VERSION ""

NS_ :

BS_:

BU_: FLZCU_VCU_EP FLZCU_PDCS_EP FLZCU_EP VCU_EP FLZCU_SignalRoute_EP BMS CDU FMCU_ISG FMCU ISG RMCU RMCU_E0V EVCC PDCS_EP PDCS_EP_E0V CIC_EP RmcuCdu RmcuCdu_E0V FmcuVcu_EP FmcuVcu_EP_E0V

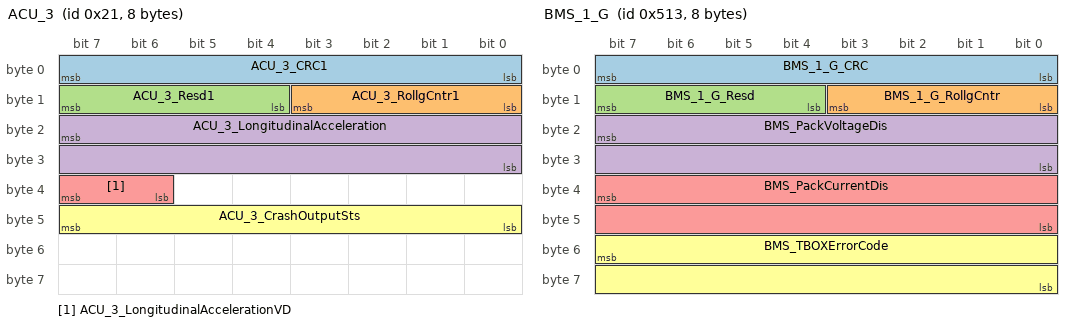
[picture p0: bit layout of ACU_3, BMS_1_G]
BO_ 33 ACU_3: 8 Vector__XXX
 SG_ ACU_3_CRC1 : 7|8@0+ (1,0) [0|255] ""  BMS,FMCU_ISG,FMCU,ISG,RMCU,RMCU_E0V,RmcuCdu,RmcuCdu_E0V,FmcuVcu_EP,FmcuVcu_EP_E0V
 SG_ ACU_3_RollgCntr1 : 11|4@0+ (1,0) [0|14] ""  BMS,FMCU_ISG,FMCU,ISG,RMCU,RMCU_E0V,RmcuCdu,RmcuCdu_E0V,FmcuVcu_EP,FmcuVcu_EP_E0V
 SG_ ACU_3_Resd1 : 15|4@0+ (1,0) [0|15] ""  BMS,FMCU_ISG,FMCU,ISG,RMCU,RMCU_E0V,RmcuCdu,RmcuCdu_E0V,FmcuVcu_EP,FmcuVcu_EP_E0V
 SG_ ACU_3_LongitudinalAcceleration : 23|16@0+ (0.001,-2) [-2|2] "g"  RMCU,RMCU_E0V,RmcuCdu,RmcuCdu_E0V
 SG_ ACU_3_LongitudinalAccelerationVD : 39|2@0+ (1,0) [0|3] ""  RMCU,RMCU_E0V,RmcuCdu,RmcuCdu_E0V
 SG_ ACU_3_CrashOutputSts : 47|8@0+ (1,0) [0|255] ""  BMS,FMCU_ISG,FMCU,ISG,RMCU,RMCU_E0V,RmcuCdu,RmcuCdu_E0V,FmcuVcu_EP,FmcuVcu_EP_E0V

BO_ 1299 BMS_1_G: 8 BMS
 SG_ BMS_1_G_CRC : 7|8@0+ (1,0) [0|255] ""  Vector__XXX
 SG_ BMS_1_G_RollgCntr : 11|4@0+ (1,0) [0|14] ""  Vector__XXX
 SG_ BMS_1_G_Resd : 15|4@0+ (1,0) [0|15] ""  Vector__XXX
 SG_ BMS_PackVoltageDis : 23|16@0+ (0.1,0.0) [0|1000] "volt (V)"  RMCU,RMCU_E0V,RmcuCdu,RmcuCdu_E0V
 SG_ BMS_PackCurrentDis : 39|16@0+ (0.1,-2047) [-2047|2047] "ampere (A)"  Vector__XXX
 SG_ BMS_TBOXErrorCode : 55|16@0+ (1,0) [0|65535] ""  Vector__XXX

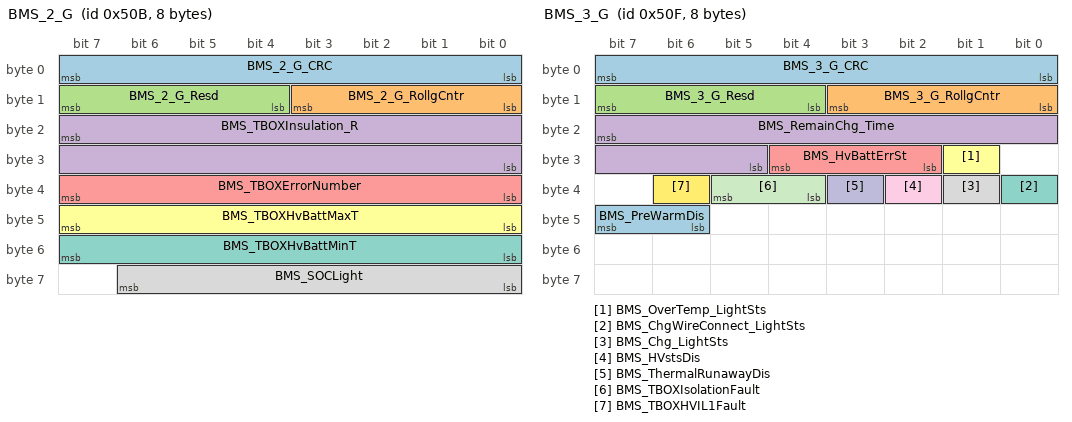
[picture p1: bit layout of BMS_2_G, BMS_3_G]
BO_ 1291 BMS_2_G: 8 BMS
 SG_ BMS_2_G_CRC : 7|8@0+ (1,0) [0|255] ""  Vector__XXX
 SG_ BMS_2_G_RollgCntr : 11|4@0+ (1,0) [0|14] ""  Vector__XXX
 SG_ BMS_2_G_Resd : 15|4@0+ (1,0) [0|15] ""  Vector__XXX
 SG_ BMS_TBOXInsulation_R : 23|16@0+ (1,0) [0|60000] "kiloohm (k��)"  Vector__XXX
 SG_ BMS_TBOXErrorNumber : 39|8@0+ (1,0) [0|255] ""  Vector__XXX
 SG_ BMS_TBOXHvBattMaxT : 47|8@0+ (1,-40) [-40|210] "grad celsius (��C)"  Vector__XXX
 SG_ BMS_TBOXHvBattMinT : 55|8@0+ (1,-40) [-40|210] "grad celsius (��C)"  Vector__XXX
 SG_ BMS_SOCLight : 62|7@0+ (1,0) [0|100] "%"  FLZCU_VCU_EP,FLZCU_PDCS_EP,FLZCU_EP

BO_ 1295 BMS_3_G: 8 BMS
 SG_ BMS_3_G_CRC : 7|8@0+ (1,0) [0|255] ""  CIC_EP
 SG_ BMS_3_G_RollgCntr : 11|4@0+ (1,0) [0|14] ""  CIC_EP
 SG_ BMS_3_G_Resd : 15|4@0+ (1,0) [0|15] ""  CIC_EP
 SG_ BMS_RemainChg_Time : 23|11@0+ (1,0) [0|2047] "min"  Vector__XXX
 SG_ BMS_HvBattErrSt : 28|3@0+ (1,0.0) [0|7] ""  Vector__XXX
 SG_ BMS_OverTemp_LightSts : 25|1@0+ (1,0) [0|1] ""  Vector__XXX
 SG_ BMS_ChgWireConnect_LightSts : 32|1@0+ (1,0) [0|1] ""  CIC_EP
 SG_ BMS_Chg_LightSts : 33|1@0+ (1,0) [0|1] ""  FLZCU_VCU_EP,FLZCU_PDCS_EP,FLZCU_EP
 SG_ BMS_HVstsDis : 34|1@0+ (1,0) [0|1] ""  Vector__XXX
 SG_ BMS_ThermalRunawayDis : 35|1@0+ (1,0) [0|1] ""  Vector__XXX
 SG_ BMS_TBOXIsolationFault : 37|2@0+ (1,0) [0|3] ""  Vector__XXX
 SG_ BMS_TBOXHVIL1Fault : 38|1@0+ (1,0) [0|1] ""  Vector__XXX
 SG_ BMS_PreWarmDis : 47|2@0+ (1,0) [0|2] ""  Vector__XXX

BO_ 258 BMS_1: 48 BMS
 SG_ BMS_1_CRC1 : 7|8@0+ (1,0) [0|255] ""  FLZCU_VCU_EP,FLZCU_PDCS_EP,VCU_EP,RMCU,RMCU_E0V,PDCS_EP,PDCS_EP_E0V,RmcuCdu,RmcuCdu_E0V,FmcuVcu_EP,FmcuVcu_EP_E0V
 SG_ BMS_1_RollgCntr1 : 11|4@0+ (1,0) [0|14] ""  FLZCU_VCU_EP,FLZCU_PDCS_EP,VCU_EP,RMCU,RMCU_E0V,PDCS_EP,PDCS_EP_E0V,RmcuCdu,RmcuCdu_E0V,FmcuVcu_EP,FmcuVcu_EP_E0V
 SG_ BMS_1_Resd1 : 15|4@0+ (1,0) [0|15] ""  FLZCU_VCU_EP,FLZCU_PDCS_EP,VCU_EP,RMCU,RMCU_E0V,PDCS_EP,PDCS_EP_E0V,RmcuCdu,RmcuCdu_E0V,FmcuVcu_EP,FmcuVcu_EP_E0V
 SG_ BMS_PackVoltage : 23|16@0+ (0.1,0) [0|1000] "volt (V)"  FLZCU_VCU_EP,FLZCU_PDCS_EP,VCU_EP,RMCU,RMCU_E0V,PDCS_EP,PDCS_EP_E0V,RmcuCdu,RmcuCdu_E0V,FmcuVcu_EP,FmcuVcu_EP_E0V
 SG_ BMS_PackCurrent : 39|16@0+ (0.1,-2047) [-2047|2047] "ampere (A)"  FLZCU_VCU_EP,FLZCU_PDCS_EP,VCU_EP,PDCS_EP,PDCS_EP_E0V,FmcuVcu_EP,FmcuVcu_EP_E0V
 SG_ BMS_HvBattSts : 51|4@0+ (1,0) [0|15] ""  FLZCU_VCU_EP,FLZCU_PDCS_EP,VCU_EP,FLZCU_SignalRoute_EP,EVCC,PDCS_EP,PDCS_EP_E0V,FmcuVcu_EP,FmcuVcu_EP_E0V
 SG_ BMS_SysSelfCheck : 53|2@0+ (1,0) [0|3] ""  FLZCU_VCU_EP,FLZCU_PDCS_EP,VCU_EP,PDCS_EP,PDCS_EP_E0V,FmcuVcu_EP,FmcuVcu_EP_E0V
 SG_ BMS_HVBattThermRunaway : 55|2@0+ (1,0) [0|3] ""  FLZCU_VCU_EP,FLZCU_PDCS_EP,FLZCU_EP,VCU_EP,FLZCU_SignalRoute_EP,PDCS_EP,PDCS_EP_E0V,FmcuVcu_EP,FmcuVcu_EP_E0V
 SG_ BMS_1_CRC2 : 71|8@0+ (1,0) [0|255] ""  FLZCU_VCU_EP,FLZCU_PDCS_EP
 SG_ BMS_1_RollgCntr2 : 75|4@0+ (1,0) [0|14] ""  FLZCU_VCU_EP,FLZCU_PDCS_EP
 SG_ BMS_1_Resd2 : 79|4@0+ (1,0) [0|15] ""  FLZCU_VCU_EP,FLZCU_PDCS_EP
 SG_ BMS_DcDisChgCurrReq : 87|12@0+ (0.1,0) [0|400] ""  FLZCU_VCU_EP,FLZCU_PDCS_EP
 SG_ BMS_C2Target_Buck_Voltage : 91|16@0+ (0.1,0) [0|1000] "V"  FLZCU_VCU_EP,FLZCU_PDCS_EP,RMCU,RMCU_E0V
 SG_ BMS_DisChrgDcCnctrDetd : 107|4@0+ (1,0) [0|15] ""  FLZCU_VCU_EP,FLZCU_PDCS_EP
 SG_ BMS_InfraDcUActDc : 119|14@0+ (0.1,0) [0|1024] "volt (V)"  FLZCU_VCU_EP,FLZCU_PDCS_EP,VCU_EP,FLZCU_SignalRoute_EP,RMCU,RMCU_E0V,PDCS_EP,PDCS_EP_E0V,RmcuCdu,RmcuCdu_E0V,FmcuVcu_EP,FmcuVcu_EP_E0V
 SG_ BMS_1_CRC3 : 135|8@0+ (1,0) [0|255] ""  FLZCU_VCU_EP,FLZCU_PDCS_EP,VCU_EP,RMCU,RMCU_E0V,PDCS_EP,PDCS_EP_E0V,RmcuCdu,RmcuCdu_E0V,FmcuVcu_EP,FmcuVcu_EP_E0V
 SG_ BMS_1_RollgCntr3 : 139|4@0+ (1,0) [0|14] ""  FLZCU_VCU_EP,FLZCU_PDCS_EP,VCU_EP,RMCU,RMCU_E0V,PDCS_EP,PDCS_EP_E0V,RmcuCdu,RmcuCdu_E0V,FmcuVcu_EP,FmcuVcu_EP_E0V
 SG_ BMS_1_Resd3 : 143|4@0+ (1,0) [0|15] ""  FLZCU_VCU_EP,FLZCU_PDCS_EP,VCU_EP,RMCU,RMCU_E0V,PDCS_EP,PDCS_EP_E0V,RmcuCdu,RmcuCdu_E0V,FmcuVcu_EP,FmcuVcu_EP_E0V
 SG_ BMS_InfraDcIActDc : 151|14@0+ (0.1,-1024) [-1024|0] "ampere (A)"  FLZCU_VCU_EP,FLZCU_PDCS_EP,VCU_EP,FLZCU_SignalRoute_EP,RMCU,RMCU_E0V,PDCS_EP,PDCS_EP_E0V,RmcuCdu,RmcuCdu_E0V,FmcuVcu_EP,FmcuVcu_EP_E0V
 SG_ BMS_HvBattDynChrgnILim : 167|14@0+ (0.1,-1024) [-1024|0] "ampere (A)"  FLZCU_VCU_EP,FLZCU_PDCS_EP,VCU_EP,FLZCU_SignalRoute_EP,PDCS_EP,PDCS_EP_E0V,FmcuVcu_EP,FmcuVcu_EP_E0V
 SG_ BMS_HvBattUChrgnLim : 183|14@0+ (0.1,0) [0|1024] "volt (V)"  FLZCU_VCU_EP,FLZCU_PDCS_EP,VCU_EP,FLZCU_SignalRoute_EP,RMCU,RMCU_E0V,PDCS_EP,PDCS_EP_E0V,RmcuCdu,RmcuCdu_E0V,FmcuVcu_EP,FmcuVcu_EP_E0V
 SG_ BMS_1_CRC4 : 199|8@0+ (1,0) [0|255] ""  FLZCU_VCU_EP,FLZCU_PDCS_EP,VCU_EP,PDCS_EP,PDCS_EP_E0V,FmcuVcu_EP,FmcuVcu_EP_E0V
 SG_ BMS_1_RollgCntr4 : 203|4@0+ (1,0) [0|14] ""  FLZCU_VCU_EP,FLZCU_PDCS_EP,VCU_EP,PDCS_EP,PDCS_EP_E0V,FmcuVcu_EP,FmcuVcu_EP_E0V
 SG_ BMS_1_Resd4 : 207|4@0+ (1,0) [0|15] ""  FLZCU_VCU_EP,FLZCU_PDCS_EP,VCU_EP,PDCS_EP,PDCS_EP_E0V,FmcuVcu_EP,FmcuVcu_EP_E0V
 SG_ BMS_ChrgDcIAvl : 215|14@0+ (0.1,-1024) [-1024|0] "ampere (A)"  FLZCU_VCU_EP,FLZCU_PDCS_EP,VCU_EP,PDCS_EP,PDCS_EP_E0V,FmcuVcu_EP,FmcuVcu_EP_E0V
 SG_ BMS_DChrgAPlusSt : 217|1@0+ (1,0) [0|1] ""  FLZCU_VCU_EP,FLZCU_PDCS_EP,VCU_EP,PDCS_EP,PDCS_EP_E0V,FmcuVcu_EP,FmcuVcu_EP_E0V
 SG_ BMS_Insulation_R : 231|16@0+ (1,0) [0|60000] "kiloohm (k��)"  FLZCU_VCU_EP,FLZCU_PDCS_EP,VCU_EP,PDCS_EP,PDCS_EP_E0V,FmcuVcu_EP,FmcuVcu_EP_E0V
 SG_ BMS_ChrgDcCnctrDetd : 241|2@0+ (1,0) [0|3] ""  FLZCU_VCU_EP,FLZCU_PDCS_EP,FLZCU_EP,VCU_EP,FLZCU_SignalRoute_EP,PDCS_EP,PDCS_EP_E0V,FmcuVcu_EP,FmcuVcu_EP_E0V
 SG_ BMS_DCChgMode : 244|3@0+ (1,0) [0|7] ""  FLZCU_VCU_EP,FLZCU_PDCS_EP,VCU_EP,FLZCU_SignalRoute_EP,PDCS_EP,PDCS_EP_E0V,FmcuVcu_EP,FmcuVcu_EP_E0V
 SG_ BMS_ChrgDcChrgnFltStopReas : 247|3@0+ (1.0,0) [0|7] ""  FLZCU_VCU_EP,FLZCU_PDCS_EP,VCU_EP,PDCS_EP,PDCS_EP_E0V,FmcuVcu_EP,FmcuVcu_EP_E0V
 SG_ BMS_1_CRC5 : 263|8@0+ (1,0) [0|255] ""  FLZCU_VCU_EP,FLZCU_PDCS_EP,VCU_EP,PDCS_EP,PDCS_EP_E0V,FmcuVcu_EP,FmcuVcu_EP_E0V
 SG_ BMS_1_RollgCntr5 : 267|4@0+ (1,0) [0|14] ""  FLZCU_VCU_EP,FLZCU_PDCS_EP,VCU_EP,PDCS_EP,PDCS_EP_E0V,FmcuVcu_EP,FmcuVcu_EP_E0V
 SG_ BMS_1_Resd5 : 271|4@0+ (1,0) [0|15] ""  FLZCU_VCU_EP,FLZCU_PDCS_EP,VCU_EP,PDCS_EP,PDCS_EP_E0V,FmcuVcu_EP,FmcuVcu_EP_E0V
 SG_ BMS_ChgRemTime : 279|11@0+ (1,0) [0|1440] "min"  FLZCU_VCU_EP,FLZCU_PDCS_EP,VCU_EP,FLZCU_SignalRoute_EP,PDCS_EP,PDCS_EP_E0V,FmcuVcu_EP,FmcuVcu_EP_E0V
 SG_ BMS_ChargeRequest_Mode : 284|4@0+ (1,0) [0|15] ""  FLZCU_VCU_EP,FLZCU_PDCS_EP,VCU_EP,FLZCU_SignalRoute_EP,PDCS_EP,PDCS_EP_E0V,FmcuVcu_EP,FmcuVcu_EP_E0V
 SG_ BMS_StateOfChargeDis : 295|8@0+ (1,0) [0|100] "%"  FLZCU_VCU_EP,FLZCU_PDCS_EP,FLZCU_EP,VCU_EP,FLZCU_SignalRoute_EP,EVCC,PDCS_EP,PDCS_EP_E0V,FmcuVcu_EP,FmcuVcu_EP_E0V
 SG_ BMS_StateOfEnergy : 311|16@0+ (0.1,0) [0|999.9] "kWh"  FLZCU_VCU_EP,FLZCU_PDCS_EP,VCU_EP,PDCS_EP,PDCS_EP_E0V,FmcuVcu_EP,FmcuVcu_EP_E0V
 SG_ BMS_1_CRC6 : 327|8@0+ (1,0) [0|255] ""  FLZCU_VCU_EP,FLZCU_PDCS_EP,VCU_EP,PDCS_EP,PDCS_EP_E0V,FmcuVcu_EP,FmcuVcu_EP_E0V
 SG_ BMS_1_RollgCntr6 : 331|4@0+ (1,0) [0|14] ""  FLZCU_VCU_EP,FLZCU_PDCS_EP,VCU_EP,PDCS_EP,PDCS_EP_E0V,FmcuVcu_EP,FmcuVcu_EP_E0V
 SG_ BMS_1_Resd6 : 335|4@0+ (1,0) [0|15] ""  FLZCU_VCU_EP,FLZCU_PDCS_EP,VCU_EP,PDCS_EP,PDCS_EP_E0V,FmcuVcu_EP,FmcuVcu_EP_E0V
 SG_ BMS_StateOfHealth : 342|7@0+ (1,0) [0|100] ""  FLZCU_VCU_EP,FLZCU_PDCS_EP,VCU_EP,FLZCU_SignalRoute_EP,PDCS_EP,PDCS_EP_E0V,FmcuVcu_EP,FmcuVcu_EP_E0V
 SG_ BMS_BlanceState : 343|1@0+ (1,0) [0|1] ""  FLZCU_VCU_EP,FLZCU_PDCS_EP,VCU_EP,FLZCU_SignalRoute_EP,PDCS_EP,PDCS_EP_E0V,FmcuVcu_EP,FmcuVcu_EP_E0V
 SG_ BMS_IsolationFault : 345|2@0+ (1,0) [0|3] ""  FLZCU_VCU_EP,FLZCU_PDCS_EP,VCU_EP,FLZCU_SignalRoute_EP,PDCS_EP,PDCS_EP_E0V,FmcuVcu_EP,FmcuVcu_EP_E0V
 SG_ BMS_HVILFault_DC : 346|1@0+ (1,0) [0|1] ""  FLZCU_VCU_EP,FLZCU_PDCS_EP,VCU_EP,PDCS_EP,PDCS_EP_E0V,FmcuVcu_EP,FmcuVcu_EP_E0V
 SG_ BMS_HVILFault_FMCU : 347|1@0+ (1,0) [0|1] ""  FLZCU_VCU_EP,FLZCU_PDCS_EP,VCU_EP,PDCS_EP,PDCS_EP_E0V,FmcuVcu_EP,FmcuVcu_EP_E0V
 SG_ BMS_HVILFault_RMCU : 348|1@0+ (1,0) [0|1] ""  FLZCU_VCU_EP,FLZCU_PDCS_EP,VCU_EP,PDCS_EP,PDCS_EP_E0V,FmcuVcu_EP,FmcuVcu_EP_E0V
 SG_ BMS_SOCDis : 359|14@0+ (0.01,0) [0|100] "%"  FLZCU_VCU_EP,FLZCU_PDCS_EP,VCU_EP,PDCS_EP,PDCS_EP_E0V,FmcuVcu_EP,FmcuVcu_EP_E0V
 SG_ BMS_InfraDcIActDcMin : 375|14@0+ (0.1,-1024) [-1024|0] "ampere (A)"  FLZCU_VCU_EP,FLZCU_PDCS_EP,VCU_EP,PDCS_EP,PDCS_EP_E0V,FmcuVcu_EP,FmcuVcu_EP_E0V

BO_ 520 BMS_2: 48 BMS
 SG_ BMS_2_CRC1 : 7|8@0+ (1,0) [0|255] ""  FLZCU_VCU_EP,FLZCU_PDCS_EP,RMCU,RMCU_E0V,RmcuCdu,RmcuCdu_E0V
 SG_ BMS_2_RollgCntr1 : 11|4@0+ (1,0) [0|14] ""  FLZCU_VCU_EP,FLZCU_PDCS_EP,RMCU,RMCU_E0V,RmcuCdu,RmcuCdu_E0V
 SG_ BMS_2_Resd1 : 15|4@0+ (1,0) [0|15] ""  FLZCU_VCU_EP,FLZCU_PDCS_EP,RMCU,RMCU_E0V,RmcuCdu,RmcuCdu_E0V
 SG_ BMS_C2Target_Chg_Voltage : 23|16@0+ (0.1,0) [0|1000] "V"  FLZCU_VCU_EP,FLZCU_PDCS_EP,VCU_EP,RMCU,RMCU_E0V,PDCS_EP,PDCS_EP_E0V,RmcuCdu,RmcuCdu_E0V,FmcuVcu_EP,FmcuVcu_EP_E0V
 SG_ BMS_CHGstation_MAXPwr : 39|8@0+ (2,0) [0|510] "KW"  FLZCU_VCU_EP,FLZCU_PDCS_EP,VCU_EP,PDCS_EP,PDCS_EP_E0V,FmcuVcu_EP,FmcuVcu_EP_E0V
 SG_ BMS_2_CRC2 : 71|8@0+ (1,0) [0|255] ""  FLZCU_VCU_EP,FLZCU_PDCS_EP,VCU_EP,CDU,PDCS_EP,PDCS_EP_E0V,RmcuCdu,RmcuCdu_E0V,FmcuVcu_EP,FmcuVcu_EP_E0V
 SG_ BMS_2_RollgCntr2 : 75|4@0+ (1,0) [0|14] ""  FLZCU_VCU_EP,FLZCU_PDCS_EP,VCU_EP,CDU,PDCS_EP,PDCS_EP_E0V,RmcuCdu,RmcuCdu_E0V,FmcuVcu_EP,FmcuVcu_EP_E0V
 SG_ BMS_2_Resd2 : 79|4@0+ (1,0) [0|15] ""  FLZCU_VCU_EP,FLZCU_PDCS_EP,VCU_EP,CDU,PDCS_EP,PDCS_EP_E0V,RmcuCdu,RmcuCdu_E0V,FmcuVcu_EP,FmcuVcu_EP_E0V
 SG_ BMS_NV_relay_Sts : 84|3@0+ (1,0) [0|6] ""  FLZCU_VCU_EP,FLZCU_PDCS_EP,VCU_EP,CDU,PDCS_EP,PDCS_EP_E0V,RmcuCdu,RmcuCdu_E0V,FmcuVcu_EP,FmcuVcu_EP_E0V
 SG_ BMS_PV_relay_Sts : 87|3@0+ (1,0) [0|6] ""  FLZCU_VCU_EP,FLZCU_PDCS_EP,VCU_EP,CDU,PDCS_EP,PDCS_EP_E0V,RmcuCdu,RmcuCdu_E0V,FmcuVcu_EP,FmcuVcu_EP_E0V
 SG_ BMS_QCP_relay_Sts : 90|3@0+ (1,0) [0|6] ""  FLZCU_VCU_EP,FLZCU_PDCS_EP,VCU_EP,CDU,PDCS_EP,PDCS_EP_E0V,RmcuCdu,RmcuCdu_E0V,FmcuVcu_EP,FmcuVcu_EP_E0V
 SG_ BMS_QCN_relay_Sts : 93|3@0+ (1,0) [0|6] ""  FLZCU_VCU_EP,FLZCU_PDCS_EP,VCU_EP,CDU,PDCS_EP,PDCS_EP_E0V,RmcuCdu,RmcuCdu_E0V,FmcuVcu_EP,FmcuVcu_EP_E0V
 SG_ BMS_HvBattThermReqLevel : 81|4@0+ (1,0) [0|15] ""  FLZCU_VCU_EP,FLZCU_PDCS_EP,VCU_EP,FLZCU_SignalRoute_EP,PDCS_EP,PDCS_EP_E0V,FmcuVcu_EP,FmcuVcu_EP_E0V
 SG_ BMS_Prechage_relay_Sts : 98|3@0+ (1,0) [0|6] ""  FLZCU_VCU_EP,FLZCU_PDCS_EP,VCU_EP,PDCS_EP,PDCS_EP_E0V,FmcuVcu_EP,FmcuVcu_EP_E0V
 SG_ BMS_HvBattThermReqMode : 103|4@0+ (1,0) [0|15] ""  FLZCU_VCU_EP,FLZCU_PDCS_EP,VCU_EP,FLZCU_SignalRoute_EP,PDCS_EP,PDCS_EP_E0V,FmcuVcu_EP,FmcuVcu_EP_E0V
 SG_ BMS_ClntTHvBattIn : 111|8@0+ (1,-40) [-40|120] "grad celsius (��C)"  FLZCU_VCU_EP,FLZCU_PDCS_EP,VCU_EP,FLZCU_SignalRoute_EP,PDCS_EP,PDCS_EP_E0V,FmcuVcu_EP,FmcuVcu_EP_E0V
 SG_ BMS_ClntTHvBattOut : 119|8@0+ (1,-40) [-40|120] "grad celsius (��C)"  FLZCU_VCU_EP,FLZCU_PDCS_EP,VCU_EP,FLZCU_SignalRoute_EP,PDCS_EP,PDCS_EP_E0V,FmcuVcu_EP,FmcuVcu_EP_E0V
 SG_ BMS_HvBattClntInTReq : 127|7@0+ (1,-40) [-40|53] "grad celsius (��C)"  FLZCU_VCU_EP,FLZCU_PDCS_EP,VCU_EP,FLZCU_SignalRoute_EP,PDCS_EP,PDCS_EP_E0V,FmcuVcu_EP,FmcuVcu_EP_E0V
 SG_ BMS_2_CRC3 : 135|8@0+ (1,0) [0|255] ""  FLZCU_VCU_EP,FLZCU_PDCS_EP,VCU_EP,PDCS_EP,PDCS_EP_E0V,FmcuVcu_EP,FmcuVcu_EP_E0V
 SG_ BMS_2_RollgCntr3 : 139|4@0+ (1,0) [0|14] ""  FLZCU_VCU_EP,FLZCU_PDCS_EP,VCU_EP,PDCS_EP,PDCS_EP_E0V,FmcuVcu_EP,FmcuVcu_EP_E0V
 SG_ BMS_2_Resd3 : 143|4@0+ (1,0) [0|15] ""  FLZCU_VCU_EP,FLZCU_PDCS_EP,VCU_EP,PDCS_EP,PDCS_EP_E0V,FmcuVcu_EP,FmcuVcu_EP_E0V
 SG_ BMS_HvBattClntFlowReq : 151|7@0+ (0.25,0) [0|31] "flow-rate (l/min)"  FLZCU_VCU_EP,FLZCU_PDCS_EP,VCU_EP,FLZCU_SignalRoute_EP,PDCS_EP,PDCS_EP_E0V,FmcuVcu_EP,FmcuVcu_EP_E0V
 SG_ BMS_HvBattAvgT : 159|8@0+ (1,-40) [-40|120] "grad celsius (��C)"  FLZCU_VCU_EP,FLZCU_PDCS_EP,VCU_EP,FLZCU_SignalRoute_EP,PDCS_EP,PDCS_EP_E0V,FmcuVcu_EP,FmcuVcu_EP_E0V
 SG_ BMS_HvBattMaxT : 167|8@0+ (1,-40) [-40|210] "grad celsius (��C)"  FLZCU_VCU_EP,FLZCU_PDCS_EP,VCU_EP,FLZCU_SignalRoute_EP,PDCS_EP,PDCS_EP_E0V,FmcuVcu_EP,FmcuVcu_EP_E0V
 SG_ BMS_HvBattMinT : 175|8@0+ (1,-40) [-40|210] "grad celsius (��C)"  FLZCU_VCU_EP,FLZCU_PDCS_EP,VCU_EP,FLZCU_SignalRoute_EP,PDCS_EP,PDCS_EP_E0V,FmcuVcu_EP,FmcuVcu_EP_E0V
 SG_ BMS_HvBattTdiff : 183|7@0+ (1,0) [0|127] "grad celsius (��C)"  FLZCU_VCU_EP,FLZCU_PDCS_EP,VCU_EP,PDCS_EP,PDCS_EP_E0V,FmcuVcu_EP,FmcuVcu_EP_E0V
 SG_ BMS_2_CRC4 : 199|8@0+ (1,0) [0|255] ""  FLZCU_VCU_EP,FLZCU_PDCS_EP,VCU_EP,PDCS_EP,PDCS_EP_E0V,FmcuVcu_EP,FmcuVcu_EP_E0V
 SG_ BMS_2_RollgCntr4 : 203|4@0+ (1,0) [0|14] ""  FLZCU_VCU_EP,FLZCU_PDCS_EP,VCU_EP,PDCS_EP,PDCS_EP_E0V,FmcuVcu_EP,FmcuVcu_EP_E0V
 SG_ BMS_2_Resd4 : 207|4@0+ (1,0) [0|15] ""  FLZCU_VCU_EP,FLZCU_PDCS_EP,VCU_EP,PDCS_EP,PDCS_EP_E0V,FmcuVcu_EP,FmcuVcu_EP_E0V
 SG_ BMS_OutPosU : 223|14@0+ (0.1,0) [0|1023.0] "volt (V)"  FLZCU_VCU_EP,FLZCU_PDCS_EP,VCU_EP,PDCS_EP,PDCS_EP_E0V,FmcuVcu_EP,FmcuVcu_EP_E0V
 SG_ BMS_OutNegU : 239|14@0+ (0.1,0) [0|1023.0] "volt (V)"  FLZCU_VCU_EP,FLZCU_PDCS_EP,VCU_EP,PDCS_EP,PDCS_EP_E0V,FmcuVcu_EP,FmcuVcu_EP_E0V
 SG_ BMS_ChrgTrgtSOC : 255|7@0+ (1,0) [0|100] "%"  FLZCU_VCU_EP,FLZCU_PDCS_EP,PDCS_EP,PDCS_EP_E0V,FmcuVcu_EP,FmcuVcu_EP_E0V
 SG_ BMS_2_CRC5 : 263|8@0+ (1,0) [0|255] ""  FLZCU_VCU_EP,FLZCU_PDCS_EP,VCU_EP,PDCS_EP,PDCS_EP_E0V,FmcuVcu_EP,FmcuVcu_EP_E0V
 SG_ BMS_2_RollgCntr5 : 267|4@0+ (1,0) [0|14] ""  FLZCU_VCU_EP,FLZCU_PDCS_EP,VCU_EP,PDCS_EP,PDCS_EP_E0V,FmcuVcu_EP,FmcuVcu_EP_E0V
 SG_ BMS_2_Resd5 : 271|4@0+ (1,0) [0|15] ""  FLZCU_VCU_EP,FLZCU_PDCS_EP,VCU_EP,PDCS_EP,PDCS_EP_E0V,FmcuVcu_EP,FmcuVcu_EP_E0V
 SG_ BMS_outQCPosU : 279|14@0+ (0.1,0) [0|1023.0] "volt (V)"  FLZCU_VCU_EP,FLZCU_PDCS_EP,VCU_EP,PDCS_EP,PDCS_EP_E0V,FmcuVcu_EP,FmcuVcu_EP_E0V
 SG_ BMS_outQCNegU : 295|14@0+ (0.1,0) [0|1023.0] "volt (V)"  FLZCU_VCU_EP,FLZCU_PDCS_EP,VCU_EP,PDCS_EP,PDCS_EP_E0V,FmcuVcu_EP,FmcuVcu_EP_E0V
 SG_ BMS_Middlesplit_relay_Sts : 311|3@0+ (1,0) [0|7] ""  FLZCU_VCU_EP,FLZCU_PDCS_EP,VCU_EP,PDCS_EP,PDCS_EP_E0V,FmcuVcu_EP,FmcuVcu_EP_E0V
 SG_ BMS_DCChrgSts : 308|5@0+ (1,0) [0|31] ""  FLZCU_VCU_EP,FLZCU_PDCS_EP,VCU_EP,PDCS_EP,PDCS_EP_E0V,FmcuVcu_EP,FmcuVcu_EP_E0V
 SG_ BMS_ACChrgSts : 319|5@0+ (1,0) [0|31] ""  FLZCU_VCU_EP,FLZCU_PDCS_EP,VCU_EP,PDCS_EP,PDCS_EP_E0V,FmcuVcu_EP,FmcuVcu_EP_E0V
 SG_ BMS_BattCurrtSnsr1 : 343|15@0+ (0.1,-1000) [-1000|2000] "A"  FLZCU_VCU_EP,FLZCU_PDCS_EP,VCU_EP,PDCS_EP,PDCS_EP_E0V,FmcuVcu_EP,FmcuVcu_EP_E0V
 SG_ BMS_BattCurrtSnsr2 : 359|15@0+ (0.1,-1000) [-1000|2000] "A"  FLZCU_VCU_EP,FLZCU_PDCS_EP,VCU_EP,PDCS_EP,PDCS_EP_E0V,FmcuVcu_EP,FmcuVcu_EP_E0V
 SG_ BMS_SOHCapFade : 375|8@0+ (0.5,0) [0|100] "%"  FLZCU_VCU_EP,FLZCU_PDCS_EP,VCU_EP,PDCS_EP,PDCS_EP_E0V,FmcuVcu_EP,FmcuVcu_EP_E0V
 SG_ BMS_SOHResInc : 383|8@0+ (0.5,0) [0|100] "%"  FLZCU_VCU_EP,FLZCU_PDCS_EP,VCU_EP,PDCS_EP,PDCS_EP_E0V,FmcuVcu_EP,FmcuVcu_EP_E0V

BO_ 523 BMS_3: 48 BMS
 SG_ BMS_3_CRC1 : 7|8@0+ (1,0) [0|255] ""  FLZCU_VCU_EP,FLZCU_PDCS_EP,VCU_EP,PDCS_EP,PDCS_EP_E0V,FmcuVcu_EP,FmcuVcu_EP_E0V
 SG_ BMS_3_RollgCntr1 : 11|4@0+ (1,0) [0|14] ""  FLZCU_VCU_EP,FLZCU_PDCS_EP,VCU_EP,PDCS_EP,PDCS_EP_E0V,FmcuVcu_EP,FmcuVcu_EP_E0V
 SG_ BMS_3_Resd1 : 15|4@0+ (1,0) [0|15] ""  FLZCU_VCU_EP,FLZCU_PDCS_EP,VCU_EP,PDCS_EP,PDCS_EP_E0V,FmcuVcu_EP,FmcuVcu_EP_E0V
 SG_ BMS_HvBattPMaxReChrgLim : 39|14@0+ (0.1,0) [0|1024] "kW"  FLZCU_VCU_EP,FLZCU_PDCS_EP,VCU_EP,FLZCU_SignalRoute_EP,PDCS_EP,PDCS_EP_E0V,FmcuVcu_EP,FmcuVcu_EP_E0V
 SG_ BMS_3_CRC2 : 71|8@0+ (1,0) [0|255] ""  FLZCU_VCU_EP,FLZCU_PDCS_EP,VCU_EP,PDCS_EP,PDCS_EP_E0V,FmcuVcu_EP,FmcuVcu_EP_E0V
 SG_ BMS_3_RollgCntr2 : 75|4@0+ (1,0) [0|14] ""  FLZCU_VCU_EP,FLZCU_PDCS_EP,VCU_EP,PDCS_EP,PDCS_EP_E0V,FmcuVcu_EP,FmcuVcu_EP_E0V
 SG_ BMS_3_Resd2 : 79|4@0+ (1,0) [0|15] ""  FLZCU_VCU_EP,FLZCU_PDCS_EP,VCU_EP,PDCS_EP,PDCS_EP_E0V,FmcuVcu_EP,FmcuVcu_EP_E0V
 SG_ BMS_HvBattIMaxReChrgLim : 87|11@0+ (1,-2047) [-2047|0] "ampere (A)"  FLZCU_VCU_EP,FLZCU_PDCS_EP,VCU_EP,FLZCU_SignalRoute_EP,PDCS_EP,PDCS_EP_E0V,FmcuVcu_EP,FmcuVcu_EP_E0V
 SG_ BMS_HvBattPMaxDchaLim : 119|14@0+ (0.1,0) [0|1024] "kW"  FLZCU_VCU_EP,FLZCU_PDCS_EP,VCU_EP,FLZCU_SignalRoute_EP,PDCS_EP,PDCS_EP_E0V,FmcuVcu_EP,FmcuVcu_EP_E0V
 SG_ BMS_3_CRC3 : 135|8@0+ (1,0) [0|255] ""  FLZCU_VCU_EP,FLZCU_PDCS_EP,VCU_EP,PDCS_EP,PDCS_EP_E0V,FmcuVcu_EP,FmcuVcu_EP_E0V
 SG_ BMS_3_RollgCntr3 : 139|4@0+ (1,0) [0|14] ""  FLZCU_VCU_EP,FLZCU_PDCS_EP,VCU_EP,PDCS_EP,PDCS_EP_E0V,FmcuVcu_EP,FmcuVcu_EP_E0V
 SG_ BMS_3_Resd3 : 143|4@0+ (1,0) [0|15] ""  FLZCU_VCU_EP,FLZCU_PDCS_EP,VCU_EP,PDCS_EP,PDCS_EP_E0V,FmcuVcu_EP,FmcuVcu_EP_E0V
 SG_ BMS_HvBattIMaxDchaLim : 167|11@0+ (1,0) [0|2047] "ampere (A)"  FLZCU_VCU_EP,FLZCU_PDCS_EP,VCU_EP,FLZCU_SignalRoute_EP,PDCS_EP,PDCS_EP_E0V,FmcuVcu_EP,FmcuVcu_EP_E0V
 SG_ BMS_3_CRC4 : 199|8@0+ (1,0) [0|255] ""  FLZCU_VCU_EP,FLZCU_PDCS_EP
 SG_ BMS_3_RollgCntr4 : 203|4@0+ (1,0) [0|14] ""  FLZCU_VCU_EP,FLZCU_PDCS_EP
 SG_ BMS_3_Resd4 : 207|4@0+ (1,0) [0|15] ""  FLZCU_VCU_EP,FLZCU_PDCS_EP
 SG_ BMS_3_CRC5 : 263|8@0+ (1,0) [0|255] ""  FLZCU_VCU_EP,FLZCU_PDCS_EP,VCU_EP,PDCS_EP,PDCS_EP_E0V,FmcuVcu_EP,FmcuVcu_EP_E0V
 SG_ BMS_3_RollgCntr5 : 267|4@0+ (1,0) [0|14] ""  FLZCU_VCU_EP,FLZCU_PDCS_EP,VCU_EP,PDCS_EP,PDCS_EP_E0V,FmcuVcu_EP,FmcuVcu_EP_E0V
 SG_ BMS_3_Resd5 : 271|4@0+ (1,0) [0|15] ""  FLZCU_VCU_EP,FLZCU_PDCS_EP,VCU_EP,PDCS_EP,PDCS_EP_E0V,FmcuVcu_EP,FmcuVcu_EP_E0V
 SG_ BMS_KL30Volt : 279|11@0+ (0.01,0) [0|20] "volt (V)"  FLZCU_VCU_EP,FLZCU_PDCS_EP,VCU_EP,PDCS_EP,PDCS_EP_E0V,FmcuVcu_EP,FmcuVcu_EP_E0V
 SG_ BMS_kL87Volt : 295|11@0+ (0.01,0) [0|20] "volt (V)"  FLZCU_VCU_EP,FLZCU_PDCS_EP,VCU_EP,PDCS_EP,PDCS_EP_E0V,FmcuVcu_EP,FmcuVcu_EP_E0V
 SG_ BMS_HvBattUDchaLim : 311|14@0+ (0.1,0) [0|1024] "volt (V)"  FLZCU_VCU_EP,FLZCU_PDCS_EP,VCU_EP,PDCS_EP,PDCS_EP_E0V,FmcuVcu_EP,FmcuVcu_EP_E0V
 SG_ BMS_3_CRC6 : 327|8@0+ (1,0) [0|255] ""  FLZCU_VCU_EP,FLZCU_PDCS_EP
 SG_ BMS_3_RollgCntr6 : 331|4@0+ (1,0) [0|14] ""  FLZCU_VCU_EP,FLZCU_PDCS_EP
 SG_ BMS_3_Resd6 : 335|4@0+ (1,0) [0|15] ""  FLZCU_VCU_EP,FLZCU_PDCS_EP
 SG_ BMSH_MaxChgPwrPeak : 343|12@0+ (0.1,0) [0|320] "KW"  FLZCU_VCU_EP,FLZCU_PDCS_EP,VCU_EP,PDCS_EP,PDCS_EP_E0V,FmcuVcu_EP,FmcuVcu_EP_E0V
 SG_ BMSH_MaxDchgPwrPeak : 347|12@0+ (0.1,0) [0|320] "KW"  FLZCU_VCU_EP,FLZCU_PDCS_EP,VCU_EP,PDCS_EP,PDCS_EP_E0V,FmcuVcu_EP,FmcuVcu_EP_E0V
 SG_ BMS_PackSOCAct : 367|10@0+ (0.1,0) [0|100] "%"  FLZCU_VCU_EP,FLZCU_PDCS_EP,VCU_EP,PDCS_EP,PDCS_EP_E0V,FmcuVcu_EP,FmcuVcu_EP_E0V
 SG_ BMS_PackSOCCalc : 373|10@0+ (0.1,0) [0|100] "%"  FLZCU_VCU_EP,FLZCU_PDCS_EP,VCU_EP,PDCS_EP,PDCS_EP_E0V,FmcuVcu_EP,FmcuVcu_EP_E0V

BO_ 1055 BMS_4: 16 BMS
 SG_ BMS_4_CRC1 : 7|8@0+ (1,0) [0|255] ""  FLZCU_VCU_EP,FLZCU_PDCS_EP
 SG_ BMS_4_RollgCntr1 : 11|4@0+ (1,0) [0|14] ""  FLZCU_VCU_EP,FLZCU_PDCS_EP
 SG_ BMS_4_Resd1 : 15|4@0+ (1,0) [0|15] ""  FLZCU_VCU_EP,FLZCU_PDCS_EP
 SG_ BMS_ErrorNumber : 47|8@0+ (1,0) [0|255] ""  FLZCU_VCU_EP,FLZCU_PDCS_EP,VCU_EP,PDCS_EP,PDCS_EP_E0V,FmcuVcu_EP,FmcuVcu_EP_E0V
 SG_ BMS_ErrorCode : 55|16@0+ (1,0) [0|65535] ""  FLZCU_VCU_EP,FLZCU_PDCS_EP,VCU_EP,PDCS_EP,PDCS_EP_E0V,FmcuVcu_EP,FmcuVcu_EP_E0V
 SG_ BMS_4_CRC2 : 71|8@0+ (1,0) [0|255] ""  FLZCU_VCU_EP,FLZCU_PDCS_EP,VCU_EP,PDCS_EP,PDCS_EP_E0V,FmcuVcu_EP,FmcuVcu_EP_E0V
 SG_ BMS_4_RollgCntr2 : 75|4@0+ (1,0) [0|14] ""  FLZCU_VCU_EP,FLZCU_PDCS_EP,VCU_EP,PDCS_EP,PDCS_EP_E0V,FmcuVcu_EP,FmcuVcu_EP_E0V
 SG_ BMS_4_Resd2 : 79|4@0+ (1,0) [0|15] ""  FLZCU_VCU_EP,FLZCU_PDCS_EP,VCU_EP,PDCS_EP,PDCS_EP_E0V,FmcuVcu_EP,FmcuVcu_EP_E0V
 SG_ BMSH_MILReq : 80|1@0+ (1,0) [0|1] ""  FLZCU_VCU_EP,FLZCU_PDCS_EP,VCU_EP,PDCS_EP,PDCS_EP_E0V,FmcuVcu_EP,FmcuVcu_EP_E0V
 SG_ BMS_ErrorLevel : 87|4@0+ (1,0) [0|9] ""  FLZCU_VCU_EP,FLZCU_PDCS_EP,VCU_EP,PDCS_EP,PDCS_EP_E0V,FmcuVcu_EP,FmcuVcu_EP_E0V
 SG_ BMS_HvBattUnderTemperature : 83|1@0+ (1,0) [0|1] ""  FLZCU_VCU_EP,FLZCU_PDCS_EP,VCU_EP,PDCS_EP,PDCS_EP_E0V,FmcuVcu_EP,FmcuVcu_EP_E0V
 SG_ BMS_ThermRunCode : 95|8@0+ (1,0) [0|255] ""  FLZCU_VCU_EP,FLZCU_PDCS_EP,VCU_EP,PDCS_EP,PDCS_EP_E0V,FmcuVcu_EP,FmcuVcu_EP_E0V
 SG_ BMS_DChrgEndCode : 103|8@0+ (1,0) [0|255] ""  FLZCU_VCU_EP,FLZCU_PDCS_EP,VCU_EP,PDCS_EP,PDCS_EP_E0V,FmcuVcu_EP,FmcuVcu_EP_E0V
 SG_ BMS_PwrDerateFlg : 111|2@0+ (1,0) [0|3] ""  FLZCU_VCU_EP,FLZCU_PDCS_EP,VCU_EP,PDCS_EP,PDCS_EP_E0V,FmcuVcu_EP,FmcuVcu_EP_E0V
 SG_ BMS_CHGstation_LowPWRFlg : 109|2@0+ (1,0) [0|3] ""  FLZCU_VCU_EP,FLZCU_PDCS_EP
 SG_ BMS_bHint4FullChrgFlg : 107|1@0+ (1,0) [0|1] ""  FLZCU_VCU_EP,FLZCU_PDCS_EP
 SG_ BMS_StateOfChargeDis : 119|8@0+ (1,0) [0|100] "%"  FLZCU_VCU_EP,FLZCU_PDCS_EP,VCU_EP
 SG_ BMS_FastChargingFlg : 127|2@0+ (1,0) [0|3] ""  FLZCU_VCU_EP,FLZCU_PDCS_EP,VCU_EP,PDCS_EP,PDCS_EP_E0V,FmcuVcu_EP,FmcuVcu_EP_E0V
 SG_ BMS_LowCellVltChrgFlg : 125|2@0+ (1,0) [0|3] ""  FLZCU_VCU_EP,FLZCU_PDCS_EP,VCU_EP,PDCS_EP,PDCS_EP_E0V,FmcuVcu_EP,FmcuVcu_EP_E0V
 SG_ BMS_EngineStartReq : 123|2@0+ (1,0) [0|3] ""  FLZCU_VCU_EP,FLZCU_PDCS_EP,VCU_EP,PDCS_EP,PDCS_EP_E0V,FmcuVcu_EP,FmcuVcu_EP_E0V

BO_ 1525 BMS_5: 8 BMS
 SG_ BMS_SoftWareVersion : 7|64@0+ (1,0) [0|18446744073709551615] ""  FLZCU_VCU_EP,FLZCU_PDCS_EP,VCU_EP,PDCS_EP,PDCS_EP_E0V,FmcuVcu_EP,FmcuVcu_EP_E0V

BO_ 811 BMS_6: 16 BMS
 SG_ BMS_6_CRC1 : 7|8@0+ (1,0) [0|255] ""  FLZCU_VCU_EP,FLZCU_PDCS_EP
 SG_ BMS_6_RollgCntr1 : 11|4@0+ (1,0) [0|14] ""  FLZCU_VCU_EP,FLZCU_PDCS_EP
 SG_ BMS_6_Resd1 : 15|4@0+ (1,0) [0|15] ""  FLZCU_VCU_EP,FLZCU_PDCS_EP
 SG_ BMS_HvBattCellVoltMax_Num : 23|8@0+ (1,0) [0|250.0] "bit"  FLZCU_VCU_EP,FLZCU_PDCS_EP
 SG_ BMS_HvBattCellVoltMax : 31|16@0+ (0.001,0) [0|15] "V"  FLZCU_VCU_EP,FLZCU_PDCS_EP
 SG_ BMS_HvBattCellVoltMin_Num : 47|8@0+ (1,0) [0|250.0] "bit"  FLZCU_VCU_EP,FLZCU_PDCS_EP
 SG_ BMS_HvBattCellVoltMin : 55|16@0+ (0.001,0) [0|15] "V"  FLZCU_VCU_EP,FLZCU_PDCS_EP
 SG_ BMS_6_CRC2 : 71|8@0+ (1,0) [0|255] ""  FLZCU_VCU_EP,FLZCU_PDCS_EP
 SG_ BMS_6_RollgCntr2 : 75|4@0+ (1,0) [0|14] ""  FLZCU_VCU_EP,FLZCU_PDCS_EP
 SG_ BMS_6_Resd2 : 79|4@0+ (1,0) [0|15] ""  FLZCU_VCU_EP,FLZCU_PDCS_EP
 SG_ BMS_Chg_Sts : 87|4@0+ (1,0) [0|15] ""  FLZCU_VCU_EP,FLZCU_PDCS_EP,FLZCU_EP
 SG_ BMS_PackSOCNotAvrlble : 83|10@0+ (0.1,0) [0|100] "%"  FLZCU_VCU_EP,FLZCU_PDCS_EP
 SG_ BMS_DchaPwrContnsMax : 89|14@0+ (0.1,0) [0|1000] "kW"  FLZCU_VCU_EP,FLZCU_PDCS_EP,VCU_EP,PDCS_EP,PDCS_EP_E0V,FmcuVcu_EP,FmcuVcu_EP_E0V
 SG_ BMS_ChrgPwrContnsMax : 107|14@0+ (0.1,-1000) [-1000|0] "kW"  FLZCU_VCU_EP,FLZCU_PDCS_EP,VCU_EP,PDCS_EP,PDCS_EP_E0V,FmcuVcu_EP,FmcuVcu_EP_E0V
 SG_ BMS_APlusWakeupSt : 125|2@0+ (1,0) [0|3] ""  FLZCU_VCU_EP,FLZCU_PDCS_EP
 SG_ BMS_KL15WakeupSt : 123|2@0+ (1,0) [0|3] ""  FLZCU_VCU_EP,FLZCU_PDCS_EP
 SG_ BMSH_CHGPrechargeRelaySts : 121|2@0+ (1,0) [0|3] ""  FLZCU_VCU_EP,FLZCU_PDCS_EP,CDU,RmcuCdu,RmcuCdu_E0V

BO_ 1290 BMS_8: 8 BMS
 SG_ BMS_8_CRC1 : 7|8@0+ (1,0) [0|255] ""  FLZCU_VCU_EP,FLZCU_PDCS_EP
 SG_ BMS_8_RollgCntr1 : 11|4@0+ (1,0) [0|14] ""  FLZCU_VCU_EP,FLZCU_PDCS_EP
 SG_ BMS_8_Resd1 : 15|4@0+ (1,0) [0|15] ""  FLZCU_VCU_EP,FLZCU_PDCS_EP
 SG_ BMS_HvBattCellOverU : 18|3@0+ (1,0) [0|4] ""  FLZCU_VCU_EP,FLZCU_PDCS_EP
 SG_ BMS_HvBattCellUnderU : 21|3@0+ (1,0) [0|4] ""  FLZCU_VCU_EP,FLZCU_PDCS_EP
 SG_ BMS_HvBattUnderU : 23|2@0+ (1,0) [0|2] ""  FLZCU_VCU_EP,FLZCU_PDCS_EP
 SG_ BMS_HvBattDischargeOverCurrent : 26|3@0+ (1,0) [0|4] ""  FLZCU_VCU_EP,FLZCU_PDCS_EP
 SG_ BMS_HvBattChargeOverCurrent : 29|3@0+ (1,0) [0|4] ""  FLZCU_VCU_EP,FLZCU_PDCS_EP
 SG_ BMS_HvBattOverU : 31|2@0+ (1,0) [0|2] ""  FLZCU_VCU_EP,FLZCU_PDCS_EP
 SG_ BMS_HvBattMismatching : 32|1@0+ (1,0) [0|1] ""  FLZCU_VCU_EP,FLZCU_PDCS_EP
 SG_ BMS_HvBattSocJump : 33|1@0+ (1,0) [0|1] ""  FLZCU_VCU_EP,FLZCU_PDCS_EP
 SG_ BMS_HvBattCellUUnif : 34|1@0+ (1,0) [0|1] ""  FLZCU_VCU_EP,FLZCU_PDCS_EP
 SG_ BMS_HvBattLowSoc : 35|1@0+ (1,0) [0|1] ""  FLZCU_VCU_EP,FLZCU_PDCS_EP
 SG_ BMS_HvBattOverSoc : 36|1@0+ (1,0) [0|1] ""  FLZCU_VCU_EP,FLZCU_PDCS_EP
 SG_ BMS_HvBattTempUniformity : 37|1@0+ (1,0) [0|1] ""  FLZCU_VCU_EP,FLZCU_PDCS_EP
 SG_ BMS_BattInterCANErr : 38|1@0+ (1,0) [0|1.0] ""  FLZCU_VCU_EP,FLZCU_PDCS_EP
 SG_ BMS_HvBattOverCharging : 39|1@0+ (1,0) [0|1.0] ""  FLZCU_VCU_EP,FLZCU_PDCS_EP
 SG_ BMS_HvBattOverTemperature : 47|3@0+ (1,0) [0|4] ""  FLZCU_VCU_EP,FLZCU_PDCS_EP
 SG_ BMS_PrimaryCurrtSnsrTemp : 55|8@0+ (1,-50) [-50|205] "��"  FLZCU_VCU_EP,FLZCU_PDCS_EP
 SG_ BMS_EquTempMax : 63|8@0+ (1,-40) [-40|125] "��"  FLZCU_VCU_EP,FLZCU_PDCS_EP

BO_ 1531 BMS_9: 32 BMS
 SG_ BMS_9_CRC1 : 7|8@0+ (1,0) [0|255] ""  FLZCU_VCU_EP,FLZCU_PDCS_EP
 SG_ BMS_9_RollgCntr1 : 11|4@0+ (1,0) [0|14] ""  FLZCU_VCU_EP,FLZCU_PDCS_EP
 SG_ BMS_9_Resd1 : 15|4@0+ (1,0) [0|15] ""  FLZCU_VCU_EP,FLZCU_PDCS_EP
 SG_ BMS_HvBattSoeActDisChaCyc : 23|16@0+ (0.1,0) [0|999.9] "kWh"  FLZCU_VCU_EP,FLZCU_PDCS_EP
 SG_ BMS_HvBattSoeActReChaCyc : 39|16@0+ (0.1,0) [0|999.9] "kWh"  FLZCU_VCU_EP,FLZCU_PDCS_EP
 SG_ BMS_HvBattRatedEnergy : 55|14@0+ (0.1,0) [0|999.9] "KW?h"  FLZCU_VCU_EP,FLZCU_PDCS_EP,VCU_EP
 SG_ BMS_HvBattRatedU : 71|14@0+ (0.1,0) [0|999.9] "V"  FLZCU_VCU_EP,FLZCU_PDCS_EP
 SG_ BMS_HvBattTypeCode : 87|8@0+ (1,0) [0|255] ""  FLZCU_VCU_EP,FLZCU_PDCS_EP
 SG_ BMS_HvBattManufcCode : 95|32@0+ (1,0) [0|4294967295] ""  FLZCU_VCU_EP,FLZCU_PDCS_EP
 SG_ BMS_HvBattTempSensorTotalNum : 127|16@0+ (1,0) [0|65534] ""  FLZCU_VCU_EP,FLZCU_PDCS_EP
 SG_ BMS_HvBattTempSensorTempMaxNum : 143|8@0+ (1,0) [1|250] ""  FLZCU_VCU_EP,FLZCU_PDCS_EP
 SG_ BMS_HvBattTempSensorTempMinNum : 151|8@0+ (1,0) [1|250] ""  FLZCU_VCU_EP,FLZCU_PDCS_EP
 SG_ BMS_HvBattTempMaxNum : 159|8@0+ (1,0) [1|250.0] ""  FLZCU_VCU_EP,FLZCU_PDCS_EP
 SG_ BMS_HvBattTempMinNum : 167|8@0+ (1,0) [1|250.0] ""  FLZCU_VCU_EP,FLZCU_PDCS_EP
 SG_ BMS_BattCellTotalNum : 175|16@0+ (1,0) [0.0|65531.0] ""  FLZCU_VCU_EP,FLZCU_PDCS_EP
 SG_ BMS_HvBattVoltMaxNum : 191|8@0+ (1,0) [1|250.0] ""  FLZCU_VCU_EP,FLZCU_PDCS_EP
 SG_ BMS_HvBattVoltMinNum : 199|8@0+ (1,0) [1|250.0] ""  FLZCU_VCU_EP,FLZCU_PDCS_EP
 SG_ BMS_ActualSOCMin : 207|12@0+ (0.025,0) [0|100] "%"  FLZCU_VCU_EP,FLZCU_PDCS_EP
 SG_ BMS_ActualSOCMax : 211|12@0+ (0.025,0) [0|100] "%"  FLZCU_VCU_EP,FLZCU_PDCS_EP

BO_ 1535 BMS_10: 64 BMS
 SG_ BMS_HvBattTempSensorTemp_1T : 7|8@0+ (1.0,-40) [-40|210.0] "��"  FLZCU_VCU_EP,FLZCU_PDCS_EP
 SG_ BMS_HvBattTempSensorTemp_2T : 15|8@0+ (1.0,-40) [-40|210.0] "��"  FLZCU_VCU_EP,FLZCU_PDCS_EP
 SG_ BMS_HvBattTempSensorTemp_3T : 23|8@0+ (1.0,-40) [-40|210.0] "��"  FLZCU_VCU_EP,FLZCU_PDCS_EP
 SG_ BMS_HvBattTempSensorTemp_4T : 31|8@0+ (1.0,-40) [-40|210.0] "��"  FLZCU_VCU_EP,FLZCU_PDCS_EP
 SG_ BMS_HvBattTempSensorTemp_5T : 39|8@0+ (1.0,-40) [-40|210.0] "��"  FLZCU_VCU_EP,FLZCU_PDCS_EP
 SG_ BMS_HvBattTempSensorTemp_6T : 47|8@0+ (1.0,-40) [-40|210.0] "��"  FLZCU_VCU_EP,FLZCU_PDCS_EP
 SG_ BMS_HvBattTempSensorTemp_7T : 55|8@0+ (1.0,-40) [-40|210.0] "��"  FLZCU_VCU_EP,FLZCU_PDCS_EP
 SG_ BMS_HvBattTempSensorTemp_8T : 63|8@0+ (1.0,-40) [-40|210.0] "��"  FLZCU_VCU_EP,FLZCU_PDCS_EP
 SG_ BMS_HvBattTempSensorTemp_9T : 71|8@0+ (1.0,-40) [-40|210.0] "��"  FLZCU_VCU_EP,FLZCU_PDCS_EP
 SG_ BMS_HvBattTempSensorTemp_10T : 79|8@0+ (1.0,-40) [-40|210.0] "��"  FLZCU_VCU_EP,FLZCU_PDCS_EP
 SG_ BMS_HvBattTempSensorTemp_11T : 87|8@0+ (1.0,-40) [-40|210.0] "��"  FLZCU_VCU_EP,FLZCU_PDCS_EP
 SG_ BMS_HvBattTempSensorTemp_12T : 95|8@0+ (1.0,-40) [-40|210.0] "��"  FLZCU_VCU_EP,FLZCU_PDCS_EP
 SG_ BMS_HvBattTempSensorTemp_13T : 103|8@0+ (1.0,-40) [-40|210.0] "��"  FLZCU_VCU_EP,FLZCU_PDCS_EP
 SG_ BMS_HvBattTempSensorTemp_14T : 111|8@0+ (1.0,-40) [-40|210.0] "��"  FLZCU_VCU_EP,FLZCU_PDCS_EP
 SG_ BMS_HvBattTempSensorTemp_15T : 119|8@0+ (1.0,-40) [-40|210.0] "��"  FLZCU_VCU_EP,FLZCU_PDCS_EP
 SG_ BMS_HvBattTempSensorTemp_16T : 127|8@0+ (1.0,-40) [-40|210.0] "��"  FLZCU_VCU_EP,FLZCU_PDCS_EP
 SG_ BMS_HvBattTempSensorTemp_17T : 135|8@0+ (1.0,-40) [-40|210.0] "��"  FLZCU_VCU_EP,FLZCU_PDCS_EP
 SG_ BMS_HvBattTempSensorTemp_18T : 143|8@0+ (1.0,-40) [-40|210.0] "��"  FLZCU_VCU_EP,FLZCU_PDCS_EP
 SG_ BMS_HvBattTempSensorTemp_19T : 151|8@0+ (1.0,-40) [-40|210.0] "��"  FLZCU_VCU_EP,FLZCU_PDCS_EP
 SG_ BMS_HvBattTempSensorTemp_20T : 159|8@0+ (1.0,-40) [-40|210.0] "��"  FLZCU_VCU_EP,FLZCU_PDCS_EP
 SG_ BMS_HvBattTempSensorTemp_21T : 167|8@0+ (1.0,-40) [-40|210.0] "��"  FLZCU_VCU_EP,FLZCU_PDCS_EP
 SG_ BMS_HvBattTempSensorTemp_22T : 175|8@0+ (1.0,-40) [-40|210.0] "��"  FLZCU_VCU_EP,FLZCU_PDCS_EP
 SG_ BMS_HvBattTempSensorTemp_23T : 183|8@0+ (1.0,-40) [-40|210.0] "��"  FLZCU_VCU_EP,FLZCU_PDCS_EP
 SG_ BMS_HvBattTempSensorTemp_24T : 191|8@0+ (1.0,-40) [-40|210.0] "��"  FLZCU_VCU_EP,FLZCU_PDCS_EP
 SG_ BMS_HvBattTempSensorTemp_25T : 199|8@0+ (1.0,-40) [-40|210.0] "��"  FLZCU_VCU_EP,FLZCU_PDCS_EP
 SG_ BMS_HvBattTempSensorTemp_26T : 207|8@0+ (1.0,-40) [-40|210.0] "��"  FLZCU_VCU_EP,FLZCU_PDCS_EP
 SG_ BMS_HvBattTempSensorTemp_27T : 215|8@0+ (1.0,-40) [-40|210.0] "��"  FLZCU_VCU_EP,FLZCU_PDCS_EP
 SG_ BMS_HvBattTempSensorTemp_28T : 223|8@0+ (1.0,-40) [-40|210.0] "��"  FLZCU_VCU_EP,FLZCU_PDCS_EP
 SG_ BMS_HvBattTempSensorTemp_29T : 231|8@0+ (1.0,-40) [-40|210.0] "��"  FLZCU_VCU_EP,FLZCU_PDCS_EP
 SG_ BMS_HvBattTempSensorTemp_30T : 239|8@0+ (1.0,-40) [-40|210.0] "��"  FLZCU_VCU_EP,FLZCU_PDCS_EP
 SG_ BMS_HvBattTempSensorTemp_31T : 247|8@0+ (1.0,-40) [-40|210.0] "��"  FLZCU_VCU_EP,FLZCU_PDCS_EP
 SG_ BMS_HvBattTempSensorTemp_32T : 255|8@0+ (1.0,-40) [-40|210.0] "��"  FLZCU_VCU_EP,FLZCU_PDCS_EP
 SG_ BMS_HvBattTempSensorTemp_33T : 263|8@0+ (1.0,-40) [-40|210.0] "��"  FLZCU_VCU_EP,FLZCU_PDCS_EP
 SG_ BMS_HvBattTempSensorTemp_34T : 271|8@0+ (1.0,-40) [-40|210.0] "��"  FLZCU_VCU_EP,FLZCU_PDCS_EP
 SG_ BMS_HvBattTempSensorTemp_35T : 279|8@0+ (1.0,-40) [-40|210.0] "��"  FLZCU_VCU_EP,FLZCU_PDCS_EP
 SG_ BMS_HvBattTempSensorTemp_36T : 287|8@0+ (1.0,-40) [-40|210.0] "��"  FLZCU_VCU_EP,FLZCU_PDCS_EP
 SG_ BMS_HvBattTempSensorTemp_37T : 295|8@0+ (1.0,-40) [-40|210.0] "��"  FLZCU_VCU_EP,FLZCU_PDCS_EP
 SG_ BMS_HvBattTempSensorTemp_38T : 303|8@0+ (1.0,-40) [-40|210.0] "��"  FLZCU_VCU_EP,FLZCU_PDCS_EP
 SG_ BMS_HvBattTempSensorTemp_39T : 311|8@0+ (1.0,-40) [-40|210.0] "��"  FLZCU_VCU_EP,FLZCU_PDCS_EP
 SG_ BMS_HvBattTempSensorTemp_40T : 319|8@0+ (1.0,-40) [-40|210.0] "��"  FLZCU_VCU_EP,FLZCU_PDCS_EP
 SG_ BMS_HvBattTempSensorTemp_41T : 327|8@0+ (1.0,-40) [-40|210.0] "��"  FLZCU_VCU_EP,FLZCU_PDCS_EP
 SG_ BMS_HvBattTempSensorTemp_42T : 335|8@0+ (1.0,-40) [-40|210.0] "��"  FLZCU_VCU_EP,FLZCU_PDCS_EP
 SG_ BMS_HvBattTempSensorTemp_43T : 343|8@0+ (1.0,-40) [-40|210.0] "��"  FLZCU_VCU_EP,FLZCU_PDCS_EP
 SG_ BMS_HvBattTempSensorTemp_44T : 351|8@0+ (1.0,-40) [-40|210.0] "��"  FLZCU_VCU_EP,FLZCU_PDCS_EP
 SG_ BMS_HvBattTempSensorTemp_45T : 359|8@0+ (1.0,-40) [-40|210.0] "��"  FLZCU_VCU_EP,FLZCU_PDCS_EP
 SG_ BMS_HvBattTempSensorTemp_46T : 367|8@0+ (1.0,-40) [-40|210.0] "��"  FLZCU_VCU_EP,FLZCU_PDCS_EP
 SG_ BMS_HvBattTempSensorTemp_47T : 375|8@0+ (1.0,-40) [-40|210.0] "��"  FLZCU_VCU_EP,FLZCU_PDCS_EP
 SG_ BMS_HvBattTempSensorTemp_48T : 383|8@0+ (1.0,-40) [-40|210.0] "��"  FLZCU_VCU_EP,FLZCU_PDCS_EP
 SG_ BMS_BattTempSensorStartFrameNum : 391|8@0+ (1,0) [0|255.0] ""  FLZCU_VCU_EP,FLZCU_PDCS_EP
 SG_ BMS_HvBattTempSensorFrameTNum : 399|6@0+ (1,0) [0|61] ""  FLZCU_VCU_EP,FLZCU_PDCS_EP

BO_ 1340 BMS_11: 24 BMS
 SG_ BMS_HvBattSerialNum_PDU1 : 7|32@0+ (1,0) [0|4294967295] ""  FLZCU_VCU_EP,FLZCU_PDCS_EP
 SG_ BMS_HvBattSerialNum_PDU2 : 39|32@0+ (1,0) [0|4294967295] ""  FLZCU_VCU_EP,FLZCU_PDCS_EP
 SG_ BMS_HvBattSerialNum_PDU3 : 71|32@0+ (1,0) [0|4294967295] ""  FLZCU_VCU_EP,FLZCU_PDCS_EP
 SG_ BMS_HvBattSerialNum_PDU4 : 103|32@0+ (1,0) [0|4294967295] ""  FLZCU_VCU_EP,FLZCU_PDCS_EP
 SG_ BMS_HvBattSerialNum_PDU5 : 135|32@0+ (1,0) [0|4294967295] ""  FLZCU_VCU_EP,FLZCU_PDCS_EP
 SG_ BMS_HvBattSerialNum_PDU6 : 167|32@0+ (1,0) [0|4294967295] ""  FLZCU_VCU_EP,FLZCU_PDCS_EP

BO_ 1224 BMS_12: 16 BMS
 SG_ BMS_HvBattCellVoltMax_Num : 23|8@0+ (1,0) [0|250.0] "bit"  FLZCU_VCU_EP,FLZCU_PDCS_EP
 SG_ BMS_HvBattCellVoltMax : 31|16@0+ (0.001,0) [0|15] "V"  FLZCU_VCU_EP,FLZCU_PDCS_EP
 SG_ BMS_HvBattCellVoltMin_Num : 47|8@0+ (1,0) [0|250.0] "bit"  FLZCU_VCU_EP,FLZCU_PDCS_EP
 SG_ BMS_HvBattCellVoltMin : 55|16@0+ (0.001,0) [0|15] "V"  FLZCU_VCU_EP,FLZCU_PDCS_EP
 SG_ BMS_Chg_Sts : 87|4@0+ (1,0) [0|15] ""  FLZCU_VCU_EP,FLZCU_PDCS_EP

BO_ 1230 BMS_13: 64 BMS
 SG_ BMS_HvBattCellU_1V : 7|16@0+ (0.001,0) [0|60] "V"  Vector__XXX
 SG_ BMS_HvBattCellU_2V : 23|16@0+ (0.001,0) [0|60] "V"  Vector__XXX
 SG_ BMS_HvBattCellU_3V : 39|16@0+ (0.001,0) [0|60] "V"  Vector__XXX
 SG_ BMS_HvBattCellU_4V : 55|16@0+ (0.001,0) [0|60] "V"  Vector__XXX
 SG_ BMS_HvBattCellU_5V : 71|16@0+ (0.001,0) [0|60] "V"  Vector__XXX
 SG_ BMS_HvBattCellU_6V : 87|16@0+ (0.001,0) [0|60] "V"  Vector__XXX
 SG_ BMS_HvBattCellU_7V : 103|16@0+ (0.001,0) [0|60] "V"  Vector__XXX
 SG_ BMS_HvBattCellU_8V : 119|16@0+ (0.001,0) [0|60] "V"  Vector__XXX
 SG_ BMS_HvBattCellU_9V : 135|16@0+ (0.001,0) [0|60] "V"  Vector__XXX
 SG_ BMS_HvBattCellU_10V : 151|16@0+ (0.001,0) [0|60] "V"  Vector__XXX
 SG_ BMS_HvBattCellU_11V : 167|16@0+ (0.001,0) [0|60] "V"  Vector__XXX
 SG_ BMS_HvBattCellU_12V : 183|16@0+ (0.001,0) [0|60] "V"  Vector__XXX
 SG_ BMS_HvBattCellU_13V : 199|16@0+ (0.001,0) [0|60] "V"  Vector__XXX
 SG_ BMS_HvBattCellU_14V : 215|16@0+ (0.001,0) [0|60] "V"  Vector__XXX
 SG_ BMS_HvBattCellU_15V : 231|16@0+ (0.001,0) [0|60] "V"  Vector__XXX
 SG_ BMS_HvBattCellU_16V : 247|16@0+ (0.001,0) [0|60] "V"  Vector__XXX
 SG_ BMS_HvBattCellU_17V : 263|16@0+ (0.001,0) [0|60] "V"  Vector__XXX
 SG_ BMS_HvBattCellU_18V : 279|16@0+ (0.001,0) [0|60] "V"  Vector__XXX
 SG_ BMS_HvBattCellU_19V : 295|16@0+ (0.001,0) [0|60] "V"  Vector__XXX
 SG_ BMS_HvBattCellU_20V : 311|16@0+ (0.001,0) [0|60] "V"  Vector__XXX
 SG_ BMS_HvBattCellU_21V : 327|16@0+ (0.001,0) [0|60] "V"  Vector__XXX
 SG_ BMS_HvBattCellU_22V : 343|16@0+ (0.001,0) [0|60] "V"  Vector__XXX
 SG_ BMS_HvBattCellU_23V : 359|16@0+ (0.001,0) [0|60] "V"  Vector__XXX
 SG_ BMS_HvBattCellU_24V : 375|16@0+ (0.001,0) [0|60] "V"  Vector__XXX
 SG_ BMS_HvBattCellU_25V : 391|16@0+ (0.001,0) [0|60] "V"  Vector__XXX
 SG_ BMS_HvBattCellU_26V : 407|16@0+ (0.001,0) [0|60] "V"  Vector__XXX
 SG_ BMS_HvBattCellU_27V : 423|16@0+ (0.001,0) [0|60] "V"  Vector__XXX
 SG_ BMS_HvBattCellU_28V : 439|16@0+ (0.001,0) [0|60] "V"  Vector__XXX
 SG_ BMS_HvBattCellU_29V : 455|16@0+ (0.001,0) [0|60] "V"  Vector__XXX
 SG_ BMS_HvBattCellU_30V : 471|16@0+ (0.001,0) [0|60] "V"  Vector__XXX
 SG_ BMS_BattCellstartframeNum : 487|16@0+ (1,0) [1|65531] ""  Vector__XXX
 SG_ BMS_HvBattCellFrameTotalNum : 503|8@0+ (1,0) [1|200] ""  Vector__XXX

BO_ 1041 BMS_14: 64 BMS
 SG_ CRM_RecongnitionResult : 23|2@0+ (1,0) [0|3] ""  FLZCU_VCU_EP,FLZCU_PDCS_EP
 SG_ BMS_InsulationPos : 21|16@0+ (1,0) [0|60000] "k��"  FLZCU_VCU_EP,FLZCU_PDCS_EP
 SG_ BMS_IsoPosVolt : 33|10@0+ (1,0) [0|1000] "volt (V)"  FLZCU_VCU_EP,FLZCU_PDCS_EP
 SG_ BMS_IsoNegVolt : 55|10@0+ (1,0) [0|1000] "volt (V)"  FLZCU_VCU_EP,FLZCU_PDCS_EP
 SG_ BMS_IsoPosSwtSts : 61|2@0+ (1,0) [0|3] ""  FLZCU_VCU_EP,FLZCU_PDCS_EP
 SG_ BMS_IsoNegSwtSts : 59|2@0+ (1,0) [0|3] ""  FLZCU_VCU_EP,FLZCU_PDCS_EP
 SG_ BCL_ChareMode : 57|2@0+ (1,0) [0|3] ""  FLZCU_VCU_EP,FLZCU_PDCS_EP
 SG_ BMS_HVPwrDwnRsn : 86|3@0+ (1,0) [0|7] ""  FLZCU_VCU_EP,FLZCU_PDCS_EP
 SG_ BMS_InsulationProhibitRsn : 82|3@0+ (1,0) [0|7] ""  FLZCU_VCU_EP,FLZCU_PDCS_EP
 SG_ BMS_BPSWakeupSt : 95|2@0+ (1,0) [0|3] ""  FLZCU_VCU_EP,FLZCU_PDCS_EP
 SG_ BMS_AFEWakeupSt : 93|2@0+ (1,0) [0|3] ""  FLZCU_VCU_EP,FLZCU_PDCS_EP
 SG_ BMS_NMWakeupSt : 91|2@0+ (1,0) [0|3] ""  FLZCU_VCU_EP,FLZCU_PDCS_EP
 SG_ BMS_CC2WakeupSt : 89|2@0+ (1,0) [0|3] ""  FLZCU_VCU_EP,FLZCU_PDCS_EP
 SG_ CCS_ChargeAllowed : 103|2@0+ (1,0) [0|3] ""  FLZCU_VCU_EP,FLZCU_PDCS_EP
 SG_ BMS_ResetRsn : 101|6@0+ (1,0) [0|63] ""  FLZCU_VCU_EP,FLZCU_PDCS_EP
 SG_ BMS_HVPwrOnFailRsn : 109|6@0+ (1,0) [0|63] ""  FLZCU_VCU_EP,FLZCU_PDCS_EP
 SG_ BMS_AirPressure : 119|16@0+ (0.1,0) [0|6553.3] "kPa"  FLZCU_VCU_EP,FLZCU_PDCS_EP
 SG_ BMS_AirPressureRate : 151|8@0+ (0.1,0) [0|25.3] "kPa/s"  FLZCU_VCU_EP,FLZCU_PDCS_EP
 SG_ BMS_BattTempRate : 159|8@0+ (1,0) [0|253] "��/3S"  FLZCU_VCU_EP,FLZCU_PDCS_EP
 SG_ BMS_CellVoltSum : 165|14@0+ (0.1,0) [0|1000] ""  FLZCU_VCU_EP,FLZCU_PDCS_EP
 SG_ BMS_DchaCurrtShoTiMax : 181|14@0+ (0.1,0) [0|1000] "A"  FLZCU_VCU_EP,FLZCU_PDCS_EP
 SG_ BMS_ChrgCurrtShoTiMax : 213|14@0+ (0.1,-1000) [-1000|0] "A"  FLZCU_VCU_EP,FLZCU_PDCS_EP
 SG_ BMS_DchaPwrLongTiMax : 229|14@0+ (0.1,0) [0|1000] "kW"  FLZCU_VCU_EP,FLZCU_PDCS_EP
 SG_ BMS_ChrgPwrLongTiMax : 245|14@0+ (0.1,-1000) [-1000|0] "kW"  FLZCU_VCU_EP,FLZCU_PDCS_EP
 SG_ BMS_DchaCurrtLongTiMax : 277|14@0+ (0.1,0) [0|1000] "A"  FLZCU_VCU_EP,FLZCU_PDCS_EP
 SG_ BMS_ChrgCurrtLongTiMax : 293|14@0+ (0.1,-1000) [-1000|0] "A"  FLZCU_VCU_EP,FLZCU_PDCS_EP
 SG_ BMS_DchaCurrtContnsMax : 309|14@0+ (0.1,0) [0|1000] "A"  FLZCU_VCU_EP,FLZCU_PDCS_EP
 SG_ BMS_ChrgCurrtContnsMax : 343|14@0+ (0.1,-1000) [-1000|0] "A"  FLZCU_VCU_EP,FLZCU_PDCS_EP
 SG_ BRO_BMSChargeReady : 359|2@0+ (1,0) [0|3] ""  FLZCU_VCU_EP,FLZCU_PDCS_EP
 SG_ CRO_ChargeReady : 357|2@0+ (1,0) [0|3] ""  FLZCU_VCU_EP,FLZCU_PDCS_EP
 SG_ BMS_BattChrgNeeded : 355|2@0+ (1,0) [0|3] ""  FLZCU_VCU_EP,FLZCU_PDCS_EP
 SG_ BMS_DcDisChgStatus : 367|4@0+ (1,0) [0|15] ""  FLZCU_VCU_EP,FLZCU_PDCS_EP
 SG_ BMS_CC1_Resistance : 363|12@0+ (1,0) [0|4095] ""  FLZCU_VCU_EP,FLZCU_PDCS_EP
 SG_ BMS_CC2_Resistance : 383|12@0+ (1,0) [0|4095] ""  FLZCU_VCU_EP,FLZCU_PDCS_EP
 SG_ BMS_DC_DisChrgCurr : 387|12@0+ (0.1,0) [0|400] "ampere (A)"  FLZCU_VCU_EP,FLZCU_PDCS_EP
 SG_ BMS_DC_DisChrgPower : 407|12@0+ (0.1,0) [0|400] "kW"  FLZCU_VCU_EP,FLZCU_PDCS_EP
 SG_ BMS_DC_DisChrgEngy : 411|12@0+ (0.1,0) [0|200] "KW?h"  FLZCU_VCU_EP,FLZCU_PDCS_EP
 SG_ BMS_DC_DisChrgRemainTi : 434|11@0+ (1,0) [0|1440] "min"  FLZCU_VCU_EP,FLZCU_PDCS_EP
 SG_ BMS_DC_DisChrgVolt : 455|16@0+ (0.1,0) [0|1000] "volt (V)"  FLZCU_VCU_EP,FLZCU_PDCS_EP
 SG_ BMS_QCCDetdtVoltage : 471|16@0+ (0.1,0) [0|1000] "V"  FLZCU_VCU_EP,FLZCU_PDCS_EP,EVCC
 SG_ BMS_InsulationNeg : 487|16@0+ (1,0) [0|60000] "k��"  FLZCU_VCU_EP,FLZCU_PDCS_EP
 SG_ BMS_SOCE_EU : 502|7@0+ (1,0) [0|100] "%"  FLZCU_VCU_EP,FLZCU_PDCS_EP,VCU_EP,PDCS_EP,PDCS_EP_E0V,FmcuVcu_EP,FmcuVcu_EP_E0V

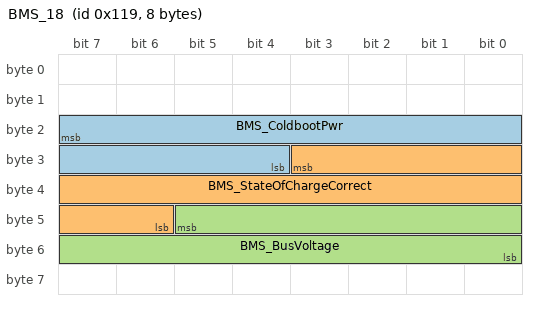
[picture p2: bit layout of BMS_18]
BO_ 281 BMS_18: 8 BMS
 SG_ BMS_ColdbootPwr : 23|12@0+ (0.1,0) [0|320] "KW"  PDCS_EP,PDCS_EP_E0V,FmcuVcu_EP,FmcuVcu_EP_E0V
 SG_ BMS_StateOfChargeCorrect : 27|14@0+ (0.01,0) [0|100] "%"  PDCS_EP,PDCS_EP_E0V,FmcuVcu_EP,FmcuVcu_EP_E0V
 SG_ BMS_BusVoltage : 45|14@0+ (0.1,0) [0|1000] "V"  Vector__XXX

BO_ 1275 BMS_19: 64 BMS
 SG_ BMSH_PowerChangeSign : 23|3@0+ (1,0) [0|7] ""  Vector__XXX
 SG_ BMSH_PackInstantOutPower : 19|12@0+ (0.1,0) [0|320] "KW"  PDCS_EP,PDCS_EP_E0V,FmcuVcu_EP,FmcuVcu_EP_E0V
 SG_ BMSH_PackInstantRecoveryPower : 39|12@0+ (0.1,0) [0|320] "KW"  PDCS_EP,PDCS_EP_E0V,FmcuVcu_EP,FmcuVcu_EP_E0V
 SG_ BMS_SOCCalAlarm : 43|2@0+ (1,0) [0|3] ""  Vector__XXX
 SG_ BMS_PosInsulationSt : 41|3@0+ (1,0) [0|7] ""  Vector__XXX
 SG_ BMS_NegInsulationSt : 54|3@0+ (1,0) [0|7] ""  Vector__XXX
 SG_ BMSH_NegInsulationResis : 87|16@0+ (1,0) [0|65533] "k��"  Vector__XXX
 SG_ BMSH_PosInsulationResis : 103|16@0+ (1,0) [0|65533] "k��"  Vector__XXX
 SG_ CML_OutputVoltageMax : 119|16@0+ (0.1,0) [0|6553.5] "V"  Vector__XXX
 SG_ CML_OutputVoltageMin : 151|16@0+ (0.1,0) [0|6553.5] "V"  Vector__XXX
 SG_ CML_OutputCurentMax : 167|16@0+ (0.1,-400) [-400|6153.5] "A"  Vector__XXX
 SG_ CML_OutputCurentMin : 183|16@0+ (0.1,-400) [-400|6153.5] "A"  Vector__XXX
 SG_ BCL_VoltageRequire : 215|16@0+ (0.1,0) [0|6553.5] "V"  Vector__XXX
 SG_ BCL_CurrentRequire : 231|16@0+ (0.1,-400) [-400|6153.5] "A"  Vector__XXX
 SG_ CCS_OutputVoltage : 247|16@0+ (0.1,0) [0|6553.5] "V"  FLZCU_VCU_EP,VCU_EP,PDCS_EP,PDCS_EP_E0V,FmcuVcu_EP,FmcuVcu_EP_E0V
 SG_ CCS_OutputCurent : 279|16@0+ (0.1,-400) [-400|6153.5] "A"  FLZCU_VCU_EP,VCU_EP,PDCS_EP,PDCS_EP_E0V,FmcuVcu_EP,FmcuVcu_EP_E0V

BO_ 1127 CDU_DCDC_1: 24 CDU
 SG_ CDU_1_CRC1 : 7|8@0+ (1,0) [0|255] ""  FLZCU_VCU_EP,FLZCU_PDCS_EP
 SG_ CDU_1_RollgCntr1 : 11|4@0+ (1,0) [0|14] ""  FLZCU_VCU_EP,FLZCU_PDCS_EP
 SG_ CDU_1_Resd1 : 15|4@0+ (1,0) [0|15] ""  FLZCU_VCU_EP,FLZCU_PDCS_EP
 SG_ DCDC_HvVolt : 23|16@0+ (0.1,0) [0|1000] "V"  FLZCU_VCU_EP,FLZCU_PDCS_EP,VCU_EP,PDCS_EP,PDCS_EP_E0V,FmcuVcu_EP,FmcuVcu_EP_E0V
 SG_ DCDC_HVCurr : 39|16@0+ (0.1,0) [0|1000] "A"  FLZCU_VCU_EP,FLZCU_PDCS_EP,VCU_EP,PDCS_EP,PDCS_EP_E0V,FmcuVcu_EP,FmcuVcu_EP_E0V
 SG_ DCDC_FaultCode : 55|8@0+ (1,0) [0|255] ""  FLZCU_VCU_EP,FLZCU_PDCS_EP
 SG_ CDU_1_CRC2 : 71|8@0+ (1,0) [0|255] ""  FLZCU_VCU_EP,FLZCU_PDCS_EP,VCU_EP,PDCS_EP,PDCS_EP_E0V,FmcuVcu_EP,FmcuVcu_EP_E0V
 SG_ CDU_1_RollgCntr2 : 75|4@0+ (1,0) [0|14] ""  FLZCU_VCU_EP,FLZCU_PDCS_EP,VCU_EP,PDCS_EP,PDCS_EP_E0V,FmcuVcu_EP,FmcuVcu_EP_E0V
 SG_ CDU_1_Resd2 : 79|4@0+ (1,0) [0|15] ""  FLZCU_VCU_EP,FLZCU_PDCS_EP,VCU_EP,PDCS_EP,PDCS_EP_E0V,FmcuVcu_EP,FmcuVcu_EP_E0V
 SG_ DCDC_LvSideCurr : 87|12@0+ (1,0) [0|510] "A"  FLZCU_VCU_EP,FLZCU_PDCS_EP,FLZCU_EP,VCU_EP,PDCS_EP,PDCS_EP_E0V,FmcuVcu_EP,FmcuVcu_EP_E0V
 SG_ DCDC_LvSideVolt : 103|11@0+ (0.1,0) [0|25.3] "V"  FLZCU_VCU_EP,FLZCU_PDCS_EP,FLZCU_EP,VCU_EP,PDCS_EP,PDCS_EP_E0V,FmcuVcu_EP,FmcuVcu_EP_E0V
 SG_ DCDC_FaultLevelSts : 107|3@0+ (1,0) [0|7] ""  FLZCU_VCU_EP,FLZCU_PDCS_EP,FLZCU_EP,VCU_EP,PDCS_EP,PDCS_EP_E0V,FmcuVcu_EP,FmcuVcu_EP_E0V
 SG_ DCDC_EnableSts : 104|1@0+ (1,0) [0|1] ""  FLZCU_VCU_EP,FLZCU_PDCS_EP,VCU_EP,PDCS_EP,PDCS_EP_E0V,FmcuVcu_EP,FmcuVcu_EP_E0V
 SG_ DCDC_OverTemp : 88|1@0+ (1,0) [0|1] ""  FLZCU_VCU_EP,FLZCU_PDCS_EP,VCU_EP,PDCS_EP,PDCS_EP_E0V,FmcuVcu_EP,FmcuVcu_EP_E0V
 SG_ DCDC_LvSideCurrMax : 119|12@0+ (1,0) [0|510] "A"  FLZCU_VCU_EP,FLZCU_PDCS_EP,VCU_EP,PDCS_EP,PDCS_EP_E0V,FmcuVcu_EP,FmcuVcu_EP_E0V

BO_ 1182 CDU_OBC_3: 48 CDU
 SG_ CDU_2_CRC1 : 7|8@0+ (1,0) [0|255] ""  FLZCU_VCU_EP,FLZCU_PDCS_EP
 SG_ CDU_2_RollgCntr1 : 11|4@0+ (1,0) [0|14] ""  FLZCU_VCU_EP,FLZCU_PDCS_EP
 SG_ CDU_2_Resd1 : 15|4@0+ (1,0) [0|15] ""  FLZCU_VCU_EP,FLZCU_PDCS_EP
 SG_ OBC_ChgCurr : 23|16@0+ (0.05,0) [0|400] "A"  FLZCU_VCU_EP,FLZCU_PDCS_EP,VCU_EP,BMS,PDCS_EP,PDCS_EP_E0V,FmcuVcu_EP,FmcuVcu_EP_E0V
 SG_ OBC_ChgVolt : 39|16@0+ (0.05,0) [0|1000] "V"  FLZCU_VCU_EP,FLZCU_PDCS_EP,VCU_EP,BMS,PDCS_EP,PDCS_EP_E0V,FmcuVcu_EP,FmcuVcu_EP_E0V
 SG_ OBC_MaxOutputPower : 55|8@0+ (0.1,0) [0|25.5] "kW"  FLZCU_VCU_EP,FLZCU_PDCS_EP,VCU_EP,BMS,PDCS_EP,PDCS_EP_E0V,FmcuVcu_EP,FmcuVcu_EP_E0V
 SG_ OBC_FaultCode : 63|8@0+ (1,0) [0|255] ""  FLZCU_VCU_EP,FLZCU_PDCS_EP,VCU_EP,PDCS_EP,PDCS_EP_E0V,FmcuVcu_EP,FmcuVcu_EP_E0V
 SG_ CDU_2_CRC2 : 71|8@0+ (1,0) [0|255] ""  FLZCU_VCU_EP,FLZCU_PDCS_EP
 SG_ CDU_2_RollgCntr2 : 75|4@0+ (1,0) [0|14] ""  FLZCU_VCU_EP,FLZCU_PDCS_EP
 SG_ CDU_2_Resd2 : 79|4@0+ (1,0) [0|15] ""  FLZCU_VCU_EP,FLZCU_PDCS_EP
 SG_ OBC_CP_DutyCycleValue : 87|8@0+ (1,0) [0|100] "%"  FLZCU_VCU_EP,FLZCU_PDCS_EP,BMS
 SG_ CDU_Coolanttemp : 95|8@0+ (1,-40) [-40|213] "oC"  FLZCU_VCU_EP,FLZCU_PDCS_EP,VCU_EP,BMS,PDCS_EP,PDCS_EP_E0V,FmcuVcu_EP,FmcuVcu_EP_E0V
 SG_ OBC_ChgInterfaceTemp : 103|8@0+ (1,-40) [-40|213] "oC"  FLZCU_VCU_EP,FLZCU_PDCS_EP,BMS
 SG_ OBC_MaxDisOutPower : 111|8@0+ (0.1,0) [0|25.5] "kW"  FLZCU_VCU_EP,FLZCU_PDCS_EP,VCU_EP,PDCS_EP,PDCS_EP_E0V,FmcuVcu_EP,FmcuVcu_EP_E0V
 SG_ OBC_CPMaxVolt : 119|8@0+ (0.1,0) [0|20] "V"  FLZCU_VCU_EP,FLZCU_PDCS_EP,VCU_EP,PDCS_EP,PDCS_EP_E0V,FmcuVcu_EP,FmcuVcu_EP_E0V
 SG_ CDU_2_CRC3 : 135|8@0+ (1,0) [0|255] ""  FLZCU_VCU_EP,FLZCU_PDCS_EP
 SG_ CDU_2_RollgCntr3 : 139|4@0+ (1,0) [0|14] ""  FLZCU_VCU_EP,FLZCU_PDCS_EP
 SG_ CDU_2_Resd3 : 143|4@0+ (1,0) [0|15] ""  FLZCU_VCU_EP,FLZCU_PDCS_EP
 SG_ OBC_ChrgrInputCurr1 : 151|10@0+ (0.1,0) [0|100] "A"  FLZCU_VCU_EP,FLZCU_PDCS_EP,VCU_EP,PDCS_EP,PDCS_EP_E0V,FmcuVcu_EP,FmcuVcu_EP_E0V
 SG_ OBC_ChrgrInputCurr2 : 157|10@0+ (0.1,0) [0|100] "A"  FLZCU_VCU_EP,FLZCU_PDCS_EP,VCU_EP,PDCS_EP,PDCS_EP_E0V,FmcuVcu_EP,FmcuVcu_EP_E0V

BO_TX_BU_ 1127 : CDU,RmcuCdu,RmcuCdu_E0V;

BO_TX_BU_ 1182 : CDU,RmcuCdu,RmcuCdu_E0V;

CM_ "Version:V1.0,Date:2023.09.01,Author:XianliZhang,Review:ZhonglinWang,Approval:JiancaiLi,Description:()first version;
Version:V1.1,Date:2023.09.08,Author:XianliZhang,Review:ZhonglinWang,Approval:JiancaiLi,Description:(FLZCU_15(0x42F))delete signal for FLZCU_IC:
FLZCU_PowerOFFWarning
FLZCU_KeyValidSts
FLZCU_KeylessWarning`
(FLZCU_TO_FRZCU(0x4C0))change Signal Name for FLZCU_GL:
FLZCU_RLChildLockSts to FLZCU_RL_ChildrenProtectSwitch
FLZCU_FogLightReq to FLZCU_RearFogLightReq;
 ";

CM_ BO_ 1230 "Multiplexed Signal";
CM_ SG_ 33 ACU_3_CRC1 "Profile1A:E2E CRC (SAE J1850 CRC-8) for 8 Bytes
DataID:0x0002";
CM_ SG_ 33 ACU_3_RollgCntr1 "Profile1A:E2E Rolling message counter(the maximum value of Alive counter is 14)";
CM_ SG_ 33 ACU_3_Resd1 "Profile1A:E2E Reserved";
CM_ SG_ 33 ACU_3_LongitudinalAcceleration "Longitudinal acceleration signal
Sensor accuracy��0.0027680342857143 g";
CM_ SG_ 33 ACU_3_LongitudinalAccelerationVD "If hasn��t been calibrated, after initialization, this signal ��s value is always10(invalid)";
CM_ SG_ 33 ACU_3_CrashOutputSts "Crash signal indicates the status according to bit:
If multiple directions collide at the same time, each collision flag bit representing each direction will be set to 1.For example, if left crash is superimposed with right crash, the output signal is 00001100
���źŷ���ECUֹͣ����Ϊֹ";
CM_ SG_ 1299 BMS_1_G_CRC "Profile1A:E2E CRC (SAE J1850 CRC-8) for 8 Bytes
DataID:No ASIL requirements.Not configure
CRC Reserved.";
CM_ SG_ 1299 BMS_1_G_RollgCntr "Profile1A:E2E Rolling message counter(the maximum value of Alive counter is 14)";
CM_ SG_ 1299 BMS_1_G_Resd "Profile1A:E2E Reserved";
CM_ SG_ 1299 BMS_PackVoltageDis "Battery Voltage";
CM_ SG_ 1299 BMS_PackCurrentDis "Baattery Current(direction:discharge+ charge -)";
CM_ SG_ 1299 BMS_TBOXErrorCode "BMS Error Code";
CM_ SG_ 1291 BMS_2_G_CRC "Profile1A:E2E CRC (SAE J1850 CRC-8) for 8 Bytes
DataID:0x0075";
CM_ SG_ 1291 BMS_2_G_RollgCntr "Profile1A:E2E Rolling message counter(the maximum value of Alive counter is 14)";
CM_ SG_ 1291 BMS_2_G_Resd "Profile1A:E2E Reserved";
CM_ SG_ 1291 BMS_TBOXInsulation_R "insulation resistance";
CM_ SG_ 1291 BMS_TBOXErrorNumber "BMS Error Numbers";
CM_ SG_ 1291 BMS_TBOXHvBattMaxT "battery max temperature";
CM_ SG_ 1291 BMS_TBOXHvBattMinT "battery min temperature";
CM_ SG_ 1291 BMS_SOCLight "BMS_SOCLight";
CM_ SG_ 1295 BMS_3_G_CRC "Profile1A:E2E CRC (SAE J1850 CRC-8) for 8 Bytes
DataID:0x0076";
CM_ SG_ 1295 BMS_3_G_RollgCntr "Profile1A:E2E Rolling message counter(the maximum value of Alive counter is 14)";
CM_ SG_ 1295 BMS_3_G_Resd "Profile1A:E2E Reserved";
CM_ SG_ 1295 BMS_RemainChg_Time "BMS_RemainChg_Time";
CM_ SG_ 1295 BMS_HvBattErrSt "BMS error state";
CM_ SG_ 1295 BMS_OverTemp_LightSts "BMS_OverTemp_LightSts";
CM_ SG_ 1295 BMS_ChgWireConnect_LightSts "BMS_ChgWireConnect_LightSts";
CM_ SG_ 1295 BMS_Chg_LightSts "BMS_Chg_LightSts";
CM_ SG_ 1295 BMS_HVstsDis "BMS power cut off indication";
CM_ SG_ 1295 BMS_ThermalRunawayDis "Thermal run-away";
CM_ SG_ 1295 BMS_TBOXIsolationFault "battery insulation fault state";
CM_ SG_ 1295 BMS_TBOXHVIL1Fault "high voltage inter lock 1 fault";
CM_ SG_ 1295 BMS_PreWarmDis "preheat and keepwarm indication";
CM_ SG_ 258 BMS_1_CRC1 "Profile1A:E2E CRC (SAE J1850 CRC-8) for 8 Bytes
DataID:0x0014";
CM_ SG_ 258 BMS_1_RollgCntr1 "Profile1A:E2E Rolling message counter(the maximum value of Alive counter is 14)";
CM_ SG_ 258 BMS_1_Resd1 "Profile1A:E2E Reserved";
CM_ SG_ 258 BMS_PackVoltage "Battery Voltage";
CM_ SG_ 258 BMS_PackCurrent "Baattery Current(direction:discharge+ charge -)";
CM_ SG_ 258 BMS_HvBattSts "Battery State";
CM_ SG_ 258 BMS_SysSelfCheck "BMS Slef Check State";
CM_ SG_ 258 BMS_HVBattThermRunaway "Thermal Run-away";
CM_ SG_ 258 BMS_1_CRC2 "Profile1A:E2E CRC (SAE J1850 CRC-8) for 8 Bytes
DataID:No ASIL requirements.Not configure
CRC Reserved.";
CM_ SG_ 258 BMS_1_RollgCntr2 "Profile1A:E2E Rolling message counter(the maximum value of Alive counter is 14)";
CM_ SG_ 258 BMS_1_Resd2 "Profile1A:E2E Reserved";
CM_ SG_ 258 BMS_DcDisChgCurrReq "ֱ���ŵ��������";
CM_ SG_ 258 BMS_C2Target_Buck_Voltage "����ѹĿ���ѹ";
CM_ SG_ 258 BMS_DisChrgDcCnctrDetd "ֱ����ŵ�ǹ����״̬";
CM_ SG_ 258 BMS_InfraDcUActDc "DC-charge station actual ouput voltage(only for BMS internal analysis)";
CM_ SG_ 258 BMS_1_CRC3 "Profile1A:E2E CRC (SAE J1850 CRC-8) for 8 Bytes
DataID:0x0015";
CM_ SG_ 258 BMS_1_RollgCntr3 "Profile1A:E2E Rolling message counter(the maximum value of Alive counter is 14)";
CM_ SG_ 258 BMS_1_Resd3 "Profile1A:E2E Reserved";
CM_ SG_ 258 BMS_InfraDcIActDc "DC-charge station actual ouput current(only for BMS internal analysis)";
CM_ SG_ 258 BMS_HvBattDynChrgnILim "battery chagre current limit";
CM_ SG_ 258 BMS_HvBattUChrgnLim "battery chagre voltage limit";
CM_ SG_ 258 BMS_1_CRC4 "Profile1A:E2E CRC (SAE J1850 CRC-8) for 8 Bytes
DataID:0x0016";
CM_ SG_ 258 BMS_1_RollgCntr4 "Profile1A:E2E Rolling message counter(the maximum value of Alive counter is 14)";
CM_ SG_ 258 BMS_1_Resd4 "Profile1A:E2E Reserved";
CM_ SG_ 258 BMS_ChrgDcIAvl "DC-charge station charging current limit";
CM_ SG_ 258 BMS_DChrgAPlusSt "DC A+ status";
CM_ SG_ 258 BMS_Insulation_R "insulation resistance";
CM_ SG_ 258 BMS_ChrgDcCnctrDetd "CC2 connect state";
CM_ SG_ 258 BMS_DCChgMode "DC charge mode";
CM_ SG_ 258 BMS_ChrgDcChrgnFltStopReas "Dc charge stop reason";
CM_ SG_ 258 BMS_1_CRC5 "Profile1A:E2E CRC (SAE J1850 CRC-8) for 8 Bytes
DataID:0x0017";
CM_ SG_ 258 BMS_1_RollgCntr5 "Profile1A:E2E Rolling message counter(the maximum value of Alive counter is 14)";
CM_ SG_ 258 BMS_1_Resd5 "Profile1A:E2E Reserved";
CM_ SG_ 258 BMS_ChgRemTime "remain charging time";
CM_ SG_ 258 BMS_ChargeRequest_Mode "charge request mode";
CM_ SG_ 258 BMS_StateOfChargeDis "battery indication SOC";
CM_ SG_ 258 BMS_StateOfEnergy "battery SOE";
CM_ SG_ 258 BMS_1_CRC6 "Profile1A:E2E CRC (SAE J1850 CRC-8) for 8 Bytes
DataID:0x0018";
CM_ SG_ 258 BMS_1_RollgCntr6 "Profile1A:E2E Rolling message counter(the maximum value of Alive counter is 14)";
CM_ SG_ 258 BMS_1_Resd6 "Profile1A:E2E Reserved";
CM_ SG_ 258 BMS_StateOfHealth "battery SOH";
CM_ SG_ 258 BMS_BlanceState "battery balance state";
CM_ SG_ 258 BMS_IsolationFault "battery insulation fault state";
CM_ SG_ 258 BMS_HVILFault_DC "DC internal HVIL fault";
CM_ SG_ 258 BMS_HVILFault_FMCU "FMCU internal HVIL fault";
CM_ SG_ 258 BMS_HVILFault_RMCU "RMCU internal HVIL fault";
CM_ SG_ 258 BMS_SOCDis "battery indication SOC";
CM_ SG_ 258 BMS_InfraDcIActDcMin "DC-charge station actual ouput current(only for BMS internal analysis)";
CM_ SG_ 520 BMS_2_CRC1 "Profile1A:E2E CRC (SAE J1850 CRC-8) for 8 Bytes
DataID:0x007E";
CM_ SG_ 520 BMS_2_RollgCntr1 "Profile1A:E2E Rolling message counter(the maximum value of Alive counter is 14)";
CM_ SG_ 520 BMS_2_Resd1 "Profile1A:E2E Reserved";
CM_ SG_ 520 BMS_C2Target_Chg_Voltage "BMS_C2Target_Chg_Voltage";
CM_ SG_ 520 BMS_CHGstation_MAXPwr "BMS_CHGstation_MAXPwr";
CM_ SG_ 520 BMS_2_CRC2 "Profile1A:E2E CRC (SAE J1850 CRC-8) for 8 Bytes
DataID:0x0019";
CM_ SG_ 520 BMS_2_RollgCntr2 "Profile1A:E2E Rolling message counter(the maximum value of Alive counter is 14)";
CM_ SG_ 520 BMS_2_Resd2 "Profile1A:E2E Reserved";
CM_ SG_ 520 BMS_NV_relay_Sts "Main NEG Rely State";
CM_ SG_ 520 BMS_PV_relay_Sts "Main POS Rely State";
CM_ SG_ 520 BMS_QCP_relay_Sts "DC-CHG POS Rely State";
CM_ SG_ 520 BMS_QCN_relay_Sts "DC-CHG NEG Rely State";
CM_ SG_ 520 BMS_Prechage_relay_Sts "Pre-Charge Rely State";
CM_ SG_ 520 BMS_HvBattThermReqMode "Battery Thermal Management Request";
CM_ SG_ 520 BMS_ClntTHvBattIn "battery inlet temperature";
CM_ SG_ 520 BMS_ClntTHvBattOut "battery oulet temperature";
CM_ SG_ 520 BMS_HvBattClntInTReq "battery inlet teperature request";
CM_ SG_ 520 BMS_2_CRC3 "Profile1A:E2E CRC (SAE J1850 CRC-8) for 8 Bytes
DataID:0x001A";
CM_ SG_ 520 BMS_2_RollgCntr3 "Profile1A:E2E Rolling message counter(the maximum value of Alive counter is 14)";
CM_ SG_ 520 BMS_2_Resd3 "Profile1A:E2E Reserved";
CM_ SG_ 520 BMS_HvBattClntFlowReq "water flow request";
CM_ SG_ 520 BMS_HvBattAvgT "battery average temperature";
CM_ SG_ 520 BMS_HvBattMaxT "battery max temperature";
CM_ SG_ 520 BMS_HvBattMinT "battery min temperature";
CM_ SG_ 520 BMS_HvBattTdiff "battery temperature differences";
CM_ SG_ 520 BMS_2_CRC4 "Profile1A:E2E CRC (SAE J1850 CRC-8) for 8 Bytes
DataID:0x001B";
CM_ SG_ 520 BMS_2_RollgCntr4 "Profile1A:E2E Rolling message counter(the maximum value of Alive counter is 14)";
CM_ SG_ 520 BMS_2_Resd4 "Profile1A:E2E Reserved";
CM_ SG_ 520 BMS_OutPosU "POS Mian-rely outside voltage";
CM_ SG_ 520 BMS_OutNegU "NEG Mian-rely outside voltage";
CM_ SG_ 520 BMS_ChrgTrgtSOC "����ֹSOC����";
CM_ SG_ 520 BMS_2_CRC5 "Profile1A:E2E CRC (SAE J1850 CRC-8) for 8 Bytes
DataID:0x001C";
CM_ SG_ 520 BMS_2_RollgCntr5 "Profile1A:E2E Rolling message counter(the maximum value of Alive counter is 14)";
CM_ SG_ 520 BMS_2_Resd5 "Profile1A:E2E Reserved";
CM_ SG_ 520 BMS_outQCPosU "POS DC rely outside voltage";
CM_ SG_ 520 BMS_outQCNegU "NEG DC rely outside voltage";
CM_ SG_ 520 BMS_Middlesplit_relay_Sts "Middlesplit Rely State";
CM_ SG_ 520 BMS_BattCurrtSnsr1 "Pack��һ������������ֵ";
CM_ SG_ 520 BMS_BattCurrtSnsr2 "Pack�ڶ�������������ֵ";
CM_ SG_ 523 BMS_3_CRC1 "Profile1A:E2E CRC (SAE J1850 CRC-8) for 8 Bytes
DataID:0x001D";
CM_ SG_ 523 BMS_3_RollgCntr1 "Profile1A:E2E Rolling message counter(the maximum value of Alive counter is 14)";
CM_ SG_ 523 BMS_3_Resd1 "Profile1A:E2E Reserved";
CM_ SG_ 523 BMS_HvBattPMaxReChrgLim "BMS max recharge power (10s)";
CM_ SG_ 523 BMS_3_CRC2 "Profile1A:E2E CRC (SAE J1850 CRC-8) for 8 Bytes
DataID:0x001E";
CM_ SG_ 523 BMS_3_RollgCntr2 "Profile1A:E2E Rolling message counter(the maximum value of Alive counter is 14)";
CM_ SG_ 523 BMS_3_Resd2 "Profile1A:E2E Reserved";
CM_ SG_ 523 BMS_HvBattIMaxReChrgLim "BMS max recharge current  (10s)";
CM_ SG_ 523 BMS_HvBattPMaxDchaLim "BMS max discharge power (10s)";
CM_ SG_ 523 BMS_3_CRC3 "Profile1A:E2E CRC (SAE J1850 CRC-8) for 8 Bytes
DataID:0x001F";
CM_ SG_ 523 BMS_3_RollgCntr3 "Profile1A:E2E Rolling message counter(the maximum value of Alive counter is 14)";
CM_ SG_ 523 BMS_3_Resd3 "Profile1A:E2E Reserved";
CM_ SG_ 523 BMS_HvBattIMaxDchaLim "BMS max discharge current (10s)";
CM_ SG_ 523 BMS_3_CRC4 "Profile1A:E2E CRC (SAE J1850 CRC-8) for 8 Bytes
DataID:No ASIL requirements.Not configure
CRC Reserved.";
CM_ SG_ 523 BMS_3_RollgCntr4 "Profile1A:E2E Rolling message counter(the maximum value of Alive counter is 14)";
CM_ SG_ 523 BMS_3_Resd4 "Profile1A:E2E Reserved";
CM_ SG_ 523 BMS_3_CRC5 "Profile1A:E2E CRC (SAE J1850 CRC-8) for 8 Bytes
DataID:0x0020";
CM_ SG_ 523 BMS_3_RollgCntr5 "Profile1A:E2E Rolling message counter(the maximum value of Alive counter is 14)";
CM_ SG_ 523 BMS_3_Resd5 "Profile1A:E2E Reserved";
CM_ SG_ 523 BMS_KL30Volt "12V voltage";
CM_ SG_ 523 BMS_kL87Volt "KL87 voltage";
CM_ SG_ 523 BMS_HvBattUDchaLim "lowest discharge voltage limitation";
CM_ SG_ 523 BMS_3_CRC6 "Profile1A:E2E CRC (SAE J1850 CRC-8) for 8 Bytes
DataID:No ASIL requirements.Not configure
CRC Reserved.";
CM_ SG_ 523 BMS_3_RollgCntr6 "Profile1A:E2E Rolling message counter(the maximum value of Alive counter is 14)";
CM_ SG_ 523 BMS_3_Resd6 "Profile1A:E2E Reserved";
CM_ SG_ 523 BMSH_MaxChgPwrPeak "Maximum Charge Power Peak";
CM_ SG_ 523 BMSH_MaxDchgPwrPeak "Maximum Discharge Power Peak";
CM_ SG_ 1055 BMS_4_CRC1 "Profile1A:E2E CRC (SAE J1850 CRC-8) for 8 Bytes
DataID:No ASIL requirements.Not configure
CRC Reserved.";
CM_ SG_ 1055 BMS_4_RollgCntr1 "Profile1A:E2E Rolling message counter(the maximum value of Alive counter is 14)";
CM_ SG_ 1055 BMS_4_Resd1 "Profile1A:E2E Reserved";
CM_ SG_ 1055 BMS_ErrorNumber "BMS Error Numbers";
CM_ SG_ 1055 BMS_ErrorCode "BMS Error Code";
CM_ SG_ 1055 BMS_4_CRC2 "Profile1A:E2E CRC (SAE J1850 CRC-8) for 8 Bytes
DataID:0x0021";
CM_ SG_ 1055 BMS_4_RollgCntr2 "Profile1A:E2E Rolling message counter(the maximum value of Alive counter is 14)";
CM_ SG_ 1055 BMS_4_Resd2 "Profile1A:E2E Reserved";
CM_ SG_ 1055 BMSH_MILReq "MIL request";
CM_ SG_ 1055 BMS_ErrorLevel "BMS Error Levels";
CM_ SG_ 1055 BMS_HvBattUnderTemperature "battery under temperature flag";
CM_ SG_ 1055 BMS_ThermRunCode "thermal runaway reason flag";
CM_ SG_ 1055 BMS_DChrgEndCode "DC charge end reason flag";
CM_ SG_ 1055 BMS_PwrDerateFlg "BMS���ʱջ������޹��ʱ�־λ";
CM_ SG_ 1055 BMS_CHGstation_LowPWRFlg "���׮���������ʹ���Ԥ��";
CM_ SG_ 1055 BMS_bHint4FullChrgFlg "���ź���������Ϊ��־λ��������ʾ�ͻ��������䣻
0���Ǳ�������ʾ�ͻ��������䣻
1���Ǳ���Ҫ��ʾ�ͻ��������䣻";
CM_ SG_ 1055 BMS_StateOfChargeDis "battery indication SOC";
CM_ SG_ 1055 BMS_FastChargingFlg "��䳬�����״̬";
CM_ SG_ 1055 BMS_LowCellVltChrgFlg "Cell Discharge too much, need charge battery";
CM_ SG_ 1055 BMS_EngineStartReq "���ڷ���VCU�ڵ����ʵSOC���";
CM_ SG_ 1525 BMS_SoftWareVersion "BMS software version";
CM_ SG_ 811 BMS_6_CRC1 "Profile1A:E2E CRC (SAE J1850 CRC-8) for 8 Bytes
DataID:0x0022";
CM_ SG_ 811 BMS_6_RollgCntr1 "Profile1A:E2E Rolling message counter(the maximum value of Alive counter is 14)";
CM_ SG_ 811 BMS_6_Resd1 "Profile1A:E2E Reserved";
CM_ SG_ 811 BMS_HvBattCellVoltMax_Num "highest voltage cell number";
CM_ SG_ 811 BMS_HvBattCellVoltMax "highest cell voltage";
CM_ SG_ 811 BMS_HvBattCellVoltMin_Num "lowest voltage cell number";
CM_ SG_ 811 BMS_HvBattCellVoltMin "lowest cell voltage";
CM_ SG_ 811 BMS_6_CRC2 "Profile1A:E2E CRC (SAE J1850 CRC-8) for 8 Bytes
DataID:No ASIL requirements.Not configure
CRC Reserved.";
CM_ SG_ 811 BMS_6_RollgCntr2 "Profile1A:E2E Rolling message counter(the maximum value of Alive counter is 14)";
CM_ SG_ 811 BMS_6_Resd2 "Profile1A:E2E Reserved";
CM_ SG_ 811 BMS_Chg_Sts "BMS_Chg_Sts";
CM_ SG_ 811 BMS_PackSOCNotAvrlble "������SOC";
CM_ SG_ 811 BMS_DchaPwrContnsMax "��س����ŵ繦��";
CM_ SG_ 811 BMS_ChrgPwrContnsMax "��س�����繦��";
CM_ SG_ 811 BMS_APlusWakeupSt "A+����Դ״̬";
CM_ SG_ 811 BMS_KL15WakeupSt "Ӳ�߻���Դ״̬";
CM_ SG_ 811 BMSH_CHGPrechargeRelaySts "charge precharge relay status";
CM_ SG_ 1290 BMS_8_CRC1 "Profile1A:E2E CRC (SAE J1850 CRC-8) for 8 Bytes
DataID:0x0023";
CM_ SG_ 1290 BMS_8_RollgCntr1 "Profile1A:E2E Rolling message counter(the maximum value of Alive counter is 14)";
CM_ SG_ 1290 BMS_8_Resd1 "Profile1A:E2E Reserved";
CM_ SG_ 1290 BMS_HvBattCellOverU "battey cell over voltage fault";
CM_ SG_ 1290 BMS_HvBattCellUnderU "battey cell under voltage fault";
CM_ SG_ 1290 BMS_HvBattUnderU "battey over voltage fault";
CM_ SG_ 1290 BMS_HvBattDischargeOverCurrent "dischagre over current";
CM_ SG_ 1290 BMS_HvBattChargeOverCurrent "chagre over current";
CM_ SG_ 1290 BMS_HvBattOverU "battey under voltage fault";
CM_ SG_ 1290 BMS_HvBattMismatching "battery system dis-match";
CM_ SG_ 1290 BMS_HvBattSocJump "battery SOC jump";
CM_ SG_ 1290 BMS_HvBattCellUUnif "battery cell voltage difference fault";
CM_ SG_ 1290 BMS_HvBattLowSoc "SOC too low";
CM_ SG_ 1290 BMS_HvBattOverSoc "SOC too high";
CM_ SG_ 1290 BMS_HvBattTempUniformity "battery temperature difference fault";
CM_ SG_ 1290 BMS_BattInterCANErr "BMS inter CAN fault";
CM_ SG_ 1290 BMS_HvBattOverCharging "battery over charge";
CM_ SG_ 1290 BMS_HvBattOverTemperature "battery over temperature";
CM_ SG_ 1290 BMS_PrimaryCurrtSnsrTemp "��һ�����������¶�ֵ";
CM_ SG_ 1290 BMS_EquTempMax "���������¶�";
CM_ SG_ 1531 BMS_9_CRC1 "Profile1A:E2E CRC (SAE J1850 CRC-8) for 8 Bytes
DataID:No ASIL requirements.Not configure
CRC Reserved.";
CM_ SG_ 1531 BMS_9_RollgCntr1 "Profile1A:E2E Rolling message counter(the maximum value of Alive counter is 14)";
CM_ SG_ 1531 BMS_9_Resd1 "Profile1A:E2E Reserved";
CM_ SG_ 1531 BMS_HvBattSoeActDisChaCyc "actual discahrge power acumulation in one driving cycle";
CM_ SG_ 1531 BMS_HvBattSoeActReChaCyc "actual recahrge power acumulation in one driving cycle";
CM_ SG_ 1531 BMS_HvBattRatedEnergy "battery  rated energy";
CM_ SG_ 1531 BMS_HvBattRatedU "battery  rated voltage";
CM_ SG_ 1531 BMS_HvBattTypeCode "battery type";
CM_ SG_ 1531 BMS_HvBattManufcCode "battery manufacture code";
CM_ SG_ 1531 BMS_HvBattTempSensorTotalNum "battery cell temperature sensor numbers";
CM_ SG_ 1531 BMS_HvBattTempSensorTempMaxNum "highest cell temperature sensor number";
CM_ SG_ 1531 BMS_HvBattTempSensorTempMinNum "lowest cell temperature sensor number";
CM_ SG_ 1531 BMS_HvBattTempMaxNum "highest temperature module number";
CM_ SG_ 1531 BMS_HvBattTempMinNum "lowest temperature module number";
CM_ SG_ 1531 BMS_BattCellTotalNum "battery cell numbers";
CM_ SG_ 1531 BMS_HvBattVoltMaxNum "highest cell voltage module number";
CM_ SG_ 1531 BMS_HvBattVoltMinNum "lowest cell voltage module number";
CM_ SG_ 1531 BMS_ActualSOCMin "��С��ʵSOC";
CM_ SG_ 1531 BMS_ActualSOCMax "�����ʵSOC";
CM_ SG_ 1535 BMS_HvBattTempSensorTemp_1T "cell temperature sensor 1T��cyclic��";
CM_ SG_ 1535 BMS_HvBattTempSensorTemp_2T "cell temperature sensor 2T��cyclic��";
CM_ SG_ 1535 BMS_HvBattTempSensorTemp_3T "cell temperature sensor 3T��cyclic��";
CM_ SG_ 1535 BMS_HvBattTempSensorTemp_4T "cell temperature sensor 4T��cyclic��";
CM_ SG_ 1535 BMS_HvBattTempSensorTemp_5T "cell temperature sensor 5T��cyclic��";
CM_ SG_ 1535 BMS_HvBattTempSensorTemp_6T "cell temperature sensor 6T��cyclic��";
CM_ SG_ 1535 BMS_HvBattTempSensorTemp_7T "cell temperature sensor 7T��cyclic��";
CM_ SG_ 1535 BMS_HvBattTempSensorTemp_8T "cell temperature sensor 8T��cyclic��";
CM_ SG_ 1535 BMS_HvBattTempSensorTemp_9T "cell temperature sensor 9T��cyclic��";
CM_ SG_ 1535 BMS_HvBattTempSensorTemp_10T "cell temperature sensor 10T��cyclic��";
CM_ SG_ 1535 BMS_HvBattTempSensorTemp_11T "cell temperature sensor 11T��cyclic��";
CM_ SG_ 1535 BMS_HvBattTempSensorTemp_12T "cell temperature sensor 12T��cyclic��";
CM_ SG_ 1535 BMS_HvBattTempSensorTemp_13T "cell temperature sensor 13T��cyclic��";
CM_ SG_ 1535 BMS_HvBattTempSensorTemp_14T "cell temperature sensor 14T��cyclic��";
CM_ SG_ 1535 BMS_HvBattTempSensorTemp_15T "cell temperature sensor 15T��cyclic��";
CM_ SG_ 1535 BMS_HvBattTempSensorTemp_16T "cell temperature sensor 16T��cyclic��";
CM_ SG_ 1535 BMS_HvBattTempSensorTemp_17T "cell temperature sensor 17T��cyclic��";
CM_ SG_ 1535 BMS_HvBattTempSensorTemp_18T "cell temperature sensor 18T��cyclic��";
CM_ SG_ 1535 BMS_HvBattTempSensorTemp_19T "cell temperature sensor 19T��cyclic��";
CM_ SG_ 1535 BMS_HvBattTempSensorTemp_20T "cell temperature sensor 20T��cyclic��";
CM_ SG_ 1535 BMS_HvBattTempSensorTemp_21T "cell temperature sensor 21T��cyclic��";
CM_ SG_ 1535 BMS_HvBattTempSensorTemp_22T "cell temperature sensor 22T��cyclic��";
CM_ SG_ 1535 BMS_HvBattTempSensorTemp_23T "cell temperature sensor 23T��cyclic��";
CM_ SG_ 1535 BMS_HvBattTempSensorTemp_24T "cell temperature sensor 24T��cyclic��";
CM_ SG_ 1535 BMS_HvBattTempSensorTemp_25T "cell temperature sensor 25T��cyclic��";
CM_ SG_ 1535 BMS_HvBattTempSensorTemp_26T "cell temperature sensor 26T��cyclic��";
CM_ SG_ 1535 BMS_HvBattTempSensorTemp_27T "cell temperature sensor 27T��cyclic��";
CM_ SG_ 1535 BMS_HvBattTempSensorTemp_28T "cell temperature sensor 28T��cyclic��";
CM_ SG_ 1535 BMS_HvBattTempSensorTemp_29T "cell temperature sensor 29T��cyclic��";
CM_ SG_ 1535 BMS_HvBattTempSensorTemp_30T "cell temperature sensor 30T��cyclic��";
CM_ SG_ 1535 BMS_HvBattTempSensorTemp_31T "cell temperature sensor 31T��cyclic��";
CM_ SG_ 1535 BMS_HvBattTempSensorTemp_32T "cell temperature sensor 32T��cyclic��";
CM_ SG_ 1535 BMS_HvBattTempSensorTemp_33T "cell temperature sensor 33T��cyclic��";
CM_ SG_ 1535 BMS_HvBattTempSensorTemp_34T "cell temperature sensor 34T��cyclic��";
CM_ SG_ 1535 BMS_HvBattTempSensorTemp_35T "cell temperature sensor 35T��cyclic��";
CM_ SG_ 1535 BMS_HvBattTempSensorTemp_36T "cell temperature sensor 36T��cyclic��";
CM_ SG_ 1535 BMS_HvBattTempSensorTemp_37T "cell temperature sensor 37T��cyclic��";
CM_ SG_ 1535 BMS_HvBattTempSensorTemp_38T "cell temperature sensor 38T��cyclic��";
CM_ SG_ 1535 BMS_HvBattTempSensorTemp_39T "cell temperature sensor 39T��cyclic��";
CM_ SG_ 1535 BMS_HvBattTempSensorTemp_40T "cell temperature sensor 40T��cyclic��";
CM_ SG_ 1535 BMS_HvBattTempSensorTemp_41T "cell temperature sensor 41T��cyclic��";
CM_ SG_ 1535 BMS_HvBattTempSensorTemp_42T "cell temperature sensor 42T��cyclic��";
CM_ SG_ 1535 BMS_HvBattTempSensorTemp_43T "cell temperature sensor 43T��cyclic��";
CM_ SG_ 1535 BMS_HvBattTempSensorTemp_44T "cell temperature sensor 44T��cyclic��";
CM_ SG_ 1535 BMS_HvBattTempSensorTemp_45T "cell temperature sensor 45T��cyclic��";
CM_ SG_ 1535 BMS_HvBattTempSensorTemp_46T "cell temperature sensor 46T��cyclic��";
CM_ SG_ 1535 BMS_HvBattTempSensorTemp_47T "cell temperature sensor 47T��cyclic��";
CM_ SG_ 1535 BMS_HvBattTempSensorTemp_48T "cell temperature sensor 48T��cyclic��";
CM_ SG_ 1535 BMS_BattTempSensorStartFrameNum "cell temperature sensor start number of this frame";
CM_ SG_ 1535 BMS_HvBattTempSensorFrameTNum "cell temperature sensor total numbers of this frame";
CM_ SG_ 1340 BMS_HvBattSerialNum_PDU1 "battery serial number��cycle��Battery 24 GB code��";
CM_ SG_ 1340 BMS_HvBattSerialNum_PDU2 "battery serial number��cycle��Battery 24 GB code��";
CM_ SG_ 1340 BMS_HvBattSerialNum_PDU3 "battery serial number��cycle��Battery 24 GB code��";
CM_ SG_ 1340 BMS_HvBattSerialNum_PDU4 "battery serial number��cycle��Battery 24 GB code��";
CM_ SG_ 1340 BMS_HvBattSerialNum_PDU5 "battery serial number��cycle��Battery 24 GB code��";
CM_ SG_ 1340 BMS_HvBattSerialNum_PDU6 "battery serial number��cycle��Battery 24 GB code��";
CM_ SG_ 1224 BMS_HvBattCellVoltMax_Num "highest voltage cell number";
CM_ SG_ 1224 BMS_HvBattCellVoltMax "highest cell voltage";
CM_ SG_ 1224 BMS_HvBattCellVoltMin_Num "lowest voltage cell number";
CM_ SG_ 1224 BMS_HvBattCellVoltMin "lowest cell voltage";
CM_ SG_ 1224 BMS_Chg_Sts "BMS_Chg_Sts";
CM_ SG_ 1230 BMS_HvBattCellU_1V "cell voltage 1V��cyclic��";
CM_ SG_ 1230 BMS_HvBattCellU_2V "cell voltage 2V��cyclic��";
CM_ SG_ 1230 BMS_HvBattCellU_3V "cell voltage 3V��cyclic��";
CM_ SG_ 1230 BMS_HvBattCellU_4V "cell voltage 4V��cyclic��";
CM_ SG_ 1230 BMS_HvBattCellU_5V "cell voltage 5V��cyclic��";
CM_ SG_ 1230 BMS_HvBattCellU_6V "cell voltage 6V��cyclic��";
CM_ SG_ 1230 BMS_HvBattCellU_7V "cell voltage 7V��cyclic��";
CM_ SG_ 1230 BMS_HvBattCellU_8V "cell voltage 8V��cyclic��";
CM_ SG_ 1230 BMS_HvBattCellU_9V "cell voltage 9V��cyclic��";
CM_ SG_ 1230 BMS_HvBattCellU_10V "cell voltage 10V��cyclic��";
CM_ SG_ 1230 BMS_HvBattCellU_11V "cell voltage 11V��cyclic��";
CM_ SG_ 1230 BMS_HvBattCellU_12V "cell voltage 12V��cyclic��";
CM_ SG_ 1230 BMS_HvBattCellU_13V "cell voltage 13V��cyclic��";
CM_ SG_ 1230 BMS_HvBattCellU_14V "cell voltage 14V��cyclic��";
CM_ SG_ 1230 BMS_HvBattCellU_15V "cell voltage 15V��cyclic��";
CM_ SG_ 1230 BMS_HvBattCellU_16V "cell voltage 16V��cyclic��";
CM_ SG_ 1230 BMS_HvBattCellU_17V "cell voltage 17V��cyclic��";
CM_ SG_ 1230 BMS_HvBattCellU_18V "cell voltage 18V��cyclic��";
CM_ SG_ 1230 BMS_HvBattCellU_19V "cell voltage 19V��cyclic��";
CM_ SG_ 1230 BMS_HvBattCellU_20V "cell voltage 20V��cyclic��";
CM_ SG_ 1230 BMS_HvBattCellU_21V "cell voltage 21V��cyclic��";
CM_ SG_ 1230 BMS_HvBattCellU_22V "cell voltage 22V��cyclic��";
CM_ SG_ 1230 BMS_HvBattCellU_23V "cell voltage 23V��cyclic��";
CM_ SG_ 1230 BMS_HvBattCellU_24V "cell voltage 24V��cyclic��";
CM_ SG_ 1230 BMS_HvBattCellU_25V "cell voltage 25V��cyclic��";
CM_ SG_ 1230 BMS_HvBattCellU_26V "cell voltage 26V��cyclic��";
CM_ SG_ 1230 BMS_HvBattCellU_27V "cell voltage 27V��cyclic��";
CM_ SG_ 1230 BMS_HvBattCellU_28V "cell voltage 28V��cyclic��";
CM_ SG_ 1230 BMS_HvBattCellU_29V "cell voltage 29V��cyclic��";
CM_ SG_ 1230 BMS_HvBattCellU_30V "cell voltage 30V��cyclic��";
CM_ SG_ 1230 BMS_BattCellstartframeNum "cell start number of this frame";
CM_ SG_ 1230 BMS_HvBattCellFrameTotalNum "cell total numbers of this frame";
CM_ SG_ 1041 BMS_InsulationPos "��Ե���ɼ�������Ե���裨���귨��Rp";
CM_ SG_ 1041 BMS_IsoPosVolt "��Ե���������ѹ����������ֵ��";
CM_ SG_ 1041 BMS_IsoNegVolt "��Ե��⸺����ѹ����������ֵ��";
CM_ SG_ 1041 BMS_IsoPosSwtSts "��Ե�����������״̬";
CM_ SG_ 1041 BMS_IsoNegSwtSts "��Ե��⸺������״̬";
CM_ SG_ 1041 BCL_ChareMode "���ģʽ";
CM_ SG_ 1041 BMS_HVPwrDwnRsn "BMS�¸�ѹԭ��";
CM_ SG_ 1041 BMS_InsulationProhibitRsn "BMS��ֹ��Եԭ��";
CM_ SG_ 1041 BMS_BPSWakeupSt "BPS����Դ״̬";
CM_ SG_ 1041 BMS_AFEWakeupSt "AFE����Դ״̬";
CM_ SG_ 1041 BMS_NMWakeupSt "NM����Դ״̬";
CM_ SG_ 1041 BMS_CC2WakeupSt "CC2����Դ״̬";
CM_ SG_ 1041 CCS_ChargeAllowed "�������";
CM_ SG_ 1041 BMS_ResetRsn "BMS��λԭ��
0x0:Normal
0x3F:Invalid";
CM_ SG_ 1041 BMS_HVPwrOnFailRsn "BMS�ϸ�ѹʧ��ԭ��
0x0:Normal
0x3F:Invalid";
CM_ SG_ 1041 BMS_AirPressure "��ѹ";
CM_ SG_ 1041 BMS_AirPressureRate "��ѹ�仯��";
CM_ SG_ 1041 BMS_BattTempRate "�¶ȱ仯��";
CM_ SG_ 1041 BMS_CellVoltSum "��о��ѹ�ۼӺ�";
CM_ SG_ 1041 BMS_DchaCurrtShoTiMax "��ض�ʱ�ŵ����";
CM_ SG_ 1041 BMS_ChrgCurrtShoTiMax "��ض�ʱ������";
CM_ SG_ 1041 BMS_DchaPwrLongTiMax "��س�ʱ�ŵ繦��";
CM_ SG_ 1041 BMS_ChrgPwrLongTiMax "��س�ʱ��繦��";
CM_ SG_ 1041 BMS_DchaCurrtLongTiMax "��س�ʱ�ŵ����";
CM_ SG_ 1041 BMS_ChrgCurrtLongTiMax "��س�ʱ������";
CM_ SG_ 1041 BMS_DchaCurrtContnsMax "��س����ŵ����";
CM_ SG_ 1041 BMS_ChrgCurrtContnsMax "��س���������";
CM_ SG_ 1041 BRO_BMSChargeReady "BMS�Ƿ�׼����";
CM_ SG_ 1041 CRO_ChargeReady "�����Ƿ�׼����";
CM_ SG_ 1041 BMS_BattChrgNeeded "�����Ҫ����־λ";
CM_ SG_ 1041 BMS_DcDisChgStatus "ֱ������ŵ�״̬";
CM_ SG_ 1041 BMS_CC1_Resistance "CC1����";
CM_ SG_ 1041 BMS_CC2_Resistance "CC2����";
CM_ SG_ 1041 BMS_DC_DisChrgCurr "ֱ���ŵ����";
CM_ SG_ 1041 BMS_DC_DisChrgPower "ֱ���ŵ繦��";
CM_ SG_ 1041 BMS_DC_DisChrgEngy "ֱ���ŵ�����";
CM_ SG_ 1041 BMS_DC_DisChrgRemainTi "ֱ������ŵ�ʣ��ʱ��";
CM_ SG_ 1041 BMS_DC_DisChrgVolt "ֱ���ŵ��ѹ";
CM_ SG_ 1041 BMS_QCCDetdtVoltage "���̵������ɼ���ѹ";
CM_ SG_ 1041 BMS_InsulationNeg "��Ե���ɼ�������Ե���裨���귨��Rn";
CM_ SG_ 281 BMS_ColdbootPwr "����������";
CM_ SG_ 281 BMS_StateOfChargeCorrect "��ʵSOC";
CM_ SG_ 281 BMS_BusVoltage "link voltage";
CM_ SG_ 1275 BMSH_PowerChangeSign "�����л���־";
CM_ SG_ 1275 BMSH_PackInstantOutPower "ʵʱ�������";
CM_ SG_ 1275 BMSH_PackInstantRecoveryPower "ʵʱ���빦�ʣ���������磩";
CM_ SG_ 1275 BMS_SOCCalAlarm "��ʱ��δУ׼SOC��ʾ
0x0: Normal ����������ʾ
0x1: Alarm ��ʱ��SOCδУ׼��ʾ
0x2~0x3: Reserved Ԥ��";
CM_ SG_ 1275 BMS_PosInsulationSt "�����Եؾ�Ե״̬
0x0: Unknowδ֪
0x1: Normal����
0x2: Fault����
0x3: HWFault����·����";
CM_ SG_ 1275 BMS_NegInsulationSt "�����Եؾ�Ե״̬
0x0: Unknowδ֪
0x1: Normal����
0x2: Fault����
0x3: HWFault����·����";
CM_ SG_ 1275 BMSH_NegInsulationResis "���Եؾ�Ե��ֵ";
CM_ SG_ 1275 BMSH_PosInsulationResis "���Եؾ�Ե��ֵ";
CM_ SG_ 1275 CML_OutputVoltageMax "��������ѹ";
CM_ SG_ 1275 CML_OutputVoltageMin "��������ѹ";
CM_ SG_ 1275 CML_OutputCurentMax "����������";
CM_ SG_ 1275 CML_OutputCurentMin "����������";
CM_ SG_ 1275 BCL_VoltageRequire "��ѹ����V��";
CM_ SG_ 1275 BCL_CurrentRequire "��������A��";
CM_ SG_ 1275 CCS_OutputVoltage "׮�������ѹ��V��";
CM_ SG_ 1275 CCS_OutputCurent "׮�����������A��";
CM_ SG_ 1127 CDU_1_CRC1 "Profile1A:E2E CRC (SAE J1850 CRC-8) for 8 Bytes
DataID:No ASIL requirements.Not configure
CRC Reserved.";
CM_ SG_ 1127 CDU_1_RollgCntr1 "Profile1A:E2E Rolling message counter(the maximum value of Alive counter is 14)";
CM_ SG_ 1127 CDU_1_Resd1 "Profile1A:E2E Reserved";
CM_ SG_ 1127 DCDC_HvVolt "DCDC input voltage";
CM_ SG_ 1127 DCDC_FaultCode "Fault Code";
CM_ SG_ 1127 CDU_1_CRC2 "Profile1A:E2E CRC (SAE J1850 CRC-8) for 8 Bytes
DataID:0x0025";
CM_ SG_ 1127 CDU_1_RollgCntr2 "Profile1A:E2E Rolling message counter(the maximum value of Alive counter is 14)";
CM_ SG_ 1127 CDU_1_Resd2 "Profile1A:E2E Reserved";
CM_ SG_ 1127 DCDC_LvSideCurr "DCDC output current";
CM_ SG_ 1127 DCDC_LvSideVolt "DCDC output voltage";
CM_ SG_ 1127 DCDC_FaultLevelSts "DCDC fault states

��;����0x4:Lever4 fault����ֵ���ɷݲ����ø�����ֵ";
CM_ SG_ 1127 DCDC_EnableSts "DCDC enable states feedback";
CM_ SG_ 1127 DCDC_OverTemp "DCDC over temperature";
CM_ SG_ 1127 DCDC_LvSideCurrMax "DCDC output current";
CM_ SG_ 1182 CDU_2_CRC1 "Profile1A:E2E CRC (SAE J1850 CRC-8) for 8 Bytes
DataID:0x0026";
CM_ SG_ 1182 CDU_2_RollgCntr1 "Profile1A:E2E Rolling message counter(the maximum value of Alive counter is 14)";
CM_ SG_ 1182 CDU_2_Resd1 "Profile1A:E2E Reserved";
CM_ SG_ 1182 OBC_ChgCurr "output current";
CM_ SG_ 1182 OBC_ChgVolt "output voltage";
CM_ SG_ 1182 OBC_FaultCode "OBC fault matrix";
CM_ SG_ 1182 CDU_2_CRC2 "Profile1A:E2E CRC (SAE J1850 CRC-8) for 8 Bytes
DataID:No ASIL requirements.Not configure
CRC Reserved.";
CM_ SG_ 1182 CDU_2_RollgCntr2 "Profile1A:E2E Rolling message counter(the maximum value of Alive counter is 14)";
CM_ SG_ 1182 CDU_2_Resd2 "Profile1A:E2E Reserved";
CM_ SG_ 1182 OBC_CP_DutyCycleValue "CP pwm";
CM_ SG_ 1182 CDU_Coolanttemp "CDU Coolant temperature";
CM_ SG_ 1182 OBC_ChgInterfaceTemp "OBC Charge Interface Temperature";
CM_ SG_ 1182 OBC_CPMaxVolt "charger CP MaxVolt value";
CM_ SG_ 1182 CDU_2_CRC3 "Profile1A:E2E CRC (SAE J1850 CRC-8) for 8 Bytes
DataID:No ASIL requirements.Not configure
CRC Reserved.";
CM_ SG_ 1182 CDU_2_RollgCntr3 "Profile1A:E2E Rolling message counter(the maximum value of Alive counter is 14)";
CM_ SG_ 1182 CDU_2_Resd3 "Profile1A:E2E Reserved";

BA_DEF_ BO_  "NmMessage" ENUM "No","Yes";
BA_DEF_ BO_  "DiagState" ENUM  "No","Yes";
BA_DEF_ BO_  "GenMsgSendType" ENUM  "Cyclic","Event","IfActive","CE","CA","NoMsgSendType";
BA_DEF_ BO_  "GenMsgCycleTime" INT 0 0;
BA_DEF_ SG_  "GenSigSendType" ENUM  "Cyclic","OnChange","OnWrite","IfActive","OnChangeWithRepetition","OnWriteWithRepetition","IfActiveWithRepetition","NoSigSendType","OnChangeAndIfActive","OnChangeAndIfActiveWithRepetition","CA","CE","Event";
BA_DEF_ SG_  "GenSigStartValue" INT 0 0;
BA_DEF_ SG_  "GenSigInactiveValue" INT 0 0;
BA_DEF_ BO_  "GenMsgCycleTimeFast" INT 0 0;
BA_DEF_ BO_  "GenMsgNrOfRepetition" INT 0 0;
BA_DEF_ BO_  "GenMsgDelayTime" INT 0 0;
BA_DEF_  "DBName" STRING ;
BA_DEF_ BO_  "CANFD_BRS" ENUM  "0","1";
BA_DEF_ BO_  "VFrameFormat" ENUM  "StandardCAN","ExtendedCAN","reserved","reserved","reserved","reserved","reserved","reserved","reserved","reserved","reserved","reserved","reserved","reserved","StandardCAN_FD","ExtendedCAN_FD";
BA_DEF_  "NmMessageCount" INT 0 255;
BA_DEF_ BO_  "GenMsgILSupport" ENUM  "No","Yes";
BA_DEF_  "NmBaseAddress" HEX 1024 1087;
BA_DEF_  "BusType" STRING ;
BA_DEF_ SG_ "GenSigASIL" ENUM "QM","A","B","C","D","";
BA_DEF_DEF_  "NmMessage" "No";
BA_DEF_DEF_  "DiagState" "No";
BA_DEF_DEF_  "GenMsgSendType" "Cyclic";
BA_DEF_DEF_  "GenMsgCycleTime" 0;
BA_DEF_DEF_  "GenSigSendType" "Cyclic";
BA_DEF_DEF_  "GenSigStartValue" 0;
BA_DEF_DEF_  "GenSigInactiveValue" 0;
BA_DEF_DEF_  "GenMsgCycleTimeFast" 0;
BA_DEF_DEF_  "GenMsgNrOfRepetition" 0;
BA_DEF_DEF_  "GenMsgDelayTime" 0;
BA_DEF_DEF_  "DBName" "";
BA_DEF_DEF_  "CANFD_BRS" "1";
BA_DEF_DEF_  "VFrameFormat" "StandardCAN_FD";
BA_DEF_DEF_  "NmMessageCount" 128;
BA_DEF_DEF_  "GenMsgILSupport" "No";
BA_DEF_DEF_  "NmBaseAddress" 1024;
BA_DEF_DEF_  "BusType" "CAN FD";
BA_DEF_DEF_ "GenSigASIL" "QM";
BA_ "DBName" "EEA4.x_FLZCU_EP_V4.10_20250522";
BA_ "GenMsgILSupport" BO_ 33 1;
BA_ "GenMsgSendType" BO_ 33 3;
BA_ "GenMsgCycleTime" BO_ 33 10;
BA_ "GenMsgCycleTimeFast" BO_ 33 10;
BA_ "GenMsgNrOfRepetition" BO_ 33 6;
BA_ "GenMsgDelayTime" BO_ 33 5;
BA_ "GenSigASIL"  SG_ 33 ACU_3_CRC1 5;
BA_ "GenSigASIL"  SG_ 33 ACU_3_RollgCntr1 5;
BA_ "GenSigASIL"  SG_ 33 ACU_3_Resd1 5;
BA_ "GenSigASIL"  SG_ 33 ACU_3_LongitudinalAcceleration 2;
BA_ "GenSigStartValue" SG_ 33 ACU_3_LongitudinalAccelerationVD 3;
BA_ "GenSigASIL"  SG_ 33 ACU_3_LongitudinalAccelerationVD 2;
BA_ "GenSigSendType" SG_ 33 ACU_3_CrashOutputSts 5;
BA_ "GenSigASIL"  SG_ 33 ACU_3_CrashOutputSts 2;
BA_ "GenMsgILSupport" BO_ 1299 1;
BA_ "GenMsgCycleTime" BO_ 1299 500;
BA_ "GenSigASIL"  SG_ 1299 BMS_1_G_CRC 5;
BA_ "GenSigASIL"  SG_ 1299 BMS_1_G_RollgCntr 5;
BA_ "GenSigASIL"  SG_ 1299 BMS_1_G_Resd 5;
BA_ "GenSigStartValue" SG_ 1299 BMS_PackVoltageDis 65535;
BA_ "GenSigASIL"  SG_ 1299 BMS_PackVoltageDis 5;
BA_ "GenSigStartValue" SG_ 1299 BMS_PackCurrentDis 65535;
BA_ "GenSigASIL"  SG_ 1299 BMS_PackCurrentDis 5;
BA_ "GenSigASIL"  SG_ 1299 BMS_TBOXErrorCode 5;
BA_ "GenMsgILSupport" BO_ 1291 1;
BA_ "GenMsgCycleTime" BO_ 1291 500;
BA_ "GenSigASIL"  SG_ 1291 BMS_2_G_CRC 5;
BA_ "GenSigASIL"  SG_ 1291 BMS_2_G_RollgCntr 5;
BA_ "GenSigASIL"  SG_ 1291 BMS_2_G_Resd 5;
BA_ "GenSigASIL"  SG_ 1291 BMS_TBOXInsulation_R 5;
BA_ "GenSigASIL"  SG_ 1291 BMS_TBOXErrorNumber 5;
BA_ "GenSigStartValue" SG_ 1291 BMS_TBOXHvBattMaxT 255;
BA_ "GenSigASIL"  SG_ 1291 BMS_TBOXHvBattMaxT 5;
BA_ "GenSigStartValue" SG_ 1291 BMS_TBOXHvBattMinT 255;
BA_ "GenSigASIL"  SG_ 1291 BMS_TBOXHvBattMinT 5;
BA_ "GenSigASIL"  SG_ 1291 BMS_SOCLight 2;
BA_ "GenMsgILSupport" BO_ 1295 1;
BA_ "GenMsgCycleTime" BO_ 1295 500;
BA_ "GenSigASIL"  SG_ 1295 BMS_3_G_CRC 5;
BA_ "GenSigASIL"  SG_ 1295 BMS_3_G_RollgCntr 5;
BA_ "GenSigASIL"  SG_ 1295 BMS_3_G_Resd 5;
BA_ "GenSigASIL"  SG_ 1295 BMS_RemainChg_Time 5;
BA_ "GenSigASIL"  SG_ 1295 BMS_HvBattErrSt 5;
BA_ "GenSigASIL"  SG_ 1295 BMS_OverTemp_LightSts 5;
BA_ "GenSigASIL"  SG_ 1295 BMS_ChgWireConnect_LightSts 5;
BA_ "GenSigASIL"  SG_ 1295 BMS_Chg_LightSts 5;
BA_ "GenSigASIL"  SG_ 1295 BMS_HVstsDis 5;
BA_ "GenSigASIL"  SG_ 1295 BMS_ThermalRunawayDis 3;
BA_ "GenSigASIL"  SG_ 1295 BMS_TBOXIsolationFault 2;
BA_ "GenSigASIL"  SG_ 1295 BMS_TBOXHVIL1Fault 2;
BA_ "GenSigASIL"  SG_ 1295 BMS_PreWarmDis 5;
BA_ "GenMsgILSupport" BO_ 258 1;
BA_ "GenMsgCycleTime" BO_ 258 10;
BA_ "GenSigASIL"  SG_ 258 BMS_1_CRC1 5;
BA_ "GenSigASIL"  SG_ 258 BMS_1_RollgCntr1 5;
BA_ "GenSigASIL"  SG_ 258 BMS_1_Resd1 5;
BA_ "GenSigStartValue" SG_ 258 BMS_PackVoltage 65535;
BA_ "GenSigASIL"  SG_ 258 BMS_PackVoltage 3;
BA_ "GenSigStartValue" SG_ 258 BMS_PackCurrent 65535;
BA_ "GenSigASIL"  SG_ 258 BMS_PackCurrent 3;
BA_ "GenSigASIL"  SG_ 258 BMS_HvBattSts 1;
BA_ "GenSigASIL"  SG_ 258 BMS_SysSelfCheck 5;
BA_ "GenSigASIL"  SG_ 258 BMS_HVBattThermRunaway 3;
BA_ "GenSigASIL"  SG_ 258 BMS_1_CRC2 5;
BA_ "GenSigASIL"  SG_ 258 BMS_1_RollgCntr2 5;
BA_ "GenSigASIL"  SG_ 258 BMS_1_Resd2 5;
BA_ "GenSigASIL"  SG_ 258 BMS_DcDisChgCurrReq 5;
BA_ "GenSigASIL"  SG_ 258 BMS_C2Target_Buck_Voltage 5;
BA_ "GenSigASIL"  SG_ 258 BMS_DisChrgDcCnctrDetd 5;
BA_ "GenSigStartValue" SG_ 258 BMS_InfraDcUActDc 16382;
BA_ "GenSigASIL"  SG_ 258 BMS_InfraDcUActDc 5;
BA_ "GenSigASIL"  SG_ 258 BMS_1_CRC3 5;
BA_ "GenSigASIL"  SG_ 258 BMS_1_RollgCntr3 5;
BA_ "GenSigASIL"  SG_ 258 BMS_1_Resd3 5;
BA_ "GenSigStartValue" SG_ 258 BMS_InfraDcIActDc 16382;
BA_ "GenSigASIL"  SG_ 258 BMS_InfraDcIActDc 5;
BA_ "GenSigStartValue" SG_ 258 BMS_HvBattDynChrgnILim 16382;
BA_ "GenSigASIL"  SG_ 258 BMS_HvBattDynChrgnILim 3;
BA_ "GenSigStartValue" SG_ 258 BMS_HvBattUChrgnLim 16382;
BA_ "GenSigASIL"  SG_ 258 BMS_HvBattUChrgnLim 3;
BA_ "GenSigASIL"  SG_ 258 BMS_1_CRC4 5;
BA_ "GenSigASIL"  SG_ 258 BMS_1_RollgCntr4 5;
BA_ "GenSigASIL"  SG_ 258 BMS_1_Resd4 5;
BA_ "GenSigStartValue" SG_ 258 BMS_ChrgDcIAvl 16382;
BA_ "GenSigASIL"  SG_ 258 BMS_ChrgDcIAvl 5;
BA_ "GenSigASIL"  SG_ 258 BMS_DChrgAPlusSt 5;
BA_ "GenSigASIL"  SG_ 258 BMS_Insulation_R 2;
BA_ "GenSigASIL"  SG_ 258 BMS_ChrgDcCnctrDetd 2;
BA_ "GenSigASIL"  SG_ 258 BMS_DCChgMode 5;
BA_ "GenSigASIL"  SG_ 258 BMS_ChrgDcChrgnFltStopReas 5;
BA_ "GenSigASIL"  SG_ 258 BMS_1_CRC5 5;
BA_ "GenSigASIL"  SG_ 258 BMS_1_RollgCntr5 5;
BA_ "GenSigASIL"  SG_ 258 BMS_1_Resd5 5;
BA_ "GenSigStartValue" SG_ 258 BMS_ChgRemTime 2047;
BA_ "GenSigASIL"  SG_ 258 BMS_ChgRemTime 5;
BA_ "GenSigASIL"  SG_ 258 BMS_ChargeRequest_Mode 1;
BA_ "GenSigStartValue" SG_ 258 BMS_StateOfChargeDis 255;
BA_ "GenSigASIL"  SG_ 258 BMS_StateOfChargeDis 1;
BA_ "GenSigStartValue" SG_ 258 BMS_StateOfEnergy 65535;
BA_ "GenSigASIL"  SG_ 258 BMS_StateOfEnergy 5;
BA_ "GenSigASIL"  SG_ 258 BMS_1_CRC6 5;
BA_ "GenSigASIL"  SG_ 258 BMS_1_RollgCntr6 5;
BA_ "GenSigASIL"  SG_ 258 BMS_1_Resd6 5;
BA_ "GenSigASIL"  SG_ 258 BMS_StateOfHealth 5;
BA_ "GenSigASIL"  SG_ 258 BMS_BlanceState 5;
BA_ "GenSigASIL"  SG_ 258 BMS_IsolationFault 2;
BA_ "GenSigASIL"  SG_ 258 BMS_HVILFault_DC 2;
BA_ "GenSigASIL"  SG_ 258 BMS_HVILFault_FMCU 2;
BA_ "GenSigASIL"  SG_ 258 BMS_HVILFault_RMCU 2;
BA_ "GenSigStartValue" SG_ 258 BMS_SOCDis 16383;
BA_ "GenSigASIL"  SG_ 258 BMS_SOCDis 5;
BA_ "GenSigStartValue" SG_ 258 BMS_InfraDcIActDcMin 16383;
BA_ "GenSigASIL"  SG_ 258 BMS_InfraDcIActDcMin 5;
BA_ "GenMsgILSupport" BO_ 520 1;
BA_ "GenMsgCycleTime" BO_ 520 20;
BA_ "GenSigASIL"  SG_ 520 BMS_2_CRC1 5;
BA_ "GenSigASIL"  SG_ 520 BMS_2_RollgCntr1 5;
BA_ "GenSigASIL"  SG_ 520 BMS_2_Resd1 5;
BA_ "GenSigASIL"  SG_ 520 BMS_C2Target_Chg_Voltage 2;
BA_ "GenSigASIL"  SG_ 520 BMS_CHGstation_MAXPwr 5;
BA_ "GenSigASIL"  SG_ 520 BMS_2_CRC2 5;
BA_ "GenSigASIL"  SG_ 520 BMS_2_RollgCntr2 5;
BA_ "GenSigASIL"  SG_ 520 BMS_2_Resd2 5;
BA_ "GenSigASIL"  SG_ 520 BMS_NV_relay_Sts 2;
BA_ "GenSigASIL"  SG_ 520 BMS_PV_relay_Sts 2;
BA_ "GenSigASIL"  SG_ 520 BMS_QCP_relay_Sts 2;
BA_ "GenSigASIL"  SG_ 520 BMS_QCN_relay_Sts 2;
BA_ "GenSigASIL"  SG_ 520 BMS_HvBattThermReqLevel 5;
BA_ "GenSigASIL"  SG_ 520 BMS_Prechage_relay_Sts 2;
BA_ "GenSigASIL"  SG_ 520 BMS_HvBattThermReqMode 5;
BA_ "GenSigStartValue" SG_ 520 BMS_ClntTHvBattIn 254;
BA_ "GenSigASIL"  SG_ 520 BMS_ClntTHvBattIn 5;
BA_ "GenSigStartValue" SG_ 520 BMS_ClntTHvBattOut 254;
BA_ "GenSigASIL"  SG_ 520 BMS_ClntTHvBattOut 5;
BA_ "GenSigStartValue" SG_ 520 BMS_HvBattClntInTReq 126;
BA_ "GenSigASIL"  SG_ 520 BMS_HvBattClntInTReq 5;
BA_ "GenSigASIL"  SG_ 520 BMS_2_CRC3 5;
BA_ "GenSigASIL"  SG_ 520 BMS_2_RollgCntr3 5;
BA_ "GenSigASIL"  SG_ 520 BMS_2_Resd3 5;
BA_ "GenSigStartValue" SG_ 520 BMS_HvBattClntFlowReq 126;
BA_ "GenSigASIL"  SG_ 520 BMS_HvBattClntFlowReq 5;
BA_ "GenSigStartValue" SG_ 520 BMS_HvBattAvgT 254;
BA_ "GenSigASIL"  SG_ 520 BMS_HvBattAvgT 5;
BA_ "GenSigStartValue" SG_ 520 BMS_HvBattMaxT 255;
BA_ "GenSigASIL"  SG_ 520 BMS_HvBattMaxT 3;
BA_ "GenSigStartValue" SG_ 520 BMS_HvBattMinT 255;
BA_ "GenSigASIL"  SG_ 520 BMS_HvBattMinT 3;
BA_ "GenSigStartValue" SG_ 520 BMS_HvBattTdiff 126;
BA_ "GenSigASIL"  SG_ 520 BMS_HvBattTdiff 5;
BA_ "GenSigASIL"  SG_ 520 BMS_2_CRC4 5;
BA_ "GenSigASIL"  SG_ 520 BMS_2_RollgCntr4 5;
BA_ "GenSigASIL"  SG_ 520 BMS_2_Resd4 5;
BA_ "GenSigStartValue" SG_ 520 BMS_OutPosU 16382;
BA_ "GenSigASIL"  SG_ 520 BMS_OutPosU 2;
BA_ "GenSigStartValue" SG_ 520 BMS_OutNegU 16382;
BA_ "GenSigASIL"  SG_ 520 BMS_OutNegU 2;
BA_ "GenSigASIL"  SG_ 520 BMS_ChrgTrgtSOC 5;
BA_ "GenSigASIL"  SG_ 520 BMS_2_CRC5 5;
BA_ "GenSigASIL"  SG_ 520 BMS_2_RollgCntr5 5;
BA_ "GenSigASIL"  SG_ 520 BMS_2_Resd5 5;
BA_ "GenSigStartValue" SG_ 520 BMS_outQCPosU 16382;
BA_ "GenSigASIL"  SG_ 520 BMS_outQCPosU 2;
BA_ "GenSigStartValue" SG_ 520 BMS_outQCNegU 16382;
BA_ "GenSigASIL"  SG_ 520 BMS_outQCNegU 2;
BA_ "GenSigASIL"  SG_ 520 BMS_Middlesplit_relay_Sts 2;
BA_ "GenSigASIL"  SG_ 520 BMS_DCChrgSts 5;
BA_ "GenSigASIL"  SG_ 520 BMS_ACChrgSts 5;
BA_ "GenSigStartValue" SG_ 520 BMS_BattCurrtSnsr1 32766;
BA_ "GenSigASIL"  SG_ 520 BMS_BattCurrtSnsr1 5;
BA_ "GenSigStartValue" SG_ 520 BMS_BattCurrtSnsr2 32766;
BA_ "GenSigASIL"  SG_ 520 BMS_BattCurrtSnsr2 5;
BA_ "GenSigStartValue" SG_ 520 BMS_SOHCapFade 254;
BA_ "GenSigASIL"  SG_ 520 BMS_SOHCapFade 5;
BA_ "GenSigStartValue" SG_ 520 BMS_SOHResInc 254;
BA_ "GenSigASIL"  SG_ 520 BMS_SOHResInc 5;
BA_ "GenMsgILSupport" BO_ 523 1;
BA_ "GenMsgCycleTime" BO_ 523 20;
BA_ "GenSigASIL"  SG_ 523 BMS_3_CRC1 5;
BA_ "GenSigASIL"  SG_ 523 BMS_3_RollgCntr1 5;
BA_ "GenSigASIL"  SG_ 523 BMS_3_Resd1 5;
BA_ "GenSigStartValue" SG_ 523 BMS_HvBattPMaxReChrgLim 16382;
BA_ "GenSigASIL"  SG_ 523 BMS_HvBattPMaxReChrgLim 2;
BA_ "GenSigASIL"  SG_ 523 BMS_3_CRC2 5;
BA_ "GenSigASIL"  SG_ 523 BMS_3_RollgCntr2 5;
BA_ "GenSigASIL"  SG_ 523 BMS_3_Resd2 5;
BA_ "GenSigStartValue" SG_ 523 BMS_HvBattIMaxReChrgLim 2047;
BA_ "GenSigASIL"  SG_ 523 BMS_HvBattIMaxReChrgLim 2;
BA_ "GenSigStartValue" SG_ 523 BMS_HvBattPMaxDchaLim 16382;
BA_ "GenSigASIL"  SG_ 523 BMS_HvBattPMaxDchaLim 2;
BA_ "GenSigASIL"  SG_ 523 BMS_3_CRC3 5;
BA_ "GenSigASIL"  SG_ 523 BMS_3_RollgCntr3 5;
BA_ "GenSigASIL"  SG_ 523 BMS_3_Resd3 5;
BA_ "GenSigStartValue" SG_ 523 BMS_HvBattIMaxDchaLim 2047;
BA_ "GenSigASIL"  SG_ 523 BMS_HvBattIMaxDchaLim 2;
BA_ "GenSigASIL"  SG_ 523 BMS_3_CRC4 5;
BA_ "GenSigASIL"  SG_ 523 BMS_3_RollgCntr4 5;
BA_ "GenSigASIL"  SG_ 523 BMS_3_Resd4 5;
BA_ "GenSigASIL"  SG_ 523 BMS_3_CRC5 5;
BA_ "GenSigASIL"  SG_ 523 BMS_3_RollgCntr5 5;
BA_ "GenSigASIL"  SG_ 523 BMS_3_Resd5 5;
BA_ "GenSigASIL"  SG_ 523 BMS_KL30Volt 2;
BA_ "GenSigASIL"  SG_ 523 BMS_kL87Volt 2;
BA_ "GenSigStartValue" SG_ 523 BMS_HvBattUDchaLim 16382;
BA_ "GenSigASIL"  SG_ 523 BMS_HvBattUDchaLim 5;
BA_ "GenSigASIL"  SG_ 523 BMS_3_CRC6 5;
BA_ "GenSigASIL"  SG_ 523 BMS_3_RollgCntr6 5;
BA_ "GenSigASIL"  SG_ 523 BMS_3_Resd6 5;
BA_ "GenSigASIL"  SG_ 523 BMSH_MaxChgPwrPeak 5;
BA_ "GenSigASIL"  SG_ 523 BMSH_MaxDchgPwrPeak 5;
BA_ "GenSigStartValue" SG_ 523 BMS_PackSOCAct 1022;
BA_ "GenSigASIL"  SG_ 523 BMS_PackSOCAct 5;
BA_ "GenSigStartValue" SG_ 523 BMS_PackSOCCalc 1022;
BA_ "GenSigASIL"  SG_ 523 BMS_PackSOCCalc 5;
BA_ "GenMsgILSupport" BO_ 1055 1;
BA_ "GenMsgCycleTime" BO_ 1055 100;
BA_ "GenSigASIL"  SG_ 1055 BMS_4_CRC1 5;
BA_ "GenSigASIL"  SG_ 1055 BMS_4_RollgCntr1 5;
BA_ "GenSigASIL"  SG_ 1055 BMS_4_Resd1 5;
BA_ "GenSigASIL"  SG_ 1055 BMS_ErrorNumber 5;
BA_ "GenSigASIL"  SG_ 1055 BMS_ErrorCode 5;
BA_ "GenSigASIL"  SG_ 1055 BMS_4_CRC2 5;
BA_ "GenSigASIL"  SG_ 1055 BMS_4_RollgCntr2 5;
BA_ "GenSigASIL"  SG_ 1055 BMS_4_Resd2 5;
BA_ "GenSigASIL"  SG_ 1055 BMSH_MILReq 2;
BA_ "GenSigASIL"  SG_ 1055 BMS_ErrorLevel 2;
BA_ "GenSigASIL"  SG_ 1055 BMS_HvBattUnderTemperature 5;
BA_ "GenSigASIL"  SG_ 1055 BMS_ThermRunCode 5;
BA_ "GenSigASIL"  SG_ 1055 BMS_DChrgEndCode 5;
BA_ "GenSigASIL"  SG_ 1055 BMS_PwrDerateFlg 5;
BA_ "GenSigASIL"  SG_ 1055 BMS_CHGstation_LowPWRFlg 5;
BA_ "GenSigASIL"  SG_ 1055 BMS_bHint4FullChrgFlg 5;
BA_ "GenSigStartValue" SG_ 1055 BMS_StateOfChargeDis 255;
BA_ "GenSigASIL"  SG_ 1055 BMS_StateOfChargeDis 1;
BA_ "GenSigASIL"  SG_ 1055 BMS_FastChargingFlg 5;
BA_ "GenSigASIL"  SG_ 1055 BMS_LowCellVltChrgFlg 5;
BA_ "GenSigASIL"  SG_ 1055 BMS_EngineStartReq 5;
BA_ "GenMsgILSupport" BO_ 1525 1;
BA_ "GenMsgCycleTime" BO_ 1525 1000;
BA_ "GenSigASIL"  SG_ 1525 BMS_SoftWareVersion 5;
BA_ "GenMsgILSupport" BO_ 811 1;
BA_ "GenMsgCycleTime" BO_ 811 50;
BA_ "GenSigASIL"  SG_ 811 BMS_6_CRC1 5;
BA_ "GenSigASIL"  SG_ 811 BMS_6_RollgCntr1 5;
BA_ "GenSigASIL"  SG_ 811 BMS_6_Resd1 5;
BA_ "GenSigStartValue" SG_ 811 BMS_HvBattCellVoltMax_Num 255;
BA_ "GenSigASIL"  SG_ 811 BMS_HvBattCellVoltMax_Num 5;
BA_ "GenSigStartValue" SG_ 811 BMS_HvBattCellVoltMax 65534;
BA_ "GenSigASIL"  SG_ 811 BMS_HvBattCellVoltMax 3;
BA_ "GenSigStartValue" SG_ 811 BMS_HvBattCellVoltMin_Num 255;
BA_ "GenSigASIL"  SG_ 811 BMS_HvBattCellVoltMin_Num 5;
BA_ "GenSigStartValue" SG_ 811 BMS_HvBattCellVoltMin 65534;
BA_ "GenSigASIL"  SG_ 811 BMS_HvBattCellVoltMin 3;
BA_ "GenSigASIL"  SG_ 811 BMS_6_CRC2 5;
BA_ "GenSigASIL"  SG_ 811 BMS_6_RollgCntr2 5;
BA_ "GenSigASIL"  SG_ 811 BMS_6_Resd2 5;
BA_ "GenSigASIL"  SG_ 811 BMS_Chg_Sts 5;
BA_ "GenSigStartValue" SG_ 811 BMS_PackSOCNotAvrlble 1022;
BA_ "GenSigASIL"  SG_ 811 BMS_PackSOCNotAvrlble 5;
BA_ "GenSigStartValue" SG_ 811 BMS_DchaPwrContnsMax 16382;
BA_ "GenSigASIL"  SG_ 811 BMS_DchaPwrContnsMax 5;
BA_ "GenSigStartValue" SG_ 811 BMS_ChrgPwrContnsMax 16382;
BA_ "GenSigASIL"  SG_ 811 BMS_ChrgPwrContnsMax 5;
BA_ "GenSigASIL"  SG_ 811 BMS_APlusWakeupSt 5;
BA_ "GenSigASIL"  SG_ 811 BMS_KL15WakeupSt 5;
BA_ "GenSigASIL"  SG_ 811 BMSH_CHGPrechargeRelaySts 5;
BA_ "GenMsgILSupport" BO_ 1290 1;
BA_ "GenMsgCycleTime" BO_ 1290 500;
BA_ "GenSigASIL"  SG_ 1290 BMS_8_CRC1 5;
BA_ "GenSigASIL"  SG_ 1290 BMS_8_RollgCntr1 5;
BA_ "GenSigASIL"  SG_ 1290 BMS_8_Resd1 5;
BA_ "GenSigASIL"  SG_ 1290 BMS_HvBattCellOverU 3;
BA_ "GenSigASIL"  SG_ 1290 BMS_HvBattCellUnderU 3;
BA_ "GenSigASIL"  SG_ 1290 BMS_HvBattUnderU 3;
BA_ "GenSigASIL"  SG_ 1290 BMS_HvBattDischargeOverCurrent 3;
BA_ "GenSigASIL"  SG_ 1290 BMS_HvBattChargeOverCurrent 3;
BA_ "GenSigASIL"  SG_ 1290 BMS_HvBattOverU 3;
BA_ "GenSigASIL"  SG_ 1290 BMS_HvBattMismatching 5;
BA_ "GenSigASIL"  SG_ 1290 BMS_HvBattSocJump 5;
BA_ "GenSigASIL"  SG_ 1290 BMS_HvBattCellUUnif 5;
BA_ "GenSigASIL"  SG_ 1290 BMS_HvBattLowSoc 5;
BA_ "GenSigASIL"  SG_ 1290 BMS_HvBattOverSoc 5;
BA_ "GenSigASIL"  SG_ 1290 BMS_HvBattTempUniformity 5;
BA_ "GenSigASIL"  SG_ 1290 BMS_BattInterCANErr 5;
BA_ "GenSigASIL"  SG_ 1290 BMS_HvBattOverCharging 3;
BA_ "GenSigASIL"  SG_ 1290 BMS_HvBattOverTemperature 3;
BA_ "GenSigStartValue" SG_ 1290 BMS_PrimaryCurrtSnsrTemp 254;
BA_ "GenSigASIL"  SG_ 1290 BMS_PrimaryCurrtSnsrTemp 5;
BA_ "GenSigStartValue" SG_ 1290 BMS_EquTempMax 254;
BA_ "GenSigASIL"  SG_ 1290 BMS_EquTempMax 5;
BA_ "GenMsgILSupport" BO_ 1531 1;
BA_ "GenMsgCycleTime" BO_ 1531 1000;
BA_ "GenSigASIL"  SG_ 1531 BMS_9_CRC1 5;
BA_ "GenSigASIL"  SG_ 1531 BMS_9_RollgCntr1 5;
BA_ "GenSigASIL"  SG_ 1531 BMS_9_Resd1 5;
BA_ "GenSigStartValue" SG_ 1531 BMS_HvBattSoeActDisChaCyc 65535;
BA_ "GenSigASIL"  SG_ 1531 BMS_HvBattSoeActDisChaCyc 5;
BA_ "GenSigStartValue" SG_ 1531 BMS_HvBattSoeActReChaCyc 65535;
BA_ "GenSigASIL"  SG_ 1531 BMS_HvBattSoeActReChaCyc 5;
BA_ "GenSigStartValue" SG_ 1531 BMS_HvBattRatedEnergy 16382;
BA_ "GenSigASIL"  SG_ 1531 BMS_HvBattRatedEnergy 5;
BA_ "GenSigStartValue" SG_ 1531 BMS_HvBattRatedU 16382;
BA_ "GenSigASIL"  SG_ 1531 BMS_HvBattRatedU 5;
BA_ "GenSigStartValue" SG_ 1531 BMS_HvBattTypeCode 255;
BA_ "GenSigASIL"  SG_ 1531 BMS_HvBattTypeCode 5;
BA_ "GenSigASIL"  SG_ 1531 BMS_HvBattManufcCode 5;
BA_ "GenSigStartValue" SG_ 1531 BMS_HvBattTempSensorTotalNum 65535;
BA_ "GenSigASIL"  SG_ 1531 BMS_HvBattTempSensorTotalNum 5;
BA_ "GenSigStartValue" SG_ 1531 BMS_HvBattTempSensorTempMaxNum 255;
BA_ "GenSigASIL"  SG_ 1531 BMS_HvBattTempSensorTempMaxNum 5;
BA_ "GenSigStartValue" SG_ 1531 BMS_HvBattTempSensorTempMinNum 255;
BA_ "GenSigASIL"  SG_ 1531 BMS_HvBattTempSensorTempMinNum 5;
BA_ "GenSigStartValue" SG_ 1531 BMS_HvBattTempMaxNum 255;
BA_ "GenSigASIL"  SG_ 1531 BMS_HvBattTempMaxNum 5;
BA_ "GenSigStartValue" SG_ 1531 BMS_HvBattTempMinNum 255;
BA_ "GenSigASIL"  SG_ 1531 BMS_HvBattTempMinNum 5;
BA_ "GenSigStartValue" SG_ 1531 BMS_BattCellTotalNum 65535;
BA_ "GenSigASIL"  SG_ 1531 BMS_BattCellTotalNum 5;
BA_ "GenSigStartValue" SG_ 1531 BMS_HvBattVoltMaxNum 255;
BA_ "GenSigASIL"  SG_ 1531 BMS_HvBattVoltMaxNum 5;
BA_ "GenSigStartValue" SG_ 1531 BMS_HvBattVoltMinNum 255;
BA_ "GenSigASIL"  SG_ 1531 BMS_HvBattVoltMinNum 5;
BA_ "GenSigStartValue" SG_ 1531 BMS_ActualSOCMin 4095;
BA_ "GenSigASIL"  SG_ 1531 BMS_ActualSOCMin 5;
BA_ "GenSigStartValue" SG_ 1531 BMS_ActualSOCMax 4095;
BA_ "GenSigASIL"  SG_ 1531 BMS_ActualSOCMax 5;
BA_ "GenMsgILSupport" BO_ 1535 1;
BA_ "GenMsgCycleTime" BO_ 1535 1000;
BA_ "GenSigStartValue" SG_ 1535 BMS_HvBattTempSensorTemp_1T 255;
BA_ "GenSigASIL"  SG_ 1535 BMS_HvBattTempSensorTemp_1T 5;
BA_ "GenSigStartValue" SG_ 1535 BMS_HvBattTempSensorTemp_2T 255;
BA_ "GenSigASIL"  SG_ 1535 BMS_HvBattTempSensorTemp_2T 5;
BA_ "GenSigStartValue" SG_ 1535 BMS_HvBattTempSensorTemp_3T 255;
BA_ "GenSigASIL"  SG_ 1535 BMS_HvBattTempSensorTemp_3T 5;
BA_ "GenSigStartValue" SG_ 1535 BMS_HvBattTempSensorTemp_4T 255;
BA_ "GenSigASIL"  SG_ 1535 BMS_HvBattTempSensorTemp_4T 5;
BA_ "GenSigStartValue" SG_ 1535 BMS_HvBattTempSensorTemp_5T 255;
BA_ "GenSigASIL"  SG_ 1535 BMS_HvBattTempSensorTemp_5T 5;
BA_ "GenSigStartValue" SG_ 1535 BMS_HvBattTempSensorTemp_6T 255;
BA_ "GenSigASIL"  SG_ 1535 BMS_HvBattTempSensorTemp_6T 5;
BA_ "GenSigStartValue" SG_ 1535 BMS_HvBattTempSensorTemp_7T 255;
BA_ "GenSigASIL"  SG_ 1535 BMS_HvBattTempSensorTemp_7T 5;
BA_ "GenSigStartValue" SG_ 1535 BMS_HvBattTempSensorTemp_8T 255;
BA_ "GenSigASIL"  SG_ 1535 BMS_HvBattTempSensorTemp_8T 5;
BA_ "GenSigStartValue" SG_ 1535 BMS_HvBattTempSensorTemp_9T 255;
BA_ "GenSigASIL"  SG_ 1535 BMS_HvBattTempSensorTemp_9T 5;
BA_ "GenSigStartValue" SG_ 1535 BMS_HvBattTempSensorTemp_10T 255;
BA_ "GenSigASIL"  SG_ 1535 BMS_HvBattTempSensorTemp_10T 5;
BA_ "GenSigStartValue" SG_ 1535 BMS_HvBattTempSensorTemp_11T 255;
BA_ "GenSigASIL"  SG_ 1535 BMS_HvBattTempSensorTemp_11T 5;
BA_ "GenSigStartValue" SG_ 1535 BMS_HvBattTempSensorTemp_12T 255;
BA_ "GenSigASIL"  SG_ 1535 BMS_HvBattTempSensorTemp_12T 5;
BA_ "GenSigStartValue" SG_ 1535 BMS_HvBattTempSensorTemp_13T 255;
BA_ "GenSigASIL"  SG_ 1535 BMS_HvBattTempSensorTemp_13T 5;
BA_ "GenSigStartValue" SG_ 1535 BMS_HvBattTempSensorTemp_14T 255;
BA_ "GenSigASIL"  SG_ 1535 BMS_HvBattTempSensorTemp_14T 5;
BA_ "GenSigStartValue" SG_ 1535 BMS_HvBattTempSensorTemp_15T 255;
BA_ "GenSigASIL"  SG_ 1535 BMS_HvBattTempSensorTemp_15T 5;
BA_ "GenSigStartValue" SG_ 1535 BMS_HvBattTempSensorTemp_16T 255;
BA_ "GenSigASIL"  SG_ 1535 BMS_HvBattTempSensorTemp_16T 5;
BA_ "GenSigStartValue" SG_ 1535 BMS_HvBattTempSensorTemp_17T 255;
BA_ "GenSigASIL"  SG_ 1535 BMS_HvBattTempSensorTemp_17T 5;
BA_ "GenSigStartValue" SG_ 1535 BMS_HvBattTempSensorTemp_18T 255;
BA_ "GenSigASIL"  SG_ 1535 BMS_HvBattTempSensorTemp_18T 5;
BA_ "GenSigStartValue" SG_ 1535 BMS_HvBattTempSensorTemp_19T 255;
BA_ "GenSigASIL"  SG_ 1535 BMS_HvBattTempSensorTemp_19T 5;
BA_ "GenSigStartValue" SG_ 1535 BMS_HvBattTempSensorTemp_20T 255;
BA_ "GenSigASIL"  SG_ 1535 BMS_HvBattTempSensorTemp_20T 5;
BA_ "GenSigStartValue" SG_ 1535 BMS_HvBattTempSensorTemp_21T 255;
BA_ "GenSigASIL"  SG_ 1535 BMS_HvBattTempSensorTemp_21T 5;
BA_ "GenSigStartValue" SG_ 1535 BMS_HvBattTempSensorTemp_22T 255;
BA_ "GenSigASIL"  SG_ 1535 BMS_HvBattTempSensorTemp_22T 5;
BA_ "GenSigStartValue" SG_ 1535 BMS_HvBattTempSensorTemp_23T 255;
BA_ "GenSigASIL"  SG_ 1535 BMS_HvBattTempSensorTemp_23T 5;
BA_ "GenSigStartValue" SG_ 1535 BMS_HvBattTempSensorTemp_24T 255;
BA_ "GenSigASIL"  SG_ 1535 BMS_HvBattTempSensorTemp_24T 5;
BA_ "GenSigStartValue" SG_ 1535 BMS_HvBattTempSensorTemp_25T 255;
BA_ "GenSigASIL"  SG_ 1535 BMS_HvBattTempSensorTemp_25T 5;
BA_ "GenSigStartValue" SG_ 1535 BMS_HvBattTempSensorTemp_26T 255;
BA_ "GenSigASIL"  SG_ 1535 BMS_HvBattTempSensorTemp_26T 5;
BA_ "GenSigStartValue" SG_ 1535 BMS_HvBattTempSensorTemp_27T 255;
BA_ "GenSigASIL"  SG_ 1535 BMS_HvBattTempSensorTemp_27T 5;
BA_ "GenSigStartValue" SG_ 1535 BMS_HvBattTempSensorTemp_28T 255;
BA_ "GenSigASIL"  SG_ 1535 BMS_HvBattTempSensorTemp_28T 5;
BA_ "GenSigStartValue" SG_ 1535 BMS_HvBattTempSensorTemp_29T 255;
BA_ "GenSigASIL"  SG_ 1535 BMS_HvBattTempSensorTemp_29T 5;
BA_ "GenSigStartValue" SG_ 1535 BMS_HvBattTempSensorTemp_30T 255;
BA_ "GenSigASIL"  SG_ 1535 BMS_HvBattTempSensorTemp_30T 5;
BA_ "GenSigStartValue" SG_ 1535 BMS_HvBattTempSensorTemp_31T 255;
BA_ "GenSigASIL"  SG_ 1535 BMS_HvBattTempSensorTemp_31T 5;
BA_ "GenSigStartValue" SG_ 1535 BMS_HvBattTempSensorTemp_32T 255;
BA_ "GenSigASIL"  SG_ 1535 BMS_HvBattTempSensorTemp_32T 5;
BA_ "GenSigStartValue" SG_ 1535 BMS_HvBattTempSensorTemp_33T 255;
BA_ "GenSigASIL"  SG_ 1535 BMS_HvBattTempSensorTemp_33T 5;
BA_ "GenSigStartValue" SG_ 1535 BMS_HvBattTempSensorTemp_34T 255;
BA_ "GenSigASIL"  SG_ 1535 BMS_HvBattTempSensorTemp_34T 5;
BA_ "GenSigStartValue" SG_ 1535 BMS_HvBattTempSensorTemp_35T 255;
BA_ "GenSigASIL"  SG_ 1535 BMS_HvBattTempSensorTemp_35T 5;
BA_ "GenSigStartValue" SG_ 1535 BMS_HvBattTempSensorTemp_36T 255;
BA_ "GenSigASIL"  SG_ 1535 BMS_HvBattTempSensorTemp_36T 5;
BA_ "GenSigStartValue" SG_ 1535 BMS_HvBattTempSensorTemp_37T 255;
BA_ "GenSigASIL"  SG_ 1535 BMS_HvBattTempSensorTemp_37T 5;
BA_ "GenSigStartValue" SG_ 1535 BMS_HvBattTempSensorTemp_38T 255;
BA_ "GenSigASIL"  SG_ 1535 BMS_HvBattTempSensorTemp_38T 5;
BA_ "GenSigStartValue" SG_ 1535 BMS_HvBattTempSensorTemp_39T 255;
BA_ "GenSigASIL"  SG_ 1535 BMS_HvBattTempSensorTemp_39T 5;
BA_ "GenSigStartValue" SG_ 1535 BMS_HvBattTempSensorTemp_40T 255;
BA_ "GenSigASIL"  SG_ 1535 BMS_HvBattTempSensorTemp_40T 5;
BA_ "GenSigStartValue" SG_ 1535 BMS_HvBattTempSensorTemp_41T 255;
BA_ "GenSigASIL"  SG_ 1535 BMS_HvBattTempSensorTemp_41T 5;
BA_ "GenSigStartValue" SG_ 1535 BMS_HvBattTempSensorTemp_42T 255;
BA_ "GenSigASIL"  SG_ 1535 BMS_HvBattTempSensorTemp_42T 5;
BA_ "GenSigStartValue" SG_ 1535 BMS_HvBattTempSensorTemp_43T 255;
BA_ "GenSigASIL"  SG_ 1535 BMS_HvBattTempSensorTemp_43T 5;
BA_ "GenSigStartValue" SG_ 1535 BMS_HvBattTempSensorTemp_44T 255;
BA_ "GenSigASIL"  SG_ 1535 BMS_HvBattTempSensorTemp_44T 5;
BA_ "GenSigStartValue" SG_ 1535 BMS_HvBattTempSensorTemp_45T 255;
BA_ "GenSigASIL"  SG_ 1535 BMS_HvBattTempSensorTemp_45T 5;
BA_ "GenSigStartValue" SG_ 1535 BMS_HvBattTempSensorTemp_46T 255;
BA_ "GenSigASIL"  SG_ 1535 BMS_HvBattTempSensorTemp_46T 5;
BA_ "GenSigStartValue" SG_ 1535 BMS_HvBattTempSensorTemp_47T 255;
BA_ "GenSigASIL"  SG_ 1535 BMS_HvBattTempSensorTemp_47T 5;
BA_ "GenSigStartValue" SG_ 1535 BMS_HvBattTempSensorTemp_48T 255;
BA_ "GenSigASIL"  SG_ 1535 BMS_HvBattTempSensorTemp_48T 5;
BA_ "GenSigStartValue" SG_ 1535 BMS_BattTempSensorStartFrameNum 215;
BA_ "GenSigASIL"  SG_ 1535 BMS_BattTempSensorStartFrameNum 5;
BA_ "GenSigStartValue" SG_ 1535 BMS_HvBattTempSensorFrameTNum 61;
BA_ "GenSigASIL"  SG_ 1535 BMS_HvBattTempSensorFrameTNum 5;
BA_ "GenMsgILSupport" BO_ 1340 1;
BA_ "GenMsgCycleTime" BO_ 1340 500;
BA_ "GenSigASIL"  SG_ 1340 BMS_HvBattSerialNum_PDU1 5;
BA_ "GenSigASIL"  SG_ 1340 BMS_HvBattSerialNum_PDU2 5;
BA_ "GenSigASIL"  SG_ 1340 BMS_HvBattSerialNum_PDU3 5;
BA_ "GenSigASIL"  SG_ 1340 BMS_HvBattSerialNum_PDU4 5;
BA_ "GenSigASIL"  SG_ 1340 BMS_HvBattSerialNum_PDU5 5;
BA_ "GenSigASIL"  SG_ 1340 BMS_HvBattSerialNum_PDU6 5;
BA_ "GenMsgILSupport" BO_ 1224 1;
BA_ "GenMsgCycleTime" BO_ 1224 100;
BA_ "GenSigStartValue" SG_ 1224 BMS_HvBattCellVoltMax_Num 255;
BA_ "GenSigASIL"  SG_ 1224 BMS_HvBattCellVoltMax_Num 5;
BA_ "GenSigStartValue" SG_ 1224 BMS_HvBattCellVoltMax 65534;
BA_ "GenSigASIL"  SG_ 1224 BMS_HvBattCellVoltMax 5;
BA_ "GenSigStartValue" SG_ 1224 BMS_HvBattCellVoltMin_Num 255;
BA_ "GenSigASIL"  SG_ 1224 BMS_HvBattCellVoltMin_Num 5;
BA_ "GenSigStartValue" SG_ 1224 BMS_HvBattCellVoltMin 65534;
BA_ "GenSigASIL"  SG_ 1224 BMS_HvBattCellVoltMin 5;
BA_ "GenSigASIL"  SG_ 1224 BMS_Chg_Sts 5;
BA_ "GenMsgILSupport" BO_ 1230 1;
BA_ "GenMsgCycleTime" BO_ 1230 100;
BA_ "GenSigStartValue" SG_ 1230 BMS_HvBattCellU_1V 65534;
BA_ "GenSigASIL"  SG_ 1230 BMS_HvBattCellU_1V 5;
BA_ "GenSigStartValue" SG_ 1230 BMS_HvBattCellU_2V 65534;
BA_ "GenSigASIL"  SG_ 1230 BMS_HvBattCellU_2V 5;
BA_ "GenSigStartValue" SG_ 1230 BMS_HvBattCellU_3V 65534;
BA_ "GenSigASIL"  SG_ 1230 BMS_HvBattCellU_3V 5;
BA_ "GenSigStartValue" SG_ 1230 BMS_HvBattCellU_4V 65534;
BA_ "GenSigASIL"  SG_ 1230 BMS_HvBattCellU_4V 5;
BA_ "GenSigStartValue" SG_ 1230 BMS_HvBattCellU_5V 65534;
BA_ "GenSigASIL"  SG_ 1230 BMS_HvBattCellU_5V 5;
BA_ "GenSigStartValue" SG_ 1230 BMS_HvBattCellU_6V 65534;
BA_ "GenSigASIL"  SG_ 1230 BMS_HvBattCellU_6V 5;
BA_ "GenSigStartValue" SG_ 1230 BMS_HvBattCellU_7V 65534;
BA_ "GenSigASIL"  SG_ 1230 BMS_HvBattCellU_7V 5;
BA_ "GenSigStartValue" SG_ 1230 BMS_HvBattCellU_8V 65534;
BA_ "GenSigASIL"  SG_ 1230 BMS_HvBattCellU_8V 5;
BA_ "GenSigStartValue" SG_ 1230 BMS_HvBattCellU_9V 65534;
BA_ "GenSigASIL"  SG_ 1230 BMS_HvBattCellU_9V 5;
BA_ "GenSigStartValue" SG_ 1230 BMS_HvBattCellU_10V 65534;
BA_ "GenSigASIL"  SG_ 1230 BMS_HvBattCellU_10V 5;
BA_ "GenSigStartValue" SG_ 1230 BMS_HvBattCellU_11V 65534;
BA_ "GenSigASIL"  SG_ 1230 BMS_HvBattCellU_11V 5;
BA_ "GenSigStartValue" SG_ 1230 BMS_HvBattCellU_12V 65534;
BA_ "GenSigASIL"  SG_ 1230 BMS_HvBattCellU_12V 5;
BA_ "GenSigStartValue" SG_ 1230 BMS_HvBattCellU_13V 65534;
BA_ "GenSigASIL"  SG_ 1230 BMS_HvBattCellU_13V 5;
BA_ "GenSigStartValue" SG_ 1230 BMS_HvBattCellU_14V 65534;
BA_ "GenSigASIL"  SG_ 1230 BMS_HvBattCellU_14V 5;
BA_ "GenSigStartValue" SG_ 1230 BMS_HvBattCellU_15V 65534;
BA_ "GenSigASIL"  SG_ 1230 BMS_HvBattCellU_15V 5;
BA_ "GenSigStartValue" SG_ 1230 BMS_HvBattCellU_16V 65534;
BA_ "GenSigASIL"  SG_ 1230 BMS_HvBattCellU_16V 5;
BA_ "GenSigStartValue" SG_ 1230 BMS_HvBattCellU_17V 65534;
BA_ "GenSigASIL"  SG_ 1230 BMS_HvBattCellU_17V 5;
BA_ "GenSigStartValue" SG_ 1230 BMS_HvBattCellU_18V 65534;
BA_ "GenSigASIL"  SG_ 1230 BMS_HvBattCellU_18V 5;
BA_ "GenSigStartValue" SG_ 1230 BMS_HvBattCellU_19V 65534;
BA_ "GenSigASIL"  SG_ 1230 BMS_HvBattCellU_19V 5;
BA_ "GenSigStartValue" SG_ 1230 BMS_HvBattCellU_20V 65534;
BA_ "GenSigASIL"  SG_ 1230 BMS_HvBattCellU_20V 5;
BA_ "GenSigStartValue" SG_ 1230 BMS_HvBattCellU_21V 65534;
BA_ "GenSigASIL"  SG_ 1230 BMS_HvBattCellU_21V 5;
BA_ "GenSigStartValue" SG_ 1230 BMS_HvBattCellU_22V 65534;
BA_ "GenSigASIL"  SG_ 1230 BMS_HvBattCellU_22V 5;
BA_ "GenSigStartValue" SG_ 1230 BMS_HvBattCellU_23V 65534;
BA_ "GenSigASIL"  SG_ 1230 BMS_HvBattCellU_23V 5;
BA_ "GenSigStartValue" SG_ 1230 BMS_HvBattCellU_24V 65534;
BA_ "GenSigASIL"  SG_ 1230 BMS_HvBattCellU_24V 5;
BA_ "GenSigStartValue" SG_ 1230 BMS_HvBattCellU_25V 65534;
BA_ "GenSigASIL"  SG_ 1230 BMS_HvBattCellU_25V 5;
BA_ "GenSigStartValue" SG_ 1230 BMS_HvBattCellU_26V 65534;
BA_ "GenSigASIL"  SG_ 1230 BMS_HvBattCellU_26V 5;
BA_ "GenSigStartValue" SG_ 1230 BMS_HvBattCellU_27V 65534;
BA_ "GenSigASIL"  SG_ 1230 BMS_HvBattCellU_27V 5;
BA_ "GenSigStartValue" SG_ 1230 BMS_HvBattCellU_28V 65534;
BA_ "GenSigASIL"  SG_ 1230 BMS_HvBattCellU_28V 5;
BA_ "GenSigStartValue" SG_ 1230 BMS_HvBattCellU_29V 65534;
BA_ "GenSigASIL"  SG_ 1230 BMS_HvBattCellU_29V 5;
BA_ "GenSigStartValue" SG_ 1230 BMS_HvBattCellU_30V 65534;
BA_ "GenSigASIL"  SG_ 1230 BMS_HvBattCellU_30V 5;
BA_ "GenSigStartValue" SG_ 1230 BMS_BattCellstartframeNum 65535;
BA_ "GenSigASIL"  SG_ 1230 BMS_BattCellstartframeNum 5;
BA_ "GenSigStartValue" SG_ 1230 BMS_HvBattCellFrameTotalNum 255;
BA_ "GenSigASIL"  SG_ 1230 BMS_HvBattCellFrameTotalNum 5;
BA_ "GenMsgILSupport" BO_ 1041 1;
BA_ "GenMsgCycleTime" BO_ 1041 100;
BA_ "GenSigASIL"  SG_ 1041 CRM_RecongnitionResult 5;
BA_ "GenSigASIL"  SG_ 1041 BMS_InsulationPos 5;
BA_ "GenSigASIL"  SG_ 1041 BMS_IsoPosVolt 5;
BA_ "GenSigASIL"  SG_ 1041 BMS_IsoNegVolt 5;
BA_ "GenSigASIL"  SG_ 1041 BMS_IsoPosSwtSts 5;
BA_ "GenSigASIL"  SG_ 1041 BMS_IsoNegSwtSts 5;
BA_ "GenSigASIL"  SG_ 1041 BCL_ChareMode 5;
BA_ "GenSigASIL"  SG_ 1041 BMS_HVPwrDwnRsn 5;
BA_ "GenSigASIL"  SG_ 1041 BMS_InsulationProhibitRsn 5;
BA_ "GenSigASIL"  SG_ 1041 BMS_BPSWakeupSt 5;
BA_ "GenSigASIL"  SG_ 1041 BMS_AFEWakeupSt 5;
BA_ "GenSigASIL"  SG_ 1041 BMS_NMWakeupSt 5;
BA_ "GenSigASIL"  SG_ 1041 BMS_CC2WakeupSt 5;
BA_ "GenSigASIL"  SG_ 1041 CCS_ChargeAllowed 5;
BA_ "GenSigASIL"  SG_ 1041 BMS_ResetRsn 5;
BA_ "GenSigASIL"  SG_ 1041 BMS_HVPwrOnFailRsn 5;
BA_ "GenSigStartValue" SG_ 1041 BMS_AirPressure 65534;
BA_ "GenSigASIL"  SG_ 1041 BMS_AirPressure 5;
BA_ "GenSigStartValue" SG_ 1041 BMS_AirPressureRate 254;
BA_ "GenSigASIL"  SG_ 1041 BMS_AirPressureRate 5;
BA_ "GenSigStartValue" SG_ 1041 BMS_BattTempRate 254;
BA_ "GenSigASIL"  SG_ 1041 BMS_BattTempRate 5;
BA_ "GenSigStartValue" SG_ 1041 BMS_CellVoltSum 16382;
BA_ "GenSigASIL"  SG_ 1041 BMS_CellVoltSum 5;
BA_ "GenSigStartValue" SG_ 1041 BMS_DchaCurrtShoTiMax 16382;
BA_ "GenSigASIL"  SG_ 1041 BMS_DchaCurrtShoTiMax 5;
BA_ "GenSigStartValue" SG_ 1041 BMS_ChrgCurrtShoTiMax 16382;
BA_ "GenSigASIL"  SG_ 1041 BMS_ChrgCurrtShoTiMax 5;
BA_ "GenSigStartValue" SG_ 1041 BMS_DchaPwrLongTiMax 16382;
BA_ "GenSigASIL"  SG_ 1041 BMS_DchaPwrLongTiMax 5;
BA_ "GenSigStartValue" SG_ 1041 BMS_ChrgPwrLongTiMax 16382;
BA_ "GenSigASIL"  SG_ 1041 BMS_ChrgPwrLongTiMax 5;
BA_ "GenSigStartValue" SG_ 1041 BMS_DchaCurrtLongTiMax 16382;
BA_ "GenSigASIL"  SG_ 1041 BMS_DchaCurrtLongTiMax 5;
BA_ "GenSigStartValue" SG_ 1041 BMS_ChrgCurrtLongTiMax 16382;
BA_ "GenSigASIL"  SG_ 1041 BMS_ChrgCurrtLongTiMax 5;
BA_ "GenSigStartValue" SG_ 1041 BMS_DchaCurrtContnsMax 16382;
BA_ "GenSigASIL"  SG_ 1041 BMS_DchaCurrtContnsMax 5;
BA_ "GenSigStartValue" SG_ 1041 BMS_ChrgCurrtContnsMax 16382;
BA_ "GenSigASIL"  SG_ 1041 BMS_ChrgCurrtContnsMax 5;
BA_ "GenSigASIL"  SG_ 1041 BRO_BMSChargeReady 5;
BA_ "GenSigASIL"  SG_ 1041 CRO_ChargeReady 5;
BA_ "GenSigASIL"  SG_ 1041 BMS_BattChrgNeeded 5;
BA_ "GenSigASIL"  SG_ 1041 BMS_DcDisChgStatus 5;
BA_ "GenSigASIL"  SG_ 1041 BMS_CC1_Resistance 5;
BA_ "GenSigASIL"  SG_ 1041 BMS_CC2_Resistance 5;
BA_ "GenSigASIL"  SG_ 1041 BMS_DC_DisChrgCurr 5;
BA_ "GenSigASIL"  SG_ 1041 BMS_DC_DisChrgPower 5;
BA_ "GenSigASIL"  SG_ 1041 BMS_DC_DisChrgEngy 5;
BA_ "GenSigStartValue" SG_ 1041 BMS_DC_DisChrgRemainTi 2047;
BA_ "GenSigASIL"  SG_ 1041 BMS_DC_DisChrgRemainTi 5;
BA_ "GenSigStartValue" SG_ 1041 BMS_DC_DisChrgVolt 65535;
BA_ "GenSigASIL"  SG_ 1041 BMS_DC_DisChrgVolt 5;
BA_ "GenSigASIL"  SG_ 1041 BMS_QCCDetdtVoltage 5;
BA_ "GenSigASIL"  SG_ 1041 BMS_InsulationNeg 5;
BA_ "GenSigASIL"  SG_ 1041 BMS_SOCE_EU 5;
BA_ "GenMsgILSupport" BO_ 281 1;
BA_ "GenMsgCycleTime" BO_ 281 10;
BA_ "GenSigASIL"  SG_ 281 BMS_ColdbootPwr 5;
BA_ "GenSigASIL"  SG_ 281 BMS_StateOfChargeCorrect 5;
BA_ "GenSigASIL"  SG_ 281 BMS_BusVoltage 5;
BA_ "GenMsgILSupport" BO_ 1275 1;
BA_ "GenMsgCycleTime" BO_ 1275 100;
BA_ "GenSigASIL"  SG_ 1275 BMSH_PowerChangeSign 5;
BA_ "GenSigASIL"  SG_ 1275 BMSH_PackInstantOutPower 5;
BA_ "GenSigASIL"  SG_ 1275 BMSH_PackInstantRecoveryPower 5;
BA_ "GenSigASIL"  SG_ 1275 BMS_SOCCalAlarm 5;
BA_ "GenSigASIL"  SG_ 1275 BMS_PosInsulationSt 5;
BA_ "GenSigASIL"  SG_ 1275 BMS_NegInsulationSt 5;
BA_ "GenSigASIL"  SG_ 1275 BMSH_NegInsulationResis 5;
BA_ "GenSigASIL"  SG_ 1275 BMSH_PosInsulationResis 5;
BA_ "GenSigASIL"  SG_ 1275 CML_OutputVoltageMax 5;
BA_ "GenSigASIL"  SG_ 1275 CML_OutputVoltageMin 5;
BA_ "GenSigASIL"  SG_ 1275 CML_OutputCurentMax 5;
BA_ "GenSigASIL"  SG_ 1275 CML_OutputCurentMin 5;
BA_ "GenSigASIL"  SG_ 1275 BCL_VoltageRequire 5;
BA_ "GenSigASIL"  SG_ 1275 BCL_CurrentRequire 5;
BA_ "GenSigASIL"  SG_ 1275 CCS_OutputVoltage 5;
BA_ "GenSigASIL"  SG_ 1275 CCS_OutputCurent 5;
BA_ "GenMsgILSupport" BO_ 1127 1;
BA_ "GenMsgCycleTime" BO_ 1127 100;
BA_ "GenSigASIL"  SG_ 1127 CDU_1_CRC1 5;
BA_ "GenSigASIL"  SG_ 1127 CDU_1_RollgCntr1 5;
BA_ "GenSigASIL"  SG_ 1127 CDU_1_Resd1 5;
BA_ "GenSigASIL"  SG_ 1127 DCDC_HvVolt 5;
BA_ "GenSigASIL"  SG_ 1127 DCDC_HVCurr 5;
BA_ "GenSigASIL"  SG_ 1127 DCDC_FaultCode 5;
BA_ "GenSigASIL"  SG_ 1127 CDU_1_CRC2 5;
BA_ "GenSigASIL"  SG_ 1127 CDU_1_RollgCntr2 5;
BA_ "GenSigASIL"  SG_ 1127 CDU_1_Resd2 5;
BA_ "GenSigASIL"  SG_ 1127 DCDC_LvSideCurr 5;
BA_ "GenSigASIL"  SG_ 1127 DCDC_LvSideVolt 2;
BA_ "GenSigASIL"  SG_ 1127 DCDC_FaultLevelSts 2;
BA_ "GenSigASIL"  SG_ 1127 DCDC_EnableSts 5;
BA_ "GenSigASIL"  SG_ 1127 DCDC_OverTemp 5;
BA_ "GenSigASIL"  SG_ 1127 DCDC_LvSideCurrMax 5;
BA_ "GenMsgILSupport" BO_ 1182 1;
BA_ "GenMsgCycleTime" BO_ 1182 100;
BA_ "GenSigASIL"  SG_ 1182 CDU_2_CRC1 5;
BA_ "GenSigASIL"  SG_ 1182 CDU_2_RollgCntr1 5;
BA_ "GenSigASIL"  SG_ 1182 CDU_2_Resd1 5;
BA_ "GenSigASIL"  SG_ 1182 OBC_ChgCurr 1;
BA_ "GenSigASIL"  SG_ 1182 OBC_ChgVolt 1;
BA_ "GenSigASIL"  SG_ 1182 OBC_MaxOutputPower 1;
BA_ "GenSigASIL"  SG_ 1182 OBC_FaultCode 5;
BA_ "GenSigASIL"  SG_ 1182 CDU_2_CRC2 5;
BA_ "GenSigASIL"  SG_ 1182 CDU_2_RollgCntr2 5;
BA_ "GenSigASIL"  SG_ 1182 CDU_2_Resd2 5;
BA_ "GenSigASIL"  SG_ 1182 OBC_CP_DutyCycleValue 5;
BA_ "GenSigStartValue" SG_ 1182 CDU_Coolanttemp 40;
BA_ "GenSigASIL"  SG_ 1182 CDU_Coolanttemp 5;
BA_ "GenSigStartValue" SG_ 1182 OBC_ChgInterfaceTemp 40;
BA_ "GenSigASIL"  SG_ 1182 OBC_ChgInterfaceTemp 5;
BA_ "GenSigASIL"  SG_ 1182 OBC_MaxDisOutPower 5;
BA_ "GenSigASIL"  SG_ 1182 OBC_CPMaxVolt 5;
BA_ "GenSigASIL"  SG_ 1182 CDU_2_CRC3 5;
BA_ "GenSigASIL"  SG_ 1182 CDU_2_RollgCntr3 5;
BA_ "GenSigASIL"  SG_ 1182 CDU_2_Resd3 5;
BA_ "GenSigASIL"  SG_ 1182 OBC_ChrgrInputCurr1 5;
BA_ "GenSigASIL"  SG_ 1182 OBC_ChrgrInputCurr2 5;
VAL_ 33 ACU_3_LongitudinalAcceleration 65535 "Invalid" ;
VAL_ 33 ACU_3_LongitudinalAccelerationVD 3 "Initialize" 2 "Invalid" 1 "Reserved" 0 "Valid" ;
VAL_ 33 ACU_3_CrashOutputSts 32 "Roll Crash" 16 "Rear Crash" 8 "Right Side Crash" 4 "Left Side Crash" 2 "Front Crash" 1 "Belt Crash" 0 "No crash" ;
VAL_ 1299 BMS_PackVoltageDis 65535 "Invalid" 65534 "Abnormal
" ;
VAL_ 1299 BMS_PackCurrentDis 65535 "Invalid" 65534 "Abnormal
" ;
VAL_ 1291 BMS_TBOXHvBattMaxT 255 "Invalid" 254 "Abnormal
" ;
VAL_ 1291 BMS_TBOXHvBattMinT 255 "Invalid" 254 "Abnormal
" ;
VAL_ 1291 BMS_SOCLight 127 "Invalid" ;
VAL_ 1295 BMS_RemainChg_Time 2047 "Invalid" ;
VAL_ 1295 BMS_HvBattErrSt 4 "emergency shutdown" 3 "stop run                             " 2 "power reduction   " 1 "warning                               " 0 "no fault" ;
VAL_ 1295 BMS_OverTemp_LightSts 1 "Lamp ON" 0 "Lamp OFF" ;
VAL_ 1295 BMS_ChgWireConnect_LightSts 1 "Connect" 0 "DIsconnect" ;
VAL_ 1295 BMS_Chg_LightSts 1 "charging" 0 "No Charge" ;
VAL_ 1295 BMS_HVstsDis 1 "HV" 0 "no HV" ;
VAL_ 1295 BMS_ThermalRunawayDis 1 "thermalrunaway occur" 0 "no thermalrunaway" ;
VAL_ 1295 BMS_TBOXIsolationFault 3 "Fault L3" 2 "Fault L2" 1 "Fault L1                              " 0 "no fault" ;
VAL_ 1295 BMS_TBOXHVIL1Fault 1 "Fault" 0 "No fault                             " ;
VAL_ 1295 BMS_PreWarmDis 2 "keepwarm state" 1 "preheat state" 0 "none" ;
VAL_ 258 BMS_PackVoltage 65535 "Invalid" 65534 "Abnormal
" ;
VAL_ 258 BMS_PackCurrent 65535 "Invalid" 65534 "Abnormal
" ;
VAL_ 258 BMS_HvBattSts 14 "PreHeat complete Mode" 13 "Keep warm complete Mode" 12 "afterrun" 11 "fault" 10 "emergencypowerdown" 9 "powerdown" 8 "keep warm" 7 "PreHeat Mode" 6 "Boost charging mode   " 5 "DC charge Mode      " 4 "AC charge Mode" 3 "HVOn" 2 "Precharge" 1 "standby" 0 "Init" ;
VAL_ 258 BMS_SysSelfCheck 3 "no fault" 2 "flaut                                      " 1 "self_checking                  " ;
VAL_ 258 BMS_HVBattThermRunaway 2 "invalid" 1 "warning
" 0 "normal
" ;
VAL_ 258 BMS_DcDisChgCurrReq 4095 "Invalid" ;
VAL_ 258 BMS_C2Target_Buck_Voltage 65535 "Invalid" ;
VAL_ 258 BMS_DisChrgDcCnctrDetd 15 "Reserved" 14 "Reserved" 13 "Reserved" 12 "Reserved" 11 "Reserved" 10 "Reserved" 9 "Reserved" 8 "Reserved" 7 "Reserved" 6 "Reserved" 5 "V2G Connected" 4 "V2V DisChgGunConnceted" 3 "V2L Connected" 2 "V2V Connceted" 1 "V2x Connector not detected
" 0 "Init
" ;
VAL_ 258 BMS_InfraDcUActDc 16383 "Init" 16382 "Error
" ;
VAL_ 258 BMS_InfraDcIActDc 16383 "Init" 16382 "Error
" ;
VAL_ 258 BMS_HvBattDynChrgnILim 16383 "Init" 16382 "Error
" ;
VAL_ 258 BMS_HvBattUChrgnLim 16383 "Init" 16382 "Error
" ;
VAL_ 258 BMS_ChrgDcIAvl 16383 "Init" 16382 "Error
" ;
VAL_ 258 BMS_DChrgAPlusSt 1 "active" 0 "not active          " ;
VAL_ 258 BMS_ChrgDcCnctrDetd 3 "SNS/Fault" 2 "Connector detected
" 1 "Connector not detected
" 0 "Init
" ;
VAL_ 258 BMS_DCChgMode 6 "ChgFault" 5 "ChgWaring" 4 "ChgEnd" 3 "Chging" 2 "ParaConfig" 1 "HandOver" 0 "Default" ;
VAL_ 258 BMS_ChrgDcChrgnFltStopReas 7 "Other fault" 6 "Boost fault" 5 "VCU fault" 4 "DC charge not allowd because low temperature
" 3 "CC2 fault
" 2 "BMS fault
" 1 "End by Infrastructure fault
" 0 "no fault
" ;
VAL_ 258 BMS_ChgRemTime 2047 "Init" 2046 "SNA/Fault
" ;
VAL_ 258 BMS_ChargeRequest_Mode 15 "init" 14 "Reserved" 13 "Reserved" 12 "Reserved" 11 "Reserved" 10 "Reserved" 9 "Reserved" 8 "Reserved" 7 "Reserved" 6 "Reserved" 5 "Reserved" 4 "Charge precharge request                         " 3 "DC Fast Charging request" 2 "Boost Charging request" 1 "AC Charging request" 0 "No request" ;
VAL_ 258 BMS_StateOfChargeDis 255 "Invalid" 254 "Abnormal
" ;
VAL_ 258 BMS_StateOfEnergy 65534 "Abnormal" 65535 "Invalid" ;
VAL_ 258 BMS_StateOfHealth 127 "Init" 126 "Error
" ;
VAL_ 258 BMS_BlanceState 1 "Balance ON" 0 "Balance OFF                             " ;
VAL_ 258 BMS_IsolationFault 3 "Fault L3" 2 "Fault L2" 1 "Fault L1                              " 0 "no fault" ;
VAL_ 258 BMS_HVILFault_DC 1 "Fault" 0 "No fault                             " ;
VAL_ 258 BMS_HVILFault_FMCU 1 "Fault" 0 "No fault                             " ;
VAL_ 258 BMS_HVILFault_RMCU 1 "Fault" 0 "No fault                             " ;
VAL_ 258 BMS_SOCDis 16383 "Invalid" 16382 "Abnormal
" ;
VAL_ 258 BMS_InfraDcIActDcMin 16383 "Init" 16382 "Error" ;
VAL_ 520 BMS_C2Target_Chg_Voltage 65535 "Invalid" ;
VAL_ 520 BMS_CHGstation_MAXPwr 255 "Invalid" ;
VAL_ 520 BMS_NV_relay_Sts 6 "OpenLoad" 5 "SCG" 4 "SCB" 3 "Stuck Closed" 2 "Stuck Open" 1 "closed" 0 "open
" ;
VAL_ 520 BMS_PV_relay_Sts 6 "OpenLoad" 5 "SCG" 4 "SCB" 3 "Stuck Closed" 2 "Stuck Open" 1 "closed" 0 "open
" ;
VAL_ 520 BMS_QCP_relay_Sts 6 "OpenLoad" 5 "SCG" 4 "SCB" 3 "Stuck Closed" 2 "Stuck Open" 1 "closed" 0 "open
" ;
VAL_ 520 BMS_QCN_relay_Sts 6 "OpenLoad" 5 "SCG" 4 "SCB" 3 "Stuck Closed" 2 "Stuck Open" 1 "closed" 0 "open
" ;
VAL_ 520 BMS_HvBattThermReqLevel 15 "reserved" 14 "reserved" 13 "reserved" 12 "reserved" 11 "reserved" 10 "reserved" 9 "reserved" 8 "Battery cooling L4" 7 "Battery heating L4" 6 "Battery cooling L3" 5 "Battery cooling L2" 4 "Battery cooling L1 " 3 "Battery heating L3 " 2 "Battery heating L2 " 1 "Battery  heating L1 " 0 "No request" ;
VAL_ 520 BMS_Prechage_relay_Sts 6 "OpenLoad" 5 "SCG" 4 "SCB" 3 "Stuck Closed" 2 "Stuck Open" 1 "closed" 0 "open
" ;
VAL_ 520 BMS_HvBattThermReqMode 14 "reserved" 13 "reserved" 12 "reserved" 11 "reserved" 10 "DC exit preheating request" 9 "DC preheating request" 8 "AC exit preheating request" 7 "AC preheating request" 6 "Exit KeepWarm  Heating request" 5 "KeepWarm  Heating request" 4 "Battery cooling MAX request
" 3 "Battery cooling request
" 2 "Balancing request
" 1 "Battery  heating request
" 0 "No request" ;
VAL_ 520 BMS_ClntTHvBattIn 255 "Error" 254 "Init
" ;
VAL_ 520 BMS_ClntTHvBattOut 255 "Error" 254 "Init
" ;
VAL_ 520 BMS_HvBattClntInTReq 127 "Error" 126 "Init
" ;
VAL_ 520 BMS_HvBattClntFlowReq 127 "Error" 126 "Init
" ;
VAL_ 520 BMS_HvBattAvgT 255 "Error" 254 "Init
" ;
VAL_ 520 BMS_HvBattMaxT 255 "Invalid" 254 "Abnormal
" ;
VAL_ 520 BMS_HvBattMinT 255 "Invalid" 254 "Abnormal
" ;
VAL_ 520 BMS_HvBattTdiff 127 "Error" 126 "Init
" ;
VAL_ 520 BMS_OutPosU 16383 "Invalid" 16382 "Abnormal
" ;
VAL_ 520 BMS_OutNegU 16383 "Invalid" 16382 "Abnormal
" ;
VAL_ 520 BMS_ChrgTrgtSOC 127 "Invalid" ;
VAL_ 520 BMS_outQCPosU 16383 "Invalid" 16382 "Abnormal
" ;
VAL_ 520 BMS_outQCNegU 16383 "Invalid" 16382 "Abnormal
" ;
VAL_ 520 BMS_Middlesplit_relay_Sts 6 "OpenLoad" 5 "SCG" 4 "SCB" 3 "Stuck Closed" 2 "Stuck Open" 1 "closed" 0 "open
" ;
VAL_ 520 BMS_DCChrgSts 23 "V2GDisChrg_Complt" 22 "V2GDisChrg_Fault" 21 "V2GDisChrg_Warning" 20 "V2GDisChrg_End" 19 "V2GDisChrging" 18 "V2GDisChrg_Discharging_SendBCSP" 17 "V2GDisChrg_ParaConfig_SendBCPP" 16 "V2GDisChrg_HadnOver_SendBDC" 15 "BoostChrg_Charging" 14 "BoostChrg_SendC2TrgtVlt" 13 "Charging_PreheatComplt" 12 "ChgEnd_Preheat" 11 "Charging_Preheat" 10 "ChgFault" 9 "ChgWaring" 8 "ChgEnd" 7 "ChgComplt" 6 "Chging" 5 "ParaConfig_SendBRO" 4 "ParaConfig_SendBCP" 3 "ParaConfig_SendBRM" 2 "HandOver_SendBHM" 1 "Standby" 0 "Init" ;
VAL_ 520 BMS_ACChrgSts 15 "Reserved" 14 "Reserved" 13 "Reserved" 12 "Reserved" 11 "Reserved" 10 "AC_Charge_PreheatComplt" 9 "AC_Charge_Preheat" 8 "AC_Chrg_KeepwarmComplt" 7 "AC_Chrg_Keepwarm" 6 "AC_ChrgWarning" 5 "AC_ChrgFault" 4 "AC_ChreEnd" 3 "AC_Chrg_Complt" 2 "AC_Charging" 1 "Standby" 0 "Init" ;
VAL_ 520 BMS_BattCurrtSnsr1 32767 "Invalid" 32766 "Initial Value" ;
VAL_ 520 BMS_BattCurrtSnsr2 32767 "Invalid" 32766 "Initial Value" ;
VAL_ 520 BMS_SOHCapFade 255 "Invalid" 254 "Initial Value" ;
VAL_ 520 BMS_SOHResInc 255 "Invalid" 254 "Initial Value" ;
VAL_ 523 BMS_HvBattPMaxReChrgLim 16383 "Init" 16382 "Error
" ;
VAL_ 523 BMS_HvBattIMaxReChrgLim 2047 "Init" 2046 "Error
" ;
VAL_ 523 BMS_HvBattPMaxDchaLim 16383 "Init" 16382 "Error
" ;
VAL_ 523 BMS_HvBattIMaxDchaLim 2047 "Init" 2046 "Error
" ;
VAL_ 523 BMS_KL30Volt 2047 "Invalid" ;
VAL_ 523 BMS_kL87Volt 2047 "Invalid" ;
VAL_ 523 BMS_HvBattUDchaLim 16383 "Init" 16382 "Error
" ;
VAL_ 523 BMSH_MaxChgPwrPeak 4095 "Invalid" ;
VAL_ 523 BMSH_MaxDchgPwrPeak 4095 "Invalid" ;
VAL_ 523 BMS_PackSOCAct 1023 "Invalid" 1022 "Initial Value" ;
VAL_ 523 BMS_PackSOCCalc 1023 "Invalid" 1022 "Initial Value" ;
VAL_ 1055 BMSH_MILReq 1 "Active" 0 "Inactive" ;
VAL_ 1055 BMS_ErrorLevel 8 "HvBattFaultLevel 8" 7 "HvBattFaultLevel 7" 6 "HvBattFaultLevel 6" 5 "HvBattFaultLevel 5" 4 "HvBattFaultLevel 4" 3 "HvBattFaultLevel 3" 2 "HvBattFaultLevel 2" 1 "HvBattFaultLevel 1" 0 "No_HvBattError" ;
VAL_ 1055 BMS_HvBattUnderTemperature 1 "Fault" 0 "no fault" ;
VAL_ 1055 BMS_PwrDerateFlg 2 "Vtg_0 active" 1 "Vtg_100 active" 0 "inactive" ;
VAL_ 1055 BMS_CHGstation_LowPWRFlg 3 "reserved" 2 "reserved" 1 "Chargestion power too low" 0 "inactive" ;
VAL_ 1055 BMS_bHint4FullChrgFlg 1 "Prompt for user to fully charge" 0 "No user full charge prompt required" ;
VAL_ 1055 BMS_StateOfChargeDis 255 "Invalid" 254 "Abnormal
" ;
VAL_ 1055 BMS_FastChargingFlg 1 "Fast Charging" 0 "Not active" ;
VAL_ 1055 BMS_LowCellVltChrgFlg 1 "The battery cell is over discharged and needs to be recharged" 0 "Normal" ;
VAL_ 1055 BMS_EngineStartReq 1 "Active" 0 "Not Active" ;
VAL_ 811 BMS_HvBattCellVoltMax_Num 255 "Invalid" 254 "Abnormal
" ;
VAL_ 811 BMS_HvBattCellVoltMax 65535 "Invalid" 65534 "Abnormal
" ;
VAL_ 811 BMS_HvBattCellVoltMin_Num 255 "Invalid" 254 "Abnormal
" ;
VAL_ 811 BMS_HvBattCellVoltMin 65535 "Invalid" 65534 "Abnormal
" ;
VAL_ 811 BMS_Chg_Sts 15 "Invalid" 14 "Abnomal      " 4 "charge complete" 3 "no charge                                                                                                                            " 1 "Parking chagre                                                                                                                                                                                                                                                                                          0x2:Driving charge                                                                                                       " ;
VAL_ 811 BMS_PackSOCNotAvrlble 1023 "Invalid" 1022 "Initial Value" ;
VAL_ 811 BMS_DchaPwrContnsMax 16383 "Invalid" 16382 "Initial Value" ;
VAL_ 811 BMS_ChrgPwrContnsMax 16383 "Invalid" 16382 "Initial Value" ;
VAL_ 811 BMS_APlusWakeupSt 1 "A+ awaken" 0 "Not awakened" ;
VAL_ 811 BMS_KL15WakeupSt 1 "HW awaken" 0 "Not awakened" ;
VAL_ 811 BMSH_CHGPrechargeRelaySts 2 "Closed" 1 "Open" 0 "Not Active" ;
VAL_ 1290 BMS_HvBattCellOverU 4 "Fault Level 4" 3 "Fault Level 3" 2 "Fault Level 2" 1 "Fault Level 1" 0 "Normal" ;
VAL_ 1290 BMS_HvBattCellUnderU 4 "Fault Level 4" 3 "Fault Level 3" 2 "Fault Level 2" 1 "Fault Level 1" 0 "Normal" ;
VAL_ 1290 BMS_HvBattUnderU 2 "Fault Level 2" 1 "Fault Level 1" 0 "Normal" ;
VAL_ 1290 BMS_HvBattDischargeOverCurrent 4 "Fault Level 4" 3 "Fault Level 3
" 2 "Fault Level 2
" 1 "Fault Level 1
" 0 "Normal
" ;
VAL_ 1290 BMS_HvBattChargeOverCurrent 4 "Fault Level 4" 3 "Fault Level 3
" 2 "Fault Level 2
" 1 "Fault Level 1
" 0 "Normal
" ;
VAL_ 1290 BMS_HvBattOverU 2 "Fault Level 2" 1 "Fault Level 1" 0 "Normal" ;
VAL_ 1290 BMS_HvBattMismatching 1 "Battery Pack Mismatch Failure" 0 "Normal State
" ;
VAL_ 1290 BMS_HvBattSocJump 1 "SOC jump warning" 0 "Normal,
" ;
VAL_ 1290 BMS_HvBattCellUUnif 1 "Failure" 0 "Normal
" ;
VAL_ 1290 BMS_HvBattLowSoc 1 "Failure" 0 "Normal
" ;
VAL_ 1290 BMS_HvBattOverSoc 1 "Failure" 0 "Normal
" ;
VAL_ 1290 BMS_HvBattTempUniformity 1 "Failure" 0 "Normal
" ;
VAL_ 1290 BMS_BattInterCANErr 1 "Failure" 0 "Normal
" ;
VAL_ 1290 BMS_HvBattOverCharging 1 "Failure" 0 "Normal
" ;
VAL_ 1290 BMS_HvBattOverTemperature 4 "Fault Level 4" 3 "Fault Level 3" 2 "Fault Level 2" 1 "Fault Level 1" 0 "Normal" ;
VAL_ 1290 BMS_PrimaryCurrtSnsrTemp 255 "Invalid" 254 "Initial Value" ;
VAL_ 1290 BMS_EquTempMax 255 "Invalid" 254 "Initial Value" ;
VAL_ 1531 BMS_HvBattSoeActDisChaCyc 65534 "Abnormal" 65535 "Invalid" ;
VAL_ 1531 BMS_HvBattSoeActReChaCyc 65534 "Abnormal" 65535 "Invalid" ;
VAL_ 1531 BMS_HvBattRatedEnergy 16383 "Invalid" 16382 "Abnormal
" ;
VAL_ 1531 BMS_HvBattRatedU 16383 "Invalid" 16382 "Abnormal
" ;
VAL_ 1531 BMS_HvBattTypeCode 255 "other type" 252 "Fuel Cell
" 7 "LTO
" 6 "Supercapacitors
" 5 "Polymer Lithium ion
" 4 "NCM
" 3 "LCO
" 2 "LMO
" 1 "LFP
" 0 "reserved
" ;
VAL_ 1531 BMS_HvBattManufcCode -2 "Abnormal" -1 "Invalid
" ;
VAL_ 1531 BMS_HvBattTempSensorTotalNum 65535 "Invalid" 65534 "Abnormal
" ;
VAL_ 1531 BMS_HvBattTempSensorTempMaxNum 255 "Invalid" 254 "Abnormal
" ;
VAL_ 1531 BMS_HvBattTempSensorTempMinNum 255 "Invalid" 254 "Abnormal
" ;
VAL_ 1531 BMS_HvBattTempMaxNum 255 "Invalid" 254 "Abnormal
" ;
VAL_ 1531 BMS_HvBattTempMinNum 255 "Invalid" 254 "Abnormal
" ;
VAL_ 1531 BMS_BattCellTotalNum 65535 "Invalid" 65534 "Abnormal
" ;
VAL_ 1531 BMS_HvBattVoltMaxNum 255 "Invalid" 254 "Abnormal
" ;
VAL_ 1531 BMS_HvBattVoltMinNum 255 "Invalid" 254 "Abnormal
" ;
VAL_ 1531 BMS_ActualSOCMin 4095 "Invalid" ;
VAL_ 1531 BMS_ActualSOCMax 4095 "Invalid" ;
VAL_ 1535 BMS_HvBattTempSensorTemp_1T 255 "Invalid" 254 "Abnormal
" ;
VAL_ 1535 BMS_HvBattTempSensorTemp_2T 255 "Invalid" 254 "Abnormal
" ;
VAL_ 1535 BMS_HvBattTempSensorTemp_3T 255 "Invalid" 254 "Abnormal
" ;
VAL_ 1535 BMS_HvBattTempSensorTemp_4T 255 "Invalid" 254 "Abnormal
" ;
VAL_ 1535 BMS_HvBattTempSensorTemp_5T 255 "Invalid" 254 "Abnormal
" ;
VAL_ 1535 BMS_HvBattTempSensorTemp_6T 255 "Invalid" 254 "Abnormal
" ;
VAL_ 1535 BMS_HvBattTempSensorTemp_7T 255 "Invalid" 254 "Abnormal
" ;
VAL_ 1535 BMS_HvBattTempSensorTemp_8T 255 "Invalid" 254 "Abnormal
" ;
VAL_ 1535 BMS_HvBattTempSensorTemp_9T 255 "Invalid" 254 "Abnormal
" ;
VAL_ 1535 BMS_HvBattTempSensorTemp_10T 255 "Invalid" 254 "Abnormal
" ;
VAL_ 1535 BMS_HvBattTempSensorTemp_11T 255 "Invalid" 254 "Abnormal
" ;
VAL_ 1535 BMS_HvBattTempSensorTemp_12T 255 "Invalid" 254 "Abnormal
" ;
VAL_ 1535 BMS_HvBattTempSensorTemp_13T 255 "Invalid" 254 "Abnormal
" ;
VAL_ 1535 BMS_HvBattTempSensorTemp_14T 255 "Invalid" 254 "Abnormal
" ;
VAL_ 1535 BMS_HvBattTempSensorTemp_15T 255 "Invalid" 254 "Abnormal
" ;
VAL_ 1535 BMS_HvBattTempSensorTemp_16T 255 "Invalid" 254 "Abnormal
" ;
VAL_ 1535 BMS_HvBattTempSensorTemp_17T 255 "Invalid" 254 "Abnormal
" ;
VAL_ 1535 BMS_HvBattTempSensorTemp_18T 255 "Invalid" 254 "Abnormal
" ;
VAL_ 1535 BMS_HvBattTempSensorTemp_19T 255 "Invalid" 254 "Abnormal
" ;
VAL_ 1535 BMS_HvBattTempSensorTemp_20T 255 "Invalid" 254 "Abnormal
" ;
VAL_ 1535 BMS_HvBattTempSensorTemp_21T 255 "Invalid" 254 "Abnormal
" ;
VAL_ 1535 BMS_HvBattTempSensorTemp_22T 255 "Invalid" 254 "Abnormal
" ;
VAL_ 1535 BMS_HvBattTempSensorTemp_23T 255 "Invalid" 254 "Abnormal
" ;
VAL_ 1535 BMS_HvBattTempSensorTemp_24T 255 "Invalid" 254 "Abnormal
" ;
VAL_ 1535 BMS_HvBattTempSensorTemp_25T 255 "Invalid" 254 "Abnormal
" ;
VAL_ 1535 BMS_HvBattTempSensorTemp_26T 255 "Invalid" 254 "Abnormal
" ;
VAL_ 1535 BMS_HvBattTempSensorTemp_27T 255 "Invalid" 254 "Abnormal
" ;
VAL_ 1535 BMS_HvBattTempSensorTemp_28T 255 "Invalid" 254 "Abnormal
" ;
VAL_ 1535 BMS_HvBattTempSensorTemp_29T 255 "Invalid" 254 "Abnormal
" ;
VAL_ 1535 BMS_HvBattTempSensorTemp_30T 255 "Invalid" 254 "Abnormal
" ;
VAL_ 1535 BMS_HvBattTempSensorTemp_31T 255 "Invalid" 254 "Abnormal
" ;
VAL_ 1535 BMS_HvBattTempSensorTemp_32T 255 "Invalid" 254 "Abnormal
" ;
VAL_ 1535 BMS_HvBattTempSensorTemp_33T 255 "Invalid" 254 "Abnormal
" ;
VAL_ 1535 BMS_HvBattTempSensorTemp_34T 255 "Invalid" 254 "Abnormal
" ;
VAL_ 1535 BMS_HvBattTempSensorTemp_35T 255 "Invalid" 254 "Abnormal
" ;
VAL_ 1535 BMS_HvBattTempSensorTemp_36T 255 "Invalid" 254 "Abnormal
" ;
VAL_ 1535 BMS_HvBattTempSensorTemp_37T 255 "Invalid" 254 "Abnormal
" ;
VAL_ 1535 BMS_HvBattTempSensorTemp_38T 255 "Invalid" 254 "Abnormal
" ;
VAL_ 1535 BMS_HvBattTempSensorTemp_39T 255 "Invalid" 254 "Abnormal
" ;
VAL_ 1535 BMS_HvBattTempSensorTemp_40T 255 "Invalid" 254 "Abnormal
" ;
VAL_ 1535 BMS_HvBattTempSensorTemp_41T 255 "Invalid" 254 "Abnormal
" ;
VAL_ 1535 BMS_HvBattTempSensorTemp_42T 255 "Invalid" 254 "Abnormal
" ;
VAL_ 1535 BMS_HvBattTempSensorTemp_43T 255 "Invalid" 254 "Abnormal
" ;
VAL_ 1535 BMS_HvBattTempSensorTemp_44T 255 "Invalid" 254 "Abnormal
" ;
VAL_ 1535 BMS_HvBattTempSensorTemp_45T 255 "Invalid" 254 "Abnormal
" ;
VAL_ 1535 BMS_HvBattTempSensorTemp_46T 255 "Invalid" 254 "Abnormal
" ;
VAL_ 1535 BMS_HvBattTempSensorTemp_47T 255 "Invalid" 254 "Abnormal
" ;
VAL_ 1535 BMS_HvBattTempSensorTemp_48T 255 "Invalid" 254 "Abnormal
" ;
VAL_ 1535 BMS_BattTempSensorStartFrameNum 255 "Invalid" 254 "Abnormal
" ;
VAL_ 1535 BMS_HvBattTempSensorFrameTNum 63 "Invalid" 62 "Abnormal
" ;
VAL_ 1224 BMS_HvBattCellVoltMax_Num 255 "Invalid" 254 "Abnormal
" ;
VAL_ 1224 BMS_HvBattCellVoltMax 65535 "Invalid" 65534 "Abnormal
" ;
VAL_ 1224 BMS_HvBattCellVoltMin_Num 255 "Invalid" 254 "Abnormal
" ;
VAL_ 1224 BMS_HvBattCellVoltMin 65535 "Invalid" 65534 "Abnormal
" ;
VAL_ 1224 BMS_Chg_Sts 15 "Invalid" 14 "Abnomal      " 4 "charge complete" 3 "no charge                                                                                                                            " 2 "Driving charge                                                                                                                                                                                                                    " 1 "Parking chagre  " ;
VAL_ 1230 BMS_HvBattCellU_1V 65535 "Invalid" 65534 "Abnormal
" ;
VAL_ 1230 BMS_HvBattCellU_2V 65535 "Invalid" 65534 "Abnormal
" ;
VAL_ 1230 BMS_HvBattCellU_3V 65535 "Invalid" 65534 "Abnormal
" ;
VAL_ 1230 BMS_HvBattCellU_4V 65535 "Invalid" 65534 "Abnormal
" ;
VAL_ 1230 BMS_HvBattCellU_5V 65535 "Invalid" 65534 "Abnormal
" ;
VAL_ 1230 BMS_HvBattCellU_6V 65535 "Invalid" 65534 "Abnormal
" ;
VAL_ 1230 BMS_HvBattCellU_7V 65535 "Invalid" 65534 "Abnormal
" ;
VAL_ 1230 BMS_HvBattCellU_8V 65535 "Invalid" 65534 "Abnormal
" ;
VAL_ 1230 BMS_HvBattCellU_9V 65535 "Invalid" 65534 "Abnormal
" ;
VAL_ 1230 BMS_HvBattCellU_10V 65535 "Invalid" 65534 "Abnormal
" ;
VAL_ 1230 BMS_HvBattCellU_11V 65535 "Invalid" 65534 "Abnormal
" ;
VAL_ 1230 BMS_HvBattCellU_12V 65535 "Invalid" 65534 "Abnormal
" ;
VAL_ 1230 BMS_HvBattCellU_13V 65535 "Invalid" 65534 "Abnormal
" ;
VAL_ 1230 BMS_HvBattCellU_14V 65535 "Invalid" 65534 "Abnormal
" ;
VAL_ 1230 BMS_HvBattCellU_15V 65535 "Invalid" 65534 "Abnormal
" ;
VAL_ 1230 BMS_HvBattCellU_16V 65535 "Invalid" 65534 "Abnormal
" ;
VAL_ 1230 BMS_HvBattCellU_17V 65535 "Invalid" 65534 "Abnormal
" ;
VAL_ 1230 BMS_HvBattCellU_18V 65535 "Invalid" 65534 "Abnormal
" ;
VAL_ 1230 BMS_HvBattCellU_19V 65535 "Invalid" 65534 "Abnormal
" ;
VAL_ 1230 BMS_HvBattCellU_20V 65535 "Invalid" 65534 "Abnormal
" ;
VAL_ 1230 BMS_HvBattCellU_21V 65535 "Invalid" 65534 "Abnormal
" ;
VAL_ 1230 BMS_HvBattCellU_22V 65535 "Invalid" 65534 "Abnormal
" ;
VAL_ 1230 BMS_HvBattCellU_23V 65535 "Invalid" 65534 "Abnormal
" ;
VAL_ 1230 BMS_HvBattCellU_24V 65535 "Invalid" 65534 "Abnormal
" ;
VAL_ 1230 BMS_HvBattCellU_25V 65535 "Invalid" 65534 "Abnormal
" ;
VAL_ 1230 BMS_HvBattCellU_26V 65535 "Invalid" 65534 "Abnormal
" ;
VAL_ 1230 BMS_HvBattCellU_27V 65535 "Invalid" 65534 "Abnormal
" ;
VAL_ 1230 BMS_HvBattCellU_28V 65535 "Invalid" 65534 "Abnormal
" ;
VAL_ 1230 BMS_HvBattCellU_29V 65535 "Invalid" 65534 "Abnormal
" ;
VAL_ 1230 BMS_HvBattCellU_30V 65535 "Invalid" 65534 "Abnormal
" ;
VAL_ 1230 BMS_BattCellstartframeNum 65535 "Invalid" 65534 "Abnormal
" ;
VAL_ 1230 BMS_HvBattCellFrameTotalNum 255 "Invalid" 254 "Abnormal
" ;
VAL_ 1041 CRM_RecongnitionResult 3 "Invalid" 2 "Reserved" 1 "BMS can identify" 0 "BMS cannot recognize" ;
VAL_ 1041 BMS_InsulationPos 65535 "Invalid" 65534 "Initial Value" ;
VAL_ 1041 BMS_IsoPosVolt 1023 "Invalid" 1022 "Initial Value" ;
VAL_ 1041 BMS_IsoNegVolt 1023 "Invalid" 1022 "Initial Value" ;
VAL_ 1041 BMS_IsoPosSwtSts 1 "Connect" 0 "Disconnect" ;
VAL_ 1041 BMS_IsoNegSwtSts 1 "Connect" 0 "Disconnect" ;
VAL_ 1041 BCL_ChareMode 3 "Invalid" 2 "Constant current mode" 1 "Constant voltage charging" 0 "Reserved" ;
VAL_ 1041 BMS_BPSWakeupSt 1 "BPS awaken" 0 "Not awakened" ;
VAL_ 1041 BMS_AFEWakeupSt 1 "AFE awaken" 0 "Not awakened" ;
VAL_ 1041 BMS_NMWakeupSt 1 "NM awaken" 0 "Not awakened" ;
VAL_ 1041 BMS_CC2WakeupSt 1 "CC2 awaken" 0 "Not awakened" ;
VAL_ 1041 CCS_ChargeAllowed 1 "allow" 0 "Not allowed" ;
VAL_ 1041 BMS_ResetRsn 63 "Invalid" ;
VAL_ 1041 BMS_HVPwrOnFailRsn 63 "Invalid" ;
VAL_ 1041 BMS_AirPressure 65535 "Invalid" 65534 "Initial Value" ;
VAL_ 1041 BMS_AirPressureRate 255 "Invalid" 254 "Initial Value" ;
VAL_ 1041 BMS_BattTempRate 255 "Invalid" 254 "Initial Value" ;
VAL_ 1041 BMS_CellVoltSum 16383 "Invalid" 16382 "Initial Value" ;
VAL_ 1041 BMS_DchaCurrtShoTiMax 16383 "Invalid" 16382 "Initial Value" ;
VAL_ 1041 BMS_ChrgCurrtShoTiMax 16383 "Invalid" 16382 "Initial Value" ;
VAL_ 1041 BMS_DchaPwrLongTiMax 16383 "Invalid" 16382 "Initial Value" ;
VAL_ 1041 BMS_ChrgPwrLongTiMax 16383 "Invalid" 16382 "Initial Value" ;
VAL_ 1041 BMS_DchaCurrtLongTiMax 16383 "Invalid" 16382 "Initial Value" ;
VAL_ 1041 BMS_ChrgCurrtLongTiMax 16383 "Invalid" 16382 "Initial Value" ;
VAL_ 1041 BMS_DchaCurrtContnsMax 16383 "Invalid" 16382 "Initial Value" ;
VAL_ 1041 BMS_ChrgCurrtContnsMax 16383 "Invalid" 16382 "Initial Value" ;
VAL_ 1041 BRO_BMSChargeReady 3 "Invalid" 2 "Reserved" 1 "BMS is ready for charging" 0 "BMS not ready for charging" ;
VAL_ 1041 CRO_ChargeReady 3 "Invalid" 2 "Reserved" 1 "The charger is ready for charging" 0 "The charger is not ready for charging" ;
VAL_ 1041 BMS_BattChrgNeeded 3 "Reserved" 2 "Reserved" 1 "BattChgNeeded " 0 "BattChgNotNeeded " ;
VAL_ 1041 BMS_DcDisChgStatus 15 "Reserved" 14 "Reserved" 13 "Reserved" 12 "Reserved" 11 "Reserved" 10 "Reserved" 9 "Reserved" 8 "Fault" 7 "DisChgEnd" 6 "DisChg" 5 "K5K6Clsed" 4 "ReadyforIMD" 3 "Isoluation Check" 2 "Wait Isoluation" 1 "Standby" 0 "initial" ;
VAL_ 1041 BMS_DC_DisChrgCurr 4095 "Invalid" 4094 "Abnormal
" ;
VAL_ 1041 BMS_DC_DisChrgPower 4095 "Invalid" ;
VAL_ 1041 BMS_DC_DisChrgEngy 4095 "Invalid" ;
VAL_ 1041 BMS_DC_DisChrgRemainTi 2047 "Init" 2046 "SNA/Fault
" ;
VAL_ 1041 BMS_DC_DisChrgVolt 65535 "Invalid" 65534 "Abnormal
" ;
VAL_ 1041 BMS_QCCDetdtVoltage 65535 "Invalid" ;
VAL_ 1041 BMS_InsulationNeg 65535 "Invalid" 65534 "Initial Value" ;
VAL_ 1041 BMS_SOCE_EU 127 "Invalid" 126 "Initial Value" ;
VAL_ 281 BMS_ColdbootPwr 4095 "Invalid" ;
VAL_ 281 BMS_StateOfChargeCorrect 16383 "Invalid" ;
VAL_ 281 BMS_BusVoltage 16383 "Invalid" ;
VAL_ 1275 BMSH_PowerChangeSign 7 "Invalid" 6 "0KW" 5 "limpPower" 4 "30sMAP" 3 "10schangeto30s" 2 "10sPowerMAP" 1 "5schangeto10s" 0 "5sPowerMAP" ;
VAL_ 1275 BMSH_PackInstantOutPower 4095 "Invalid" ;
VAL_ 1275 BMSH_PackInstantRecoveryPower 4095 "Invalid" ;
VAL_ 1275 BMS_SOCCalAlarm 3 "Reserved" 2 "Reserved" 1 "Alarm " 0 "Normal " ;
VAL_ 1275 BMS_PosInsulationSt 7 "Invalid" 3 "HWFault" 2 "Fault" 1 "Normal" 0 "Unknow" ;
VAL_ 1275 BMS_NegInsulationSt 7 "Invalid" 3 "HWFault" 2 "Fault" 1 "Normal" 0 "Unknow" ;
VAL_ 1275 BMSH_NegInsulationResis 65535 "Invalid" ;
VAL_ 1275 BMSH_PosInsulationResis 65535 "Invalid" ;
VAL_ 1275 CML_OutputVoltageMax 65535 "Invalid" ;
VAL_ 1275 CML_OutputVoltageMin 65535 "Invalid" ;
VAL_ 1275 CML_OutputCurentMax 65535 "Invalid" ;
VAL_ 1275 CML_OutputCurentMin 65535 "Invalid" ;
VAL_ 1275 BCL_VoltageRequire 65535 "Invalid" ;
VAL_ 1275 BCL_CurrentRequire 65535 "Invalid" ;
VAL_ 1275 CCS_OutputVoltage 65535 "Invalid" ;
VAL_ 1275 CCS_OutputCurent 65535 "Invalid" ;
VAL_ 1127 DCDC_HvVolt 65535 "Invalid" ;
VAL_ 1127 DCDC_HVCurr 65535 "Invalid" ;
VAL_ 1127 DCDC_LvSideCurr 4095 "Invalid" ;
VAL_ 1127 DCDC_LvSideVolt 2047 "Invalid" ;
VAL_ 1127 DCDC_FaultLevelSts 7 "Reserved" 6 "Reserved                " 5 "Reserved                  " 4 "Lever4 fault(Jetour)" 3 "Lever3 fault" 2 "Lever2 fault" 1 "Lever1 fault" 0 "No fault" ;
VAL_ 1127 DCDC_EnableSts 1 "Enable" 0 "Disable                                                                      " ;
VAL_ 1127 DCDC_OverTemp 1 "Fault" 0 "No fault                                                                  " ;
VAL_ 1127 DCDC_LvSideCurrMax 4095 "Invalid" ;
VAL_ 1182 OBC_ChgCurr 65535 "Invalid" ;
VAL_ 1182 OBC_ChgVolt 65535 "Invalid" ;
VAL_ 1182 OBC_MaxOutputPower 255 "Invalid" ;
VAL_ 1182 OBC_CP_DutyCycleValue 255 "Invalid" ;
VAL_ 1182 CDU_Coolanttemp 255 "Invalid" ;
VAL_ 1182 OBC_ChgInterfaceTemp 255 "Invalid" ;
VAL_ 1182 OBC_MaxDisOutPower 255 "Invalid" ;
VAL_ 1182 OBC_CPMaxVolt 255 "Invalid" ;
VAL_ 1182 OBC_ChrgrInputCurr1 1023 "reserved" 1022 "reserved" 1021 "reserved" 1020 "reserved" 1019 "reserved" 1018 "reserved" 1017 "reserved" 1016 "reserved" 1015 "reserved" 1014 "reserved" 1013 "reserved" 1012 "reserved" 1011 "reserved" 1010 "reserved" 1009 "reserved" 1008 "reserved" 1007 "reserved" 1006 "reserved" 1005 "reserved" 1004 "reserved" 1003 "reserved" 1002 "reserved" 1001 "reserved" 1000 "Valid Values" 999 "Valid Values" 998 "Valid Values" 997 "Valid Values" 996 "Valid Values" 995 "Valid Values" 994 "Valid Values" 993 "Valid Values" 992 "Valid Values" 991 "Valid Values" 990 "Valid Values" 989 "Valid Values" 988 "Valid Values" 987 "Valid Values" 986 "Valid Values" 985 "Valid Values" 984 "Valid Values" 983 "Valid Values" 982 "Valid Values" 981 "Valid Values" 980 "Valid Values" 979 "Valid Values" 978 "Valid Values" 977 "Valid Values" 976 "Valid Values" 975 "Valid Values" 974 "Valid Values" 973 "Valid Values" 972 "Valid Values" 971 "Valid Values" 970 "Valid Values" 969 "Valid Values" 968 "Valid Values" 967 "Valid Values" 966 "Valid Values" 965 "Valid Values" 964 "Valid Values" 963 "Valid Values" 962 "Valid Values" 961 "Valid Values" 960 "Valid Values" 959 "Valid Values" 958 "Valid Values" 957 "Valid Values" 956 "Valid Values" 955 "Valid Values" 954 "Valid Values" 953 "Valid Values" 952 "Valid Values" 951 "Valid Values" 950 "Valid Values" 949 "Valid Values" 948 "Valid Values" 947 "Valid Values" 946 "Valid Values" 945 "Valid Values" 944 "Valid Values" 943 "Valid Values" 942 "Valid Values" 941 "Valid Values" 940 "Valid Values" 939 "Valid Values" 938 "Valid Values" 937 "Valid Values" 936 "Valid Values" 935 "Valid Values" 934 "Valid Values" 933 "Valid Values" 932 "Valid Values" 931 "Valid Values" 930 "Valid Values" 929 "Valid Values" 928 "Valid Values" 927 "Valid Values" 926 "Valid Values" 925 "Valid Values" 924 "Valid Values" 923 "Valid Values" 922 "Valid Values" 921 "Valid Values" 920 "Valid Values" 919 "Valid Values" 918 "Valid Values" 917 "Valid Values" 916 "Valid Values" 915 "Valid Values" 914 "Valid Values" 913 "Valid Values" 912 "Valid Values" 911 "Valid Values" 910 "Valid Values" 909 "Valid Values" 908 "Valid Values" 907 "Valid Values" 906 "Valid Values" 905 "Valid Values" 904 "Valid Values" 903 "Valid Values" 902 "Valid Values" 901 "Valid Values" 900 "Valid Values" 899 "Valid Values" 898 "Valid Values" 897 "Valid Values" 896 "Valid Values" 895 "Valid Values" 894 "Valid Values" 893 "Valid Values" 892 "Valid Values" 891 "Valid Values" 890 "Valid Values" 889 "Valid Values" 888 "Valid Values" 887 "Valid Values" 886 "Valid Values" 885 "Valid Values" 884 "Valid Values" 883 "Valid Values" 882 "Valid Values" 881 "Valid Values" 880 "Valid Values" 879 "Valid Values" 878 "Valid Values" 877 "Valid Values" 876 "Valid Values" 875 "Valid Values" 874 "Valid Values" 873 "Valid Values" 872 "Valid Values" 871 "Valid Values" 870 "Valid Values" 869 "Valid Values" 868 "Valid Values" 867 "Valid Values" 866 "Valid Values" 865 "Valid Values" 864 "Valid Values" 863 "Valid Values" 862 "Valid Values" 861 "Valid Values" 860 "Valid Values" 859 "Valid Values" 858 "Valid Values" 857 "Valid Values" 856 "Valid Values" 855 "Valid Values" 854 "Valid Values" 853 "Valid Values" 852 "Valid Values" 851 "Valid Values" 850 "Valid Values" 849 "Valid Values" 848 "Valid Values" 847 "Valid Values" 846 "Valid Values" 845 "Valid Values" 844 "Valid Values" 843 "Valid Values" 842 "Valid Values" 841 "Valid Values" 840 "Valid Values" 839 "Valid Values" 838 "Valid Values" 837 "Valid Values" 836 "Valid Values" 835 "Valid Values" 834 "Valid Values" 833 "Valid Values" 832 "Valid Values" 831 "Valid Values" 830 "Valid Values" 829 "Valid Values" 828 "Valid Values" 827 "Valid Values" 826 "Valid Values" 825 "Valid Values" 824 "Valid Values" 823 "Valid Values" 822 "Valid Values" 821 "Valid Values" 820 "Valid Values" 819 "Valid Values" 818 "Valid Values" 817 "Valid Values" 816 "Valid Values" 815 "Valid Values" 814 "Valid Values" 813 "Valid Values" 812 "Valid Values" 811 "Valid Values" 810 "Valid Values" 809 "Valid Values" 808 "Valid Values" 807 "Valid Values" 806 "Valid Values" 805 "Valid Values" 804 "Valid Values" 803 "Valid Values" 802 "Valid Values" 801 "Valid Values" 800 "Valid Values" 799 "Valid Values" 798 "Valid Values" 797 "Valid Values" 796 "Valid Values" 795 "Valid Values" 794 "Valid Values" 793 "Valid Values" 792 "Valid Values" 791 "Valid Values" 790 "Valid Values" 789 "Valid Values" 788 "Valid Values" 787 "Valid Values" 786 "Valid Values" 785 "Valid Values" 784 "Valid Values" 783 "Valid Values" 782 "Valid Values" 781 "Valid Values" 780 "Valid Values" 779 "Valid Values" 778 "Valid Values" 777 "Valid Values" 776 "Valid Values" 775 "Valid Values" 774 "Valid Values" 773 "Valid Values" 772 "Valid Values" 771 "Valid Values" 770 "Valid Values" 769 "Valid Values" 768 "Valid Values" 767 "Valid Values" 766 "Valid Values" 765 "Valid Values" 764 "Valid Values" 763 "Valid Values" 762 "Valid Values" 761 "Valid Values" 760 "Valid Values" 759 "Valid Values" 758 "Valid Values" 757 "Valid Values" 756 "Valid Values" 755 "Valid Values" 754 "Valid Values" 753 "Valid Values" 752 "Valid Values" 751 "Valid Values" 750 "Valid Values" 749 "Valid Values" 748 "Valid Values" 747 "Valid Values" 746 "Valid Values" 745 "Valid Values" 744 "Valid Values" 743 "Valid Values" 742 "Valid Values" 741 "Valid Values" 740 "Valid Values" 739 "Valid Values" 738 "Valid Values" 737 "Valid Values" 736 "Valid Values" 735 "Valid Values" 734 "Valid Values" 733 "Valid Values" 732 "Valid Values" 731 "Valid Values" 730 "Valid Values" 729 "Valid Values" 728 "Valid Values" 727 "Valid Values" 726 "Valid Values" 725 "Valid Values" 724 "Valid Values" 723 "Valid Values" 722 "Valid Values" 721 "Valid Values" 720 "Valid Values" 719 "Valid Values" 718 "Valid Values" 717 "Valid Values" 716 "Valid Values" 715 "Valid Values" 714 "Valid Values" 713 "Valid Values" 712 "Valid Values" 711 "Valid Values" 710 "Valid Values" 709 "Valid Values" 708 "Valid Values" 707 "Valid Values" 706 "Valid Values" 705 "Valid Values" 704 "Valid Values" 703 "Valid Values" 702 "Valid Values" 701 "Valid Values" 700 "Valid Values" 699 "Valid Values" 698 "Valid Values" 697 "Valid Values" 696 "Valid Values" 695 "Valid Values" 694 "Valid Values" 693 "Valid Values" 692 "Valid Values" 691 "Valid Values" 690 "Valid Values" 689 "Valid Values" 688 "Valid Values" 687 "Valid Values" 686 "Valid Values" 685 "Valid Values" 684 "Valid Values" 683 "Valid Values" 682 "Valid Values" 681 "Valid Values" 680 "Valid Values" 679 "Valid Values" 678 "Valid Values" 677 "Valid Values" 676 "Valid Values" 675 "Valid Values" 674 "Valid Values" 673 "Valid Values" 672 "Valid Values" 671 "Valid Values" 670 "Valid Values" 669 "Valid Values" 668 "Valid Values" 667 "Valid Values" 666 "Valid Values" 665 "Valid Values" 664 "Valid Values" 663 "Valid Values" 662 "Valid Values" 661 "Valid Values" 660 "Valid Values" 659 "Valid Values" 658 "Valid Values" 657 "Valid Values" 656 "Valid Values" 655 "Valid Values" 654 "Valid Values" 653 "Valid Values" 652 "Valid Values" 651 "Valid Values" 650 "Valid Values" 649 "Valid Values" 648 "Valid Values" 647 "Valid Values" 646 "Valid Values" 645 "Valid Values" 644 "Valid Values" 643 "Valid Values" 642 "Valid Values" 641 "Valid Values" 640 "Valid Values" 639 "Valid Values" 638 "Valid Values" 637 "Valid Values" 636 "Valid Values" 635 "Valid Values" 634 "Valid Values" 633 "Valid Values" 632 "Valid Values" 631 "Valid Values" 630 "Valid Values" 629 "Valid Values" 628 "Valid Values" 627 "Valid Values" 626 "Valid Values" 625 "Valid Values" 624 "Valid Values" 623 "Valid Values" 622 "Valid Values" 621 "Valid Values" 620 "Valid Values" 619 "Valid Values" 618 "Valid Values" 617 "Valid Values" 616 "Valid Values" 615 "Valid Values" 614 "Valid Values" 613 "Valid Values" 612 "Valid Values" 611 "Valid Values" 610 "Valid Values" 609 "Valid Values" 608 "Valid Values" 607 "Valid Values" 606 "Valid Values" 605 "Valid Values" 604 "Valid Values" 603 "Valid Values" 602 "Valid Values" 601 "Valid Values" 600 "Valid Values" 599 "Valid Values" 598 "Valid Values" 597 "Valid Values" 596 "Valid Values" 595 "Valid Values" 594 "Valid Values" 593 "Valid Values" 592 "Valid Values" 591 "Valid Values" 590 "Valid Values" 589 "Valid Values" 588 "Valid Values" 587 "Valid Values" 586 "Valid Values" 585 "Valid Values" 584 "Valid Values" 583 "Valid Values" 582 "Valid Values" 581 "Valid Values" 580 "Valid Values" 579 "Valid Values" 578 "Valid Values" 577 "Valid Values" 576 "Valid Values" 575 "Valid Values" 574 "Valid Values" 573 "Valid Values" 572 "Valid Values" 571 "Valid Values" 570 "Valid Values" 569 "Valid Values" 568 "Valid Values" 567 "Valid Values" 566 "Valid Values" 565 "Valid Values" 564 "Valid Values" 563 "Valid Values" 562 "Valid Values" 561 "Valid Values" 560 "Valid Values" 559 "Valid Values" 558 "Valid Values" 557 "Valid Values" 556 "Valid Values" 555 "Valid Values" 554 "Valid Values" 553 "Valid Values" 552 "Valid Values" 551 "Valid Values" 550 "Valid Values" 549 "Valid Values" 548 "Valid Values" 547 "Valid Values" 546 "Valid Values" 545 "Valid Values" 544 "Valid Values" 543 "Valid Values" 542 "Valid Values" 541 "Valid Values" 540 "Valid Values" 539 "Valid Values" 538 "Valid Values" 537 "Valid Values" 536 "Valid Values" 535 "Valid Values" 534 "Valid Values" 533 "Valid Values" 532 "Valid Values" 531 "Valid Values" 530 "Valid Values" 529 "Valid Values" 528 "Valid Values" 527 "Valid Values" 526 "Valid Values" 525 "Valid Values" 524 "Valid Values" 523 "Valid Values" 522 "Valid Values" 521 "Valid Values" 520 "Valid Values" 519 "Valid Values" 518 "Valid Values" 517 "Valid Values" 516 "Valid Values" 515 "Valid Values" 514 "Valid Values" 513 "Valid Values" 512 "Valid Values" 511 "Valid Values" 510 "Valid Values" 509 "Valid Values" 508 "Valid Values" 507 "Valid Values" 506 "Valid Values" 505 "Valid Values" 504 "Valid Values" 503 "Valid Values" 502 "Valid Values" 501 "Valid Values" 500 "Valid Values" 499 "Valid Values" 498 "Valid Values" 497 "Valid Values" 496 "Valid Values" 495 "Valid Values" 494 "Valid Values" 493 "Valid Values" 492 "Valid Values" 491 "Valid Values" 490 "Valid Values" 489 "Valid Values" 488 "Valid Values" 487 "Valid Values" 486 "Valid Values" 485 "Valid Values" 484 "Valid Values" 483 "Valid Values" 482 "Valid Values" 481 "Valid Values" 480 "Valid Values" 479 "Valid Values" 478 "Valid Values" 477 "Valid Values" 476 "Valid Values" 475 "Valid Values" 474 "Valid Values" 473 "Valid Values" 472 "Valid Values" 471 "Valid Values" 470 "Valid Values" 469 "Valid Values" 468 "Valid Values" 467 "Valid Values" 466 "Valid Values" 465 "Valid Values" 464 "Valid Values" 463 "Valid Values" 462 "Valid Values" 461 "Valid Values" 460 "Valid Values" 459 "Valid Values" 458 "Valid Values" 457 "Valid Values" 456 "Valid Values" 455 "Valid Values" 454 "Valid Values" 453 "Valid Values" 452 "Valid Values" 451 "Valid Values" 450 "Valid Values" 449 "Valid Values" 448 "Valid Values" 447 "Valid Values" 446 "Valid Values" 445 "Valid Values" 444 "Valid Values" 443 "Valid Values" 442 "Valid Values" 441 "Valid Values" 440 "Valid Values" 439 "Valid Values" 438 "Valid Values" 437 "Valid Values" 436 "Valid Values" 435 "Valid Values" 434 "Valid Values" 433 "Valid Values" 432 "Valid Values" 431 "Valid Values" 430 "Valid Values" 429 "Valid Values" 428 "Valid Values" 427 "Valid Values" 426 "Valid Values" 425 "Valid Values" 424 "Valid Values" 423 "Valid Values" 422 "Valid Values" 421 "Valid Values" 420 "Valid Values" 419 "Valid Values" 418 "Valid Values" 417 "Valid Values" 416 "Valid Values" 415 "Valid Values" 414 "Valid Values" 413 "Valid Values" 412 "Valid Values" 411 "Valid Values" 410 "Valid Values" 409 "Valid Values" 408 "Valid Values" 407 "Valid Values" 406 "Valid Values" 405 "Valid Values" 404 "Valid Values" 403 "Valid Values" 402 "Valid Values" 401 "Valid Values" 400 "Valid Values" 399 "Valid Values" 398 "Valid Values" 397 "Valid Values" 396 "Valid Values" 395 "Valid Values" 394 "Valid Values" 393 "Valid Values" 392 "Valid Values" 391 "Valid Values" 390 "Valid Values" 389 "Valid Values" 388 "Valid Values" 387 "Valid Values" 386 "Valid Values" 385 "Valid Values" 384 "Valid Values" 383 "Valid Values" 382 "Valid Values" 381 "Valid Values" 380 "Valid Values" 379 "Valid Values" 378 "Valid Values" 377 "Valid Values" 376 "Valid Values" 375 "Valid Values" 374 "Valid Values" 373 "Valid Values" 372 "Valid Values" 371 "Valid Values" 370 "Valid Values" 369 "Valid Values" 368 "Valid Values" 367 "Valid Values" 366 "Valid Values" 365 "Valid Values" 364 "Valid Values" 363 "Valid Values" 362 "Valid Values" 361 "Valid Values" 360 "Valid Values" 359 "Valid Values" 358 "Valid Values" 357 "Valid Values" 356 "Valid Values" 355 "Valid Values" 354 "Valid Values" 353 "Valid Values" 352 "Valid Values" 351 "Valid Values" 350 "Valid Values" 349 "Valid Values" 348 "Valid Values" 347 "Valid Values" 346 "Valid Values" 345 "Valid Values" 344 "Valid Values" 343 "Valid Values" 342 "Valid Values" 341 "Valid Values" 340 "Valid Values" 339 "Valid Values" 338 "Valid Values" 337 "Valid Values" 336 "Valid Values" 335 "Valid Values" 334 "Valid Values" 333 "Valid Values" 332 "Valid Values" 331 "Valid Values" 330 "Valid Values" 329 "Valid Values" 328 "Valid Values" 327 "Valid Values" 326 "Valid Values" 325 "Valid Values" 324 "Valid Values" 323 "Valid Values" 322 "Valid Values" 321 "Valid Values" 320 "Valid Values" 319 "Valid Values" 318 "Valid Values" 317 "Valid Values" 316 "Valid Values" 315 "Valid Values" 314 "Valid Values" 313 "Valid Values" 312 "Valid Values" 311 "Valid Values" 310 "Valid Values" 309 "Valid Values" 308 "Valid Values" 307 "Valid Values" 306 "Valid Values" 305 "Valid Values" 304 "Valid Values" 303 "Valid Values" 302 "Valid Values" 301 "Valid Values" 300 "Valid Values" 299 "Valid Values" 298 "Valid Values" 297 "Valid Values" 296 "Valid Values" 295 "Valid Values" 294 "Valid Values" 293 "Valid Values" 292 "Valid Values" 291 "Valid Values" 290 "Valid Values" 289 "Valid Values" 288 "Valid Values" 287 "Valid Values" 286 "Valid Values" 285 "Valid Values" 284 "Valid Values" 283 "Valid Values" 282 "Valid Values" 281 "Valid Values" 280 "Valid Values" 279 "Valid Values" 278 "Valid Values" 277 "Valid Values" 276 "Valid Values" 275 "Valid Values" 274 "Valid Values" 273 "Valid Values" 272 "Valid Values" 271 "Valid Values" 270 "Valid Values" 269 "Valid Values" 268 "Valid Values" 267 "Valid Values" 266 "Valid Values" 265 "Valid Values" 264 "Valid Values" 263 "Valid Values" 262 "Valid Values" 261 "Valid Values" 260 "Valid Values" 259 "Valid Values" 258 "Valid Values" 257 "Valid Values" 256 "Valid Values" 255 "Valid Values" 254 "Valid Values" 253 "Valid Values" 252 "Valid Values" 251 "Valid Values" 250 "Valid Values" 249 "Valid Values" 248 "Valid Values" 247 "Valid Values" 246 "Valid Values" 245 "Valid Values" 244 "Valid Values" 243 "Valid Values" 242 "Valid Values" 241 "Valid Values" 240 "Valid Values" 239 "Valid Values" 238 "Valid Values" 237 "Valid Values" 236 "Valid Values" 235 "Valid Values" 234 "Valid Values" 233 "Valid Values" 232 "Valid Values" 231 "Valid Values" 230 "Valid Values" 229 "Valid Values" 228 "Valid Values" 227 "Valid Values" 226 "Valid Values" 225 "Valid Values" 224 "Valid Values" 223 "Valid Values" 222 "Valid Values" 221 "Valid Values" 220 "Valid Values" 219 "Valid Values" 218 "Valid Values" 217 "Valid Values" 216 "Valid Values" 215 "Valid Values" 214 "Valid Values" 213 "Valid Values" 212 "Valid Values" 211 "Valid Values" 210 "Valid Values" 209 "Valid Values" 208 "Valid Values" 207 "Valid Values" 206 "Valid Values" 205 "Valid Values" 204 "Valid Values" 203 "Valid Values" 202 "Valid Values" 201 "Valid Values" 200 "Valid Values" 199 "Valid Values" 198 "Valid Values" 197 "Valid Values" 196 "Valid Values" 195 "Valid Values" 194 "Valid Values" 193 "Valid Values" 192 "Valid Values" 191 "Valid Values" 190 "Valid Values" 189 "Valid Values" 188 "Valid Values" 187 "Valid Values" 186 "Valid Values" 185 "Valid Values" 184 "Valid Values" 183 "Valid Values" 182 "Valid Values" 181 "Valid Values" 180 "Valid Values" 179 "Valid Values" 178 "Valid Values" 177 "Valid Values" 176 "Valid Values" 175 "Valid Values" 174 "Valid Values" 173 "Valid Values" 172 "Valid Values" 171 "Valid Values" 170 "Valid Values" 169 "Valid Values" 168 "Valid Values" 167 "Valid Values" 166 "Valid Values" 165 "Valid Values" 164 "Valid Values" 163 "Valid Values" 162 "Valid Values" 161 "Valid Values" 160 "Valid Values" 159 "Valid Values" 158 "Valid Values" 157 "Valid Values" 156 "Valid Values" 155 "Valid Values" 154 "Valid Values" 153 "Valid Values" 152 "Valid Values" 151 "Valid Values" 150 "Valid Values" 149 "Valid Values" 148 "Valid Values" 147 "Valid Values" 146 "Valid Values" 145 "Valid Values" 144 "Valid Values" 143 "Valid Values" 142 "Valid Values" 141 "Valid Values" 140 "Valid Values" 139 "Valid Values" 138 "Valid Values" 137 "Valid Values" 136 "Valid Values" 135 "Valid Values" 134 "Valid Values" 133 "Valid Values" 132 "Valid Values" 131 "Valid Values" 130 "Valid Values" 129 "Valid Values" 128 "Valid Values" 127 "Valid Values" 126 "Valid Values" 125 "Valid Values" 124 "Valid Values" 123 "Valid Values" 122 "Valid Values" 121 "Valid Values" 120 "Valid Values" 119 "Valid Values" 118 "Valid Values" 117 "Valid Values" 116 "Valid Values" 115 "Valid Values" 114 "Valid Values" 113 "Valid Values" 112 "Valid Values" 111 "Valid Values" 110 "Valid Values" 109 "Valid Values" 108 "Valid Values" 107 "Valid Values" 106 "Valid Values" 105 "Valid Values" 104 "Valid Values" 103 "Valid Values" 102 "Valid Values" 101 "Valid Values" 100 "Valid Values" 99 "Valid Values" 98 "Valid Values" 97 "Valid Values" 96 "Valid Values" 95 "Valid Values" 94 "Valid Values" 93 "Valid Values" 92 "Valid Values" 91 "Valid Values" 90 "Valid Values" 89 "Valid Values" 88 "Valid Values" 87 "Valid Values" 86 "Valid Values" 85 "Valid Values" 84 "Valid Values" 83 "Valid Values" 82 "Valid Values" 81 "Valid Values" 80 "Valid Values" 79 "Valid Values" 78 "Valid Values" 77 "Valid Values" 76 "Valid Values" 75 "Valid Values" 74 "Valid Values" 73 "Valid Values" 72 "Valid Values" 71 "Valid Values" 70 "Valid Values" 69 "Valid Values" 68 "Valid Values" 67 "Valid Values" 66 "Valid Values" 65 "Valid Values" 64 "Valid Values" 63 "Valid Values" 62 "Valid Values" 61 "Valid Values" 60 "Valid Values" 59 "Valid Values" 58 "Valid Values" 57 "Valid Values" 56 "Valid Values" 55 "Valid Values" 54 "Valid Values" 53 "Valid Values" 52 "Valid Values" 51 "Valid Values" 50 "Valid Values" 49 "Valid Values" 48 "Valid Values" 47 "Valid Values" 46 "Valid Values" 45 "Valid Values" 44 "Valid Values" 43 "Valid Values" 42 "Valid Values" 41 "Valid Values" 40 "Valid Values" 39 "Valid Values" 38 "Valid Values" 37 "Valid Values" 36 "Valid Values" 35 "Valid Values" 34 "Valid Values" 33 "Valid Values" 32 "Valid Values" 31 "Valid Values" 30 "Valid Values" 29 "Valid Values" 28 "Valid Values" 27 "Valid Values" 26 "Valid Values" 25 "Valid Values" 24 "Valid Values" 23 "Valid Values" 22 "Valid Values" 21 "Valid Values" 20 "Valid Values" 19 "Valid Values" 18 "Valid Values" 17 "Valid Values" 16 "Valid Values" 15 "Valid Values" 14 "Valid Values" 13 "Valid Values" 12 "Valid Values" 11 "Valid Values" 10 "Valid Values" 9 "Valid Values" 8 "Valid Values" 7 "Valid Values" 6 "Valid Values" 5 "Valid Values" 4 "Valid Values" 3 "Valid Values" 2 "Valid Values" 1 "Valid Values" 0 "Valid Values" ;
VAL_ 1182 OBC_ChrgrInputCurr2 1023 "reserved" 1022 "reserved" 1021 "reserved" 1020 "reserved" 1019 "reserved" 1018 "reserved" 1017 "reserved" 1016 "reserved" 1015 "reserved" 1014 "reserved" 1013 "reserved" 1012 "reserved" 1011 "reserved" 1010 "reserved" 1009 "reserved" 1008 "reserved" 1007 "reserved" 1006 "reserved" 1005 "reserved" 1004 "reserved" 1003 "reserved" 1002 "reserved" 1001 "reserved" 1000 "Valid Values" 999 "Valid Values" 998 "Valid Values" 997 "Valid Values" 996 "Valid Values" 995 "Valid Values" 994 "Valid Values" 993 "Valid Values" 992 "Valid Values" 991 "Valid Values" 990 "Valid Values" 989 "Valid Values" 988 "Valid Values" 987 "Valid Values" 986 "Valid Values" 985 "Valid Values" 984 "Valid Values" 983 "Valid Values" 982 "Valid Values" 981 "Valid Values" 980 "Valid Values" 979 "Valid Values" 978 "Valid Values" 977 "Valid Values" 976 "Valid Values" 975 "Valid Values" 974 "Valid Values" 973 "Valid Values" 972 "Valid Values" 971 "Valid Values" 970 "Valid Values" 969 "Valid Values" 968 "Valid Values" 967 "Valid Values" 966 "Valid Values" 965 "Valid Values" 964 "Valid Values" 963 "Valid Values" 962 "Valid Values" 961 "Valid Values" 960 "Valid Values" 959 "Valid Values" 958 "Valid Values" 957 "Valid Values" 956 "Valid Values" 955 "Valid Values" 954 "Valid Values" 953 "Valid Values" 952 "Valid Values" 951 "Valid Values" 950 "Valid Values" 949 "Valid Values" 948 "Valid Values" 947 "Valid Values" 946 "Valid Values" 945 "Valid Values" 944 "Valid Values" 943 "Valid Values" 942 "Valid Values" 941 "Valid Values" 940 "Valid Values" 939 "Valid Values" 938 "Valid Values" 937 "Valid Values" 936 "Valid Values" 935 "Valid Values" 934 "Valid Values" 933 "Valid Values" 932 "Valid Values" 931 "Valid Values" 930 "Valid Values" 929 "Valid Values" 928 "Valid Values" 927 "Valid Values" 926 "Valid Values" 925 "Valid Values" 924 "Valid Values" 923 "Valid Values" 922 "Valid Values" 921 "Valid Values" 920 "Valid Values" 919 "Valid Values" 918 "Valid Values" 917 "Valid Values" 916 "Valid Values" 915 "Valid Values" 914 "Valid Values" 913 "Valid Values" 912 "Valid Values" 911 "Valid Values" 910 "Valid Values" 909 "Valid Values" 908 "Valid Values" 907 "Valid Values" 906 "Valid Values" 905 "Valid Values" 904 "Valid Values" 903 "Valid Values" 902 "Valid Values" 901 "Valid Values" 900 "Valid Values" 899 "Valid Values" 898 "Valid Values" 897 "Valid Values" 896 "Valid Values" 895 "Valid Values" 894 "Valid Values" 893 "Valid Values" 892 "Valid Values" 891 "Valid Values" 890 "Valid Values" 889 "Valid Values" 888 "Valid Values" 887 "Valid Values" 886 "Valid Values" 885 "Valid Values" 884 "Valid Values" 883 "Valid Values" 882 "Valid Values" 881 "Valid Values" 880 "Valid Values" 879 "Valid Values" 878 "Valid Values" 877 "Valid Values" 876 "Valid Values" 875 "Valid Values" 874 "Valid Values" 873 "Valid Values" 872 "Valid Values" 871 "Valid Values" 870 "Valid Values" 869 "Valid Values" 868 "Valid Values" 867 "Valid Values" 866 "Valid Values" 865 "Valid Values" 864 "Valid Values" 863 "Valid Values" 862 "Valid Values" 861 "Valid Values" 860 "Valid Values" 859 "Valid Values" 858 "Valid Values" 857 "Valid Values" 856 "Valid Values" 855 "Valid Values" 854 "Valid Values" 853 "Valid Values" 852 "Valid Values" 851 "Valid Values" 850 "Valid Values" 849 "Valid Values" 848 "Valid Values" 847 "Valid Values" 846 "Valid Values" 845 "Valid Values" 844 "Valid Values" 843 "Valid Values" 842 "Valid Values" 841 "Valid Values" 840 "Valid Values" 839 "Valid Values" 838 "Valid Values" 837 "Valid Values" 836 "Valid Values" 835 "Valid Values" 834 "Valid Values" 833 "Valid Values" 832 "Valid Values" 831 "Valid Values" 830 "Valid Values" 829 "Valid Values" 828 "Valid Values" 827 "Valid Values" 826 "Valid Values" 825 "Valid Values" 824 "Valid Values" 823 "Valid Values" 822 "Valid Values" 821 "Valid Values" 820 "Valid Values" 819 "Valid Values" 818 "Valid Values" 817 "Valid Values" 816 "Valid Values" 815 "Valid Values" 814 "Valid Values" 813 "Valid Values" 812 "Valid Values" 811 "Valid Values" 810 "Valid Values" 809 "Valid Values" 808 "Valid Values" 807 "Valid Values" 806 "Valid Values" 805 "Valid Values" 804 "Valid Values" 803 "Valid Values" 802 "Valid Values" 801 "Valid Values" 800 "Valid Values" 799 "Valid Values" 798 "Valid Values" 797 "Valid Values" 796 "Valid Values" 795 "Valid Values" 794 "Valid Values" 793 "Valid Values" 792 "Valid Values" 791 "Valid Values" 790 "Valid Values" 789 "Valid Values" 788 "Valid Values" 787 "Valid Values" 786 "Valid Values" 785 "Valid Values" 784 "Valid Values" 783 "Valid Values" 782 "Valid Values" 781 "Valid Values" 780 "Valid Values" 779 "Valid Values" 778 "Valid Values" 777 "Valid Values" 776 "Valid Values" 775 "Valid Values" 774 "Valid Values" 773 "Valid Values" 772 "Valid Values" 771 "Valid Values" 770 "Valid Values" 769 "Valid Values" 768 "Valid Values" 767 "Valid Values" 766 "Valid Values" 765 "Valid Values" 764 "Valid Values" 763 "Valid Values" 762 "Valid Values" 761 "Valid Values" 760 "Valid Values" 759 "Valid Values" 758 "Valid Values" 757 "Valid Values" 756 "Valid Values" 755 "Valid Values" 754 "Valid Values" 753 "Valid Values" 752 "Valid Values" 751 "Valid Values" 750 "Valid Values" 749 "Valid Values" 748 "Valid Values" 747 "Valid Values" 746 "Valid Values" 745 "Valid Values" 744 "Valid Values" 743 "Valid Values" 742 "Valid Values" 741 "Valid Values" 740 "Valid Values" 739 "Valid Values" 738 "Valid Values" 737 "Valid Values" 736 "Valid Values" 735 "Valid Values" 734 "Valid Values" 733 "Valid Values" 732 "Valid Values" 731 "Valid Values" 730 "Valid Values" 729 "Valid Values" 728 "Valid Values" 727 "Valid Values" 726 "Valid Values" 725 "Valid Values" 724 "Valid Values" 723 "Valid Values" 722 "Valid Values" 721 "Valid Values" 720 "Valid Values" 719 "Valid Values" 718 "Valid Values" 717 "Valid Values" 716 "Valid Values" 715 "Valid Values" 714 "Valid Values" 713 "Valid Values" 712 "Valid Values" 711 "Valid Values" 710 "Valid Values" 709 "Valid Values" 708 "Valid Values" 707 "Valid Values" 706 "Valid Values" 705 "Valid Values" 704 "Valid Values" 703 "Valid Values" 702 "Valid Values" 701 "Valid Values" 700 "Valid Values" 699 "Valid Values" 698 "Valid Values" 697 "Valid Values" 696 "Valid Values" 695 "Valid Values" 694 "Valid Values" 693 "Valid Values" 692 "Valid Values" 691 "Valid Values" 690 "Valid Values" 689 "Valid Values" 688 "Valid Values" 687 "Valid Values" 686 "Valid Values" 685 "Valid Values" 684 "Valid Values" 683 "Valid Values" 682 "Valid Values" 681 "Valid Values" 680 "Valid Values" 679 "Valid Values" 678 "Valid Values" 677 "Valid Values" 676 "Valid Values" 675 "Valid Values" 674 "Valid Values" 673 "Valid Values" 672 "Valid Values" 671 "Valid Values" 670 "Valid Values" 669 "Valid Values" 668 "Valid Values" 667 "Valid Values" 666 "Valid Values" 665 "Valid Values" 664 "Valid Values" 663 "Valid Values" 662 "Valid Values" 661 "Valid Values" 660 "Valid Values" 659 "Valid Values" 658 "Valid Values" 657 "Valid Values" 656 "Valid Values" 655 "Valid Values" 654 "Valid Values" 653 "Valid Values" 652 "Valid Values" 651 "Valid Values" 650 "Valid Values" 649 "Valid Values" 648 "Valid Values" 647 "Valid Values" 646 "Valid Values" 645 "Valid Values" 644 "Valid Values" 643 "Valid Values" 642 "Valid Values" 641 "Valid Values" 640 "Valid Values" 639 "Valid Values" 638 "Valid Values" 637 "Valid Values" 636 "Valid Values" 635 "Valid Values" 634 "Valid Values" 633 "Valid Values" 632 "Valid Values" 631 "Valid Values" 630 "Valid Values" 629 "Valid Values" 628 "Valid Values" 627 "Valid Values" 626 "Valid Values" 625 "Valid Values" 624 "Valid Values" 623 "Valid Values" 622 "Valid Values" 621 "Valid Values" 620 "Valid Values" 619 "Valid Values" 618 "Valid Values" 617 "Valid Values" 616 "Valid Values" 615 "Valid Values" 614 "Valid Values" 613 "Valid Values" 612 "Valid Values" 611 "Valid Values" 610 "Valid Values" 609 "Valid Values" 608 "Valid Values" 607 "Valid Values" 606 "Valid Values" 605 "Valid Values" 604 "Valid Values" 603 "Valid Values" 602 "Valid Values" 601 "Valid Values" 600 "Valid Values" 599 "Valid Values" 598 "Valid Values" 597 "Valid Values" 596 "Valid Values" 595 "Valid Values" 594 "Valid Values" 593 "Valid Values" 592 "Valid Values" 591 "Valid Values" 590 "Valid Values" 589 "Valid Values" 588 "Valid Values" 587 "Valid Values" 586 "Valid Values" 585 "Valid Values" 584 "Valid Values" 583 "Valid Values" 582 "Valid Values" 581 "Valid Values" 580 "Valid Values" 579 "Valid Values" 578 "Valid Values" 577 "Valid Values" 576 "Valid Values" 575 "Valid Values" 574 "Valid Values" 573 "Valid Values" 572 "Valid Values" 571 "Valid Values" 570 "Valid Values" 569 "Valid Values" 568 "Valid Values" 567 "Valid Values" 566 "Valid Values" 565 "Valid Values" 564 "Valid Values" 563 "Valid Values" 562 "Valid Values" 561 "Valid Values" 560 "Valid Values" 559 "Valid Values" 558 "Valid Values" 557 "Valid Values" 556 "Valid Values" 555 "Valid Values" 554 "Valid Values" 553 "Valid Values" 552 "Valid Values" 551 "Valid Values" 550 "Valid Values" 549 "Valid Values" 548 "Valid Values" 547 "Valid Values" 546 "Valid Values" 545 "Valid Values" 544 "Valid Values" 543 "Valid Values" 542 "Valid Values" 541 "Valid Values" 540 "Valid Values" 539 "Valid Values" 538 "Valid Values" 537 "Valid Values" 536 "Valid Values" 535 "Valid Values" 534 "Valid Values" 533 "Valid Values" 532 "Valid Values" 531 "Valid Values" 530 "Valid Values" 529 "Valid Values" 528 "Valid Values" 527 "Valid Values" 526 "Valid Values" 525 "Valid Values" 524 "Valid Values" 523 "Valid Values" 522 "Valid Values" 521 "Valid Values" 520 "Valid Values" 519 "Valid Values" 518 "Valid Values" 517 "Valid Values" 516 "Valid Values" 515 "Valid Values" 514 "Valid Values" 513 "Valid Values" 512 "Valid Values" 511 "Valid Values" 510 "Valid Values" 509 "Valid Values" 508 "Valid Values" 507 "Valid Values" 506 "Valid Values" 505 "Valid Values" 504 "Valid Values" 503 "Valid Values" 502 "Valid Values" 501 "Valid Values" 500 "Valid Values" 499 "Valid Values" 498 "Valid Values" 497 "Valid Values" 496 "Valid Values" 495 "Valid Values" 494 "Valid Values" 493 "Valid Values" 492 "Valid Values" 491 "Valid Values" 490 "Valid Values" 489 "Valid Values" 488 "Valid Values" 487 "Valid Values" 486 "Valid Values" 485 "Valid Values" 484 "Valid Values" 483 "Valid Values" 482 "Valid Values" 481 "Valid Values" 480 "Valid Values" 479 "Valid Values" 478 "Valid Values" 477 "Valid Values" 476 "Valid Values" 475 "Valid Values" 474 "Valid Values" 473 "Valid Values" 472 "Valid Values" 471 "Valid Values" 470 "Valid Values" 469 "Valid Values" 468 "Valid Values" 467 "Valid Values" 466 "Valid Values" 465 "Valid Values" 464 "Valid Values" 463 "Valid Values" 462 "Valid Values" 461 "Valid Values" 460 "Valid Values" 459 "Valid Values" 458 "Valid Values" 457 "Valid Values" 456 "Valid Values" 455 "Valid Values" 454 "Valid Values" 453 "Valid Values" 452 "Valid Values" 451 "Valid Values" 450 "Valid Values" 449 "Valid Values" 448 "Valid Values" 447 "Valid Values" 446 "Valid Values" 445 "Valid Values" 444 "Valid Values" 443 "Valid Values" 442 "Valid Values" 441 "Valid Values" 440 "Valid Values" 439 "Valid Values" 438 "Valid Values" 437 "Valid Values" 436 "Valid Values" 435 "Valid Values" 434 "Valid Values" 433 "Valid Values" 432 "Valid Values" 431 "Valid Values" 430 "Valid Values" 429 "Valid Values" 428 "Valid Values" 427 "Valid Values" 426 "Valid Values" 425 "Valid Values" 424 "Valid Values" 423 "Valid Values" 422 "Valid Values" 421 "Valid Values" 420 "Valid Values" 419 "Valid Values" 418 "Valid Values" 417 "Valid Values" 416 "Valid Values" 415 "Valid Values" 414 "Valid Values" 413 "Valid Values" 412 "Valid Values" 411 "Valid Values" 410 "Valid Values" 409 "Valid Values" 408 "Valid Values" 407 "Valid Values" 406 "Valid Values" 405 "Valid Values" 404 "Valid Values" 403 "Valid Values" 402 "Valid Values" 401 "Valid Values" 400 "Valid Values" 399 "Valid Values" 398 "Valid Values" 397 "Valid Values" 396 "Valid Values" 395 "Valid Values" 394 "Valid Values" 393 "Valid Values" 392 "Valid Values" 391 "Valid Values" 390 "Valid Values" 389 "Valid Values" 388 "Valid Values" 387 "Valid Values" 386 "Valid Values" 385 "Valid Values" 384 "Valid Values" 383 "Valid Values" 382 "Valid Values" 381 "Valid Values" 380 "Valid Values" 379 "Valid Values" 378 "Valid Values" 377 "Valid Values" 376 "Valid Values" 375 "Valid Values" 374 "Valid Values" 373 "Valid Values" 372 "Valid Values" 371 "Valid Values" 370 "Valid Values" 369 "Valid Values" 368 "Valid Values" 367 "Valid Values" 366 "Valid Values" 365 "Valid Values" 364 "Valid Values" 363 "Valid Values" 362 "Valid Values" 361 "Valid Values" 360 "Valid Values" 359 "Valid Values" 358 "Valid Values" 357 "Valid Values" 356 "Valid Values" 355 "Valid Values" 354 "Valid Values" 353 "Valid Values" 352 "Valid Values" 351 "Valid Values" 350 "Valid Values" 349 "Valid Values" 348 "Valid Values" 347 "Valid Values" 346 "Valid Values" 345 "Valid Values" 344 "Valid Values" 343 "Valid Values" 342 "Valid Values" 341 "Valid Values" 340 "Valid Values" 339 "Valid Values" 338 "Valid Values" 337 "Valid Values" 336 "Valid Values" 335 "Valid Values" 334 "Valid Values" 333 "Valid Values" 332 "Valid Values" 331 "Valid Values" 330 "Valid Values" 329 "Valid Values" 328 "Valid Values" 327 "Valid Values" 326 "Valid Values" 325 "Valid Values" 324 "Valid Values" 323 "Valid Values" 322 "Valid Values" 321 "Valid Values" 320 "Valid Values" 319 "Valid Values" 318 "Valid Values" 317 "Valid Values" 316 "Valid Values" 315 "Valid Values" 314 "Valid Values" 313 "Valid Values" 312 "Valid Values" 311 "Valid Values" 310 "Valid Values" 309 "Valid Values" 308 "Valid Values" 307 "Valid Values" 306 "Valid Values" 305 "Valid Values" 304 "Valid Values" 303 "Valid Values" 302 "Valid Values" 301 "Valid Values" 300 "Valid Values" 299 "Valid Values" 298 "Valid Values" 297 "Valid Values" 296 "Valid Values" 295 "Valid Values" 294 "Valid Values" 293 "Valid Values" 292 "Valid Values" 291 "Valid Values" 290 "Valid Values" 289 "Valid Values" 288 "Valid Values" 287 "Valid Values" 286 "Valid Values" 285 "Valid Values" 284 "Valid Values" 283 "Valid Values" 282 "Valid Values" 281 "Valid Values" 280 "Valid Values" 279 "Valid Values" 278 "Valid Values" 277 "Valid Values" 276 "Valid Values" 275 "Valid Values" 274 "Valid Values" 273 "Valid Values" 272 "Valid Values" 271 "Valid Values" 270 "Valid Values" 269 "Valid Values" 268 "Valid Values" 267 "Valid Values" 266 "Valid Values" 265 "Valid Values" 264 "Valid Values" 263 "Valid Values" 262 "Valid Values" 261 "Valid Values" 260 "Valid Values" 259 "Valid Values" 258 "Valid Values" 257 "Valid Values" 256 "Valid Values" 255 "Valid Values" 254 "Valid Values" 253 "Valid Values" 252 "Valid Values" 251 "Valid Values" 250 "Valid Values" 249 "Valid Values" 248 "Valid Values" 247 "Valid Values" 246 "Valid Values" 245 "Valid Values" 244 "Valid Values" 243 "Valid Values" 242 "Valid Values" 241 "Valid Values" 240 "Valid Values" 239 "Valid Values" 238 "Valid Values" 237 "Valid Values" 236 "Valid Values" 235 "Valid Values" 234 "Valid Values" 233 "Valid Values" 232 "Valid Values" 231 "Valid Values" 230 "Valid Values" 229 "Valid Values" 228 "Valid Values" 227 "Valid Values" 226 "Valid Values" 225 "Valid Values" 224 "Valid Values" 223 "Valid Values" 222 "Valid Values" 221 "Valid Values" 220 "Valid Values" 219 "Valid Values" 218 "Valid Values" 217 "Valid Values" 216 "Valid Values" 215 "Valid Values" 214 "Valid Values" 213 "Valid Values" 212 "Valid Values" 211 "Valid Values" 210 "Valid Values" 209 "Valid Values" 208 "Valid Values" 207 "Valid Values" 206 "Valid Values" 205 "Valid Values" 204 "Valid Values" 203 "Valid Values" 202 "Valid Values" 201 "Valid Values" 200 "Valid Values" 199 "Valid Values" 198 "Valid Values" 197 "Valid Values" 196 "Valid Values" 195 "Valid Values" 194 "Valid Values" 193 "Valid Values" 192 "Valid Values" 191 "Valid Values" 190 "Valid Values" 189 "Valid Values" 188 "Valid Values" 187 "Valid Values" 186 "Valid Values" 185 "Valid Values" 184 "Valid Values" 183 "Valid Values" 182 "Valid Values" 181 "Valid Values" 180 "Valid Values" 179 "Valid Values" 178 "Valid Values" 177 "Valid Values" 176 "Valid Values" 175 "Valid Values" 174 "Valid Values" 173 "Valid Values" 172 "Valid Values" 171 "Valid Values" 170 "Valid Values" 169 "Valid Values" 168 "Valid Values" 167 "Valid Values" 166 "Valid Values" 165 "Valid Values" 164 "Valid Values" 163 "Valid Values" 162 "Valid Values" 161 "Valid Values" 160 "Valid Values" 159 "Valid Values" 158 "Valid Values" 157 "Valid Values" 156 "Valid Values" 155 "Valid Values" 154 "Valid Values" 153 "Valid Values" 152 "Valid Values" 151 "Valid Values" 150 "Valid Values" 149 "Valid Values" 148 "Valid Values" 147 "Valid Values" 146 "Valid Values" 145 "Valid Values" 144 "Valid Values" 143 "Valid Values" 142 "Valid Values" 141 "Valid Values" 140 "Valid Values" 139 "Valid Values" 138 "Valid Values" 137 "Valid Values" 136 "Valid Values" 135 "Valid Values" 134 "Valid Values" 133 "Valid Values" 132 "Valid Values" 131 "Valid Values" 130 "Valid Values" 129 "Valid Values" 128 "Valid Values" 127 "Valid Values" 126 "Valid Values" 125 "Valid Values" 124 "Valid Values" 123 "Valid Values" 122 "Valid Values" 121 "Valid Values" 120 "Valid Values" 119 "Valid Values" 118 "Valid Values" 117 "Valid Values" 116 "Valid Values" 115 "Valid Values" 114 "Valid Values" 113 "Valid Values" 112 "Valid Values" 111 "Valid Values" 110 "Valid Values" 109 "Valid Values" 108 "Valid Values" 107 "Valid Values" 106 "Valid Values" 105 "Valid Values" 104 "Valid Values" 103 "Valid Values" 102 "Valid Values" 101 "Valid Values" 100 "Valid Values" 99 "Valid Values" 98 "Valid Values" 97 "Valid Values" 96 "Valid Values" 95 "Valid Values" 94 "Valid Values" 93 "Valid Values" 92 "Valid Values" 91 "Valid Values" 90 "Valid Values" 89 "Valid Values" 88 "Valid Values" 87 "Valid Values" 86 "Valid Values" 85 "Valid Values" 84 "Valid Values" 83 "Valid Values" 82 "Valid Values" 81 "Valid Values" 80 "Valid Values" 79 "Valid Values" 78 "Valid Values" 77 "Valid Values" 76 "Valid Values" 75 "Valid Values" 74 "Valid Values" 73 "Valid Values" 72 "Valid Values" 71 "Valid Values" 70 "Valid Values" 69 "Valid Values" 68 "Valid Values" 67 "Valid Values" 66 "Valid Values" 65 "Valid Values" 64 "Valid Values" 63 "Valid Values" 62 "Valid Values" 61 "Valid Values" 60 "Valid Values" 59 "Valid Values" 58 "Valid Values" 57 "Valid Values" 56 "Valid Values" 55 "Valid Values" 54 "Valid Values" 53 "Valid Values" 52 "Valid Values" 51 "Valid Values" 50 "Valid Values" 49 "Valid Values" 48 "Valid Values" 47 "Valid Values" 46 "Valid Values" 45 "Valid Values" 44 "Valid Values" 43 "Valid Values" 42 "Valid Values" 41 "Valid Values" 40 "Valid Values" 39 "Valid Values" 38 "Valid Values" 37 "Valid Values" 36 "Valid Values" 35 "Valid Values" 34 "Valid Values" 33 "Valid Values" 32 "Valid Values" 31 "Valid Values" 30 "Valid Values" 29 "Valid Values" 28 "Valid Values" 27 "Valid Values" 26 "Valid Values" 25 "Valid Values" 24 "Valid Values" 23 "Valid Values" 22 "Valid Values" 21 "Valid Values" 20 "Valid Values" 19 "Valid Values" 18 "Valid Values" 17 "Valid Values" 16 "Valid Values" 15 "Valid Values" 14 "Valid Values" 13 "Valid Values" 12 "Valid Values" 11 "Valid Values" 10 "Valid Values" 9 "Valid Values" 8 "Valid Values" 7 "Valid Values" 6 "Valid Values" 5 "Valid Values" 4 "Valid Values" 3 "Valid Values" 2 "Valid Values" 1 "Valid Values" 0 "Valid Values" ;
